VERSION "HNNBNNNYNNNNNNNNNNNNNNNNNNNNNNNNNNNNNNNNNN/4/%%%/4/'%**4NNN///"

NS_ :

BS_:

BU_: ICAS1_Gateway ICAS1_KommunikationsServer MFL_CAN

BO_ 3221225472 VECTOR__INDEPENDENT_SIG_MSG: 0 Vector__XXX
 SG_ MFL_Develop_Release : 0|3@1+ (1,0) [0|7] "" Vector__XXX
 SG_ MFL_Develop_Variant : 0|2@1+ (1,0) [0|3] "" Vector__XXX

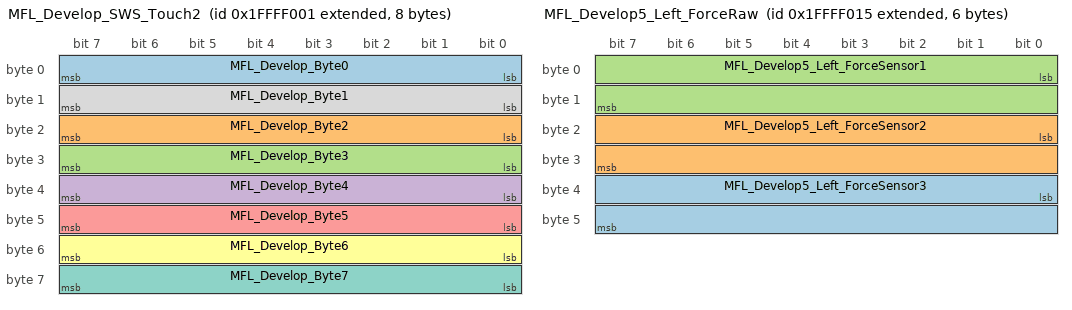
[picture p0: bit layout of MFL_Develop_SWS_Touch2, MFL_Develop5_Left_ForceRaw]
BO_ 2684350465 MFL_Develop_SWS_Touch2: 8 MFL_CAN
 SG_ MFL_Develop_Byte0 : 0|8@1+ (1,0) [0|255] ""  ICAS1_Gateway
 SG_ MFL_Develop_Byte2 : 16|8@1+ (1,0) [0|255] ""  ICAS1_Gateway
 SG_ MFL_Develop_Byte3 : 24|8@1+ (1,0) [0|255] ""  ICAS1_Gateway
 SG_ MFL_Develop_Byte4 : 32|8@1+ (1,0) [0|255] ""  ICAS1_Gateway
 SG_ MFL_Develop_Byte5 : 40|8@1+ (1,0) [0|255] ""  ICAS1_Gateway
 SG_ MFL_Develop_Byte6 : 48|8@1+ (1,0) [0|255] ""  ICAS1_Gateway
 SG_ MFL_Develop_Byte7 : 56|8@1+ (1,0) [0|255] ""  ICAS1_Gateway
 SG_ MFL_Develop_Byte1 : 8|8@1+ (1,0) [0|255] ""  ICAS1_Gateway

BO_ 2684350485 MFL_Develop5_Left_ForceRaw: 6 MFL_CAN
 SG_ MFL_Develop5_Left_ForceSensor3 : 32|16@1+ (1,0) [0|65535] "" Vector__XXX
 SG_ MFL_Develop5_Left_ForceSensor2 : 16|16@1+ (1,0) [0|65535] "" Vector__XXX
 SG_ MFL_Develop5_Left_ForceSensor1 : 0|16@1+ (1,0) [0|65535] "" Vector__XXX

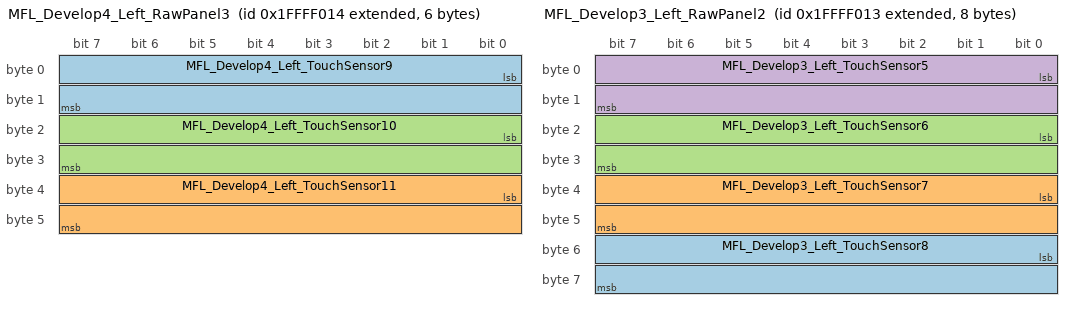
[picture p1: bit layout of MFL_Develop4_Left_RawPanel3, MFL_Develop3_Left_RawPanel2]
BO_ 2684350484 MFL_Develop4_Left_RawPanel3: 6 MFL_CAN
 SG_ MFL_Develop4_Left_TouchSensor9 : 0|16@1+ (1,0) [0|65535] "" Vector__XXX
 SG_ MFL_Develop4_Left_TouchSensor11 : 32|16@1+ (1,0) [0|65535] "" Vector__XXX
 SG_ MFL_Develop4_Left_TouchSensor10 : 16|16@1+ (1,0) [0|65535] "" Vector__XXX

BO_ 2684350483 MFL_Develop3_Left_RawPanel2: 8 MFL_CAN
 SG_ MFL_Develop3_Left_TouchSensor8 : 48|16@1+ (1,0) [0|65535] "" Vector__XXX
 SG_ MFL_Develop3_Left_TouchSensor7 : 32|16@1+ (1,0) [0|65535] "" Vector__XXX
 SG_ MFL_Develop3_Left_TouchSensor6 : 16|16@1+ (1,0) [0|65535] "" Vector__XXX
 SG_ MFL_Develop3_Left_TouchSensor5 : 0|16@1+ (1,0) [0|65535] "" Vector__XXX

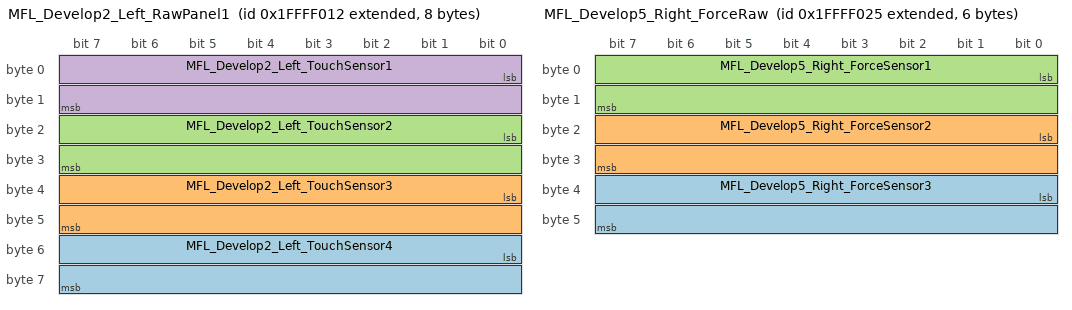
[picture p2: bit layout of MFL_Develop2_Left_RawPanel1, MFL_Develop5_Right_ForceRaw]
BO_ 2684350482 MFL_Develop2_Left_RawPanel1: 8 MFL_CAN
 SG_ MFL_Develop2_Left_TouchSensor4 : 48|16@1+ (1,0) [0|65535] "" Vector__XXX
 SG_ MFL_Develop2_Left_TouchSensor3 : 32|16@1+ (1,0) [0|65535] "" Vector__XXX
 SG_ MFL_Develop2_Left_TouchSensor2 : 16|16@1+ (1,0) [0|65535] "" Vector__XXX
 SG_ MFL_Develop2_Left_TouchSensor1 : 0|16@1+ (1,0) [0|65535] "" Vector__XXX

BO_ 2684350501 MFL_Develop5_Right_ForceRaw: 6 MFL_CAN
 SG_ MFL_Develop5_Right_ForceSensor3 : 32|16@1+ (1,0) [0|65535] "" Vector__XXX
 SG_ MFL_Develop5_Right_ForceSensor2 : 16|16@1+ (1,0) [0|65535] "" Vector__XXX
 SG_ MFL_Develop5_Right_ForceSensor1 : 0|16@1+ (1,0) [0|65535] "" Vector__XXX

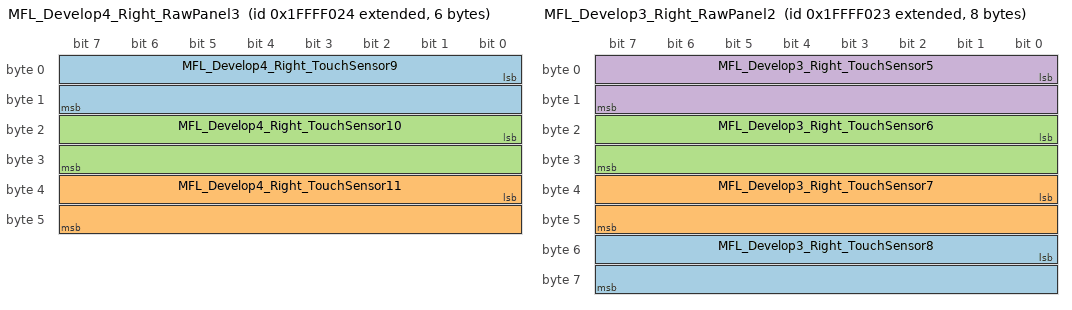
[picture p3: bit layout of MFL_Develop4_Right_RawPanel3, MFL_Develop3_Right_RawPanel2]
BO_ 2684350500 MFL_Develop4_Right_RawPanel3: 6 MFL_CAN
 SG_ MFL_Develop4_Right_TouchSensor9 : 0|16@1+ (1,0) [0|65535] "" Vector__XXX
 SG_ MFL_Develop4_Right_TouchSensor11 : 32|16@1+ (1,0) [0|65535] "" Vector__XXX
 SG_ MFL_Develop4_Right_TouchSensor10 : 16|16@1+ (1,0) [0|65535] "" Vector__XXX

BO_ 2684350499 MFL_Develop3_Right_RawPanel2: 8 MFL_CAN
 SG_ MFL_Develop3_Right_TouchSensor8 : 48|16@1+ (1,0) [0|65535] "" Vector__XXX
 SG_ MFL_Develop3_Right_TouchSensor7 : 32|16@1+ (1,0) [0|65535] "" Vector__XXX
 SG_ MFL_Develop3_Right_TouchSensor6 : 16|16@1+ (1,0) [0|65535] "" Vector__XXX
 SG_ MFL_Develop3_Right_TouchSensor5 : 0|16@1+ (1,0) [0|65535] "" Vector__XXX

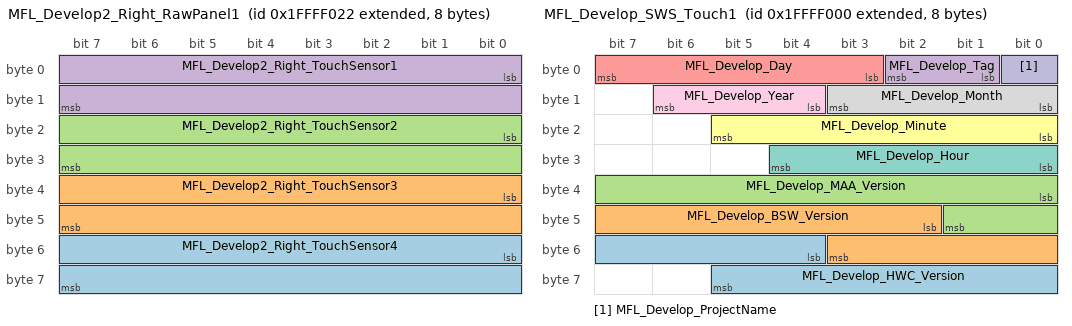
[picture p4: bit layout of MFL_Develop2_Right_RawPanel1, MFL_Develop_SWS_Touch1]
BO_ 2684350498 MFL_Develop2_Right_RawPanel1: 8 MFL_CAN
 SG_ MFL_Develop2_Right_TouchSensor4 : 48|16@1+ (1,0) [0|65535] "" Vector__XXX
 SG_ MFL_Develop2_Right_TouchSensor3 : 32|16@1+ (1,0) [0|65535] "" Vector__XXX
 SG_ MFL_Develop2_Right_TouchSensor2 : 16|16@1+ (1,0) [0|65535] "" Vector__XXX
 SG_ MFL_Develop2_Right_TouchSensor1 : 0|16@1+ (1,0) [0|65535] "" Vector__XXX

BO_ 2684350496 MFL_Develop1_SetPicState: 2 Vector__XXX
 SG_ MFL_Develop1_Left_PicState : 8|8@1+ (1,0) [0|4] ""  MFL_CAN
 SG_ MFL_Develop1_Right_PicState : 0|8@1+ (1,0) [0|4] ""  MFL_CAN

BO_ 2566664449 XCP_DTO_01: 8 MFL_CAN
 SG_ XCP_DTO_01_val : 0|64@1+ (1,0) [0|1.84467440737096E+019] "" Vector__XXX

BO_ 2566664448 XCP_CRO_01: 8 ICAS1_Gateway
 SG_ XCP_CRO_01_val : 0|64@1+ (1,0) [0|1.84467440737096E+019] ""  MFL_CAN

BO_ 2684350464 MFL_Develop_SWS_Touch1: 8 MFL_CAN
 SG_ MFL_Develop_HWC_Version : 52|10@1+ (1,0) [0|1023] "" Vector__XXX
 SG_ MFL_Develop_BSW_Version : 42|10@1+ (1,0) [0|1023] "" Vector__XXX
 SG_ MFL_Develop_MAA_Version : 32|10@1+ (1,0) [0|1023] "" Vector__XXX
 SG_ MFL_Develop_Tag : 1|2@1+ (1,0) [0|3] "" Vector__XXX
 SG_ MFL_Develop_Day : 3|5@1+ (1,0) [0|31] ""  ICAS1_Gateway
 SG_ MFL_Develop_Minute : 16|6@1+ (1,0) [0|61] ""  ICAS1_Gateway
 SG_ MFL_Develop_Hour : 24|5@1+ (1,0) [0|24] ""  ICAS1_Gateway
 SG_ MFL_Develop_Month : 8|4@1+ (1,0) [0|12] ""  ICAS1_Gateway
 SG_ MFL_Develop_Year : 12|3@1+ (1,0) [0|7] ""  ICAS1_Gateway
 SG_ MFL_Develop_ProjectName : 0|1@1+ (1,0) [0|1] ""  ICAS1_Gateway

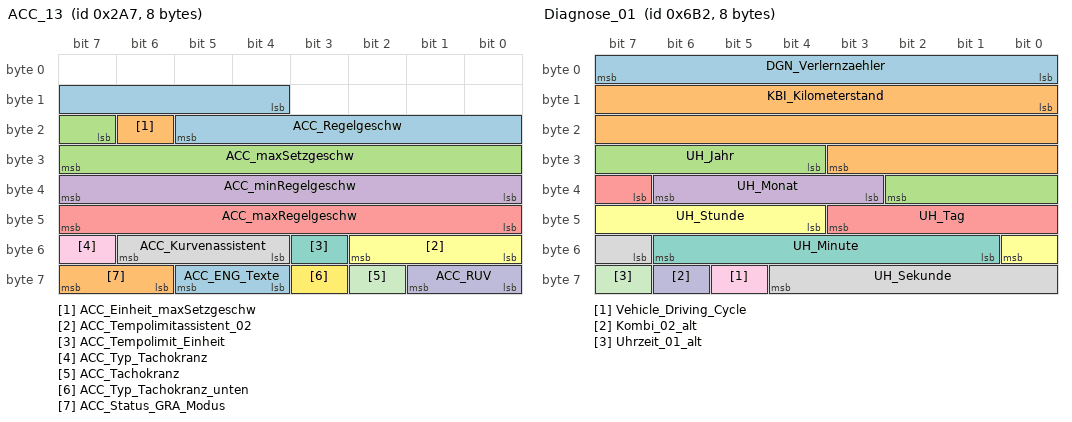
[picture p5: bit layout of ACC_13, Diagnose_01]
BO_ 679 ACC_13: 8 ICAS1_Gateway
 SG_ ACC_Regelgeschw : 12|10@1+ (0.32,0) [0|327.04] "Unit_KiloMeterPerHour" Vector__XXX
 SG_ ACC_Einheit_maxSetzgeschw : 22|1@1+ (1,0) [0|1] "" Vector__XXX
 SG_ ACC_maxSetzgeschw : 23|9@1+ (1,0) [0|510] "" Vector__XXX
 SG_ ACC_minRegelgeschw : 32|8@1+ (0.32,0) [0|81.28] "Unit_KiloMeterPerHour" Vector__XXX
 SG_ ACC_maxRegelgeschw : 40|8@1+ (0.32,0) [0|81.28] "Unit_KiloMeterPerHour" Vector__XXX
 SG_ ACC_Tempolimitassistent_02 : 48|3@1+ (1,0) [0|7] "" Vector__XXX
 SG_ ACC_Tempolimit_Einheit : 51|1@1+ (1,0) [0|1] "" Vector__XXX
 SG_ ACC_Kurvenassistent : 52|3@1+ (1,0) [0|7] "" Vector__XXX
 SG_ ACC_Typ_Tachokranz : 55|1@1+ (1,0) [0|1] "" Vector__XXX
 SG_ ACC_RUV : 56|2@1+ (1,0) [0|3] "" Vector__XXX
 SG_ ACC_Tachokranz : 58|1@1+ (1,0) [0|1] "" Vector__XXX
 SG_ ACC_Typ_Tachokranz_unten : 59|1@1+ (1,0) [0|1] "" Vector__XXX
 SG_ ACC_ENG_Texte : 60|2@1+ (1,0) [0|3] "" Vector__XXX
 SG_ ACC_Status_GRA_Modus : 62|2@1+ (1,0) [0|3] ""  MFL_CAN

BO_ 680 ACC_14: 8 ICAS1_Gateway
 SG_ ACA_Querfuehrung_Texte : 0|3@1+ (1,0) [0|7] "" Vector__XXX
 SG_ ACA_Hinweistexte : 3|3@1+ (1,0) [0|7] "" Vector__XXX
 SG_ ACC_FoD_Status : 6|2@1+ (1,0) [0|3] ""  MFL_CAN
 SG_ ACC_Texte_Abstandswarner : 8|2@1+ (1,0) [0|3] "" Vector__XXX
 SG_ ACC_Vorz_Abstandswarner : 10|2@1+ (1,0) [0|3] "" Vector__XXX
 SG_ ACC_Texte_Sekundaeranz : 12|4@1+ (1,0) [0|15] "" Vector__XXX
 SG_ ACC_Status_Anzeige : 16|3@1+ (1,0) [0|7] "" Vector__XXX
 SG_ ACC_Akustik_03 : 19|3@1+ (1,0) [0|7] "" Vector__XXX
 SG_ ACC_Geschw_Zielfahrzeug : 22|10@1+ (0.32,0) [0|326.72] "Unit_KiloMeterPerHour" Vector__XXX
 SG_ ACC_Texte_02 : 32|6@1+ (1,0) [0|63] "" Vector__XXX
 SG_ ACC_STA_Text : 38|1@1+ (1,0) [0|1] "" Vector__XXX
 SG_ ACC_Status_Stauende : 39|1@1+ (1,0) [0|1] "" Vector__XXX
 SG_ STA_Texte : 40|3@1+ (1,0) [0|7] "" Vector__XXX
 SG_ AbstWarn_LRR_FAS_Fkt_Status : 43|2@1+ (1,0) [0|3] "" Vector__XXX
 SG_ STA_Zusatzanz : 45|2@1+ (1,0) [0|3] "" Vector__XXX
 SG_ FAS_Licht_Anf : 47|1@1+ (1,0) [0|1] "" Vector__XXX
 SG_ ACC_Zeitluecke_Abstandswarner : 48|6@1+ (0.1,0) [0|6] "Unit_Secon" Vector__XXX
 SG_ ACC_Abstand_Abstandswarner : 54|9@1+ (1,0) [0|508] "" Vector__XXX
 SG_ ACC_Einheit_Abstandswarner : 63|1@1+ (1,0) [0|1] "" Vector__XXX

BO_ 2549880369 DIA_MFL_Req: 8 ICAS1_Gateway
 SG_ DIA_MFL_Req_Data : 0|64@1+ (1,0) [0|1.84467440737096E+019] ""  MFL_CAN

BO_ 2550011441 DIA_MFL_Resp: 8 MFL_CAN
 SG_ DIA_MFL_Resp_Data : 0|64@1+ (1,0) [0|1.84467440737096E+019] ""  ICAS1_Gateway

BO_ 2549876273 Diag_MFL_Req: 8 ICAS1_Gateway
 SG_ Diag_MFL_Req_Data : 0|64@1+ (1,0) [0|1.84467440737096E+019] ""  MFL_CAN

BO_ 2550007345 Diag_MFL_Resp: 8 MFL_CAN
 SG_ Diag_MFL_Resp_Data : 0|64@1+ (1,0) [0|1.84467440737096E+019] ""  ICAS1_Gateway

BO_ 1714 Diagnose_01: 8 ICAS1_Gateway
 SG_ DGN_Verlernzaehler : 0|8@1+ (1,0) [0|254] "" Vector__XXX
 SG_ KBI_Kilometerstand : 8|20@1+ (1,0) [0|1048573] "Unit_KiloMeter" Vector__XXX
 SG_ UH_Jahr : 28|7@1+ (1,2000) [2000|2127] "Unit_Year" Vector__XXX
 SG_ UH_Monat : 35|4@1+ (1,0) [1|12] "Unit_Month" Vector__XXX
 SG_ UH_Tag : 39|5@1+ (1,0) [1|31] "Unit_Day" Vector__XXX
 SG_ UH_Stunde : 44|5@1+ (1,0) [0|23] "Unit_Hours" Vector__XXX
 SG_ UH_Minute : 49|6@1+ (1,0) [0|59] "Unit_Minut" Vector__XXX
 SG_ UH_Sekunde : 55|6@1+ (1,0) [0|59] "Unit_Secon" Vector__XXX
 SG_ Vehicle_Driving_Cycle : 61|1@1+ (1,0) [0|1] "" Vector__XXX
 SG_ Kombi_02_alt : 62|1@1+ (1,0) [0|1] "" Vector__XXX
 SG_ Uhrzeit_01_alt : 63|1@1+ (1,0) [0|1] "" Vector__XXX

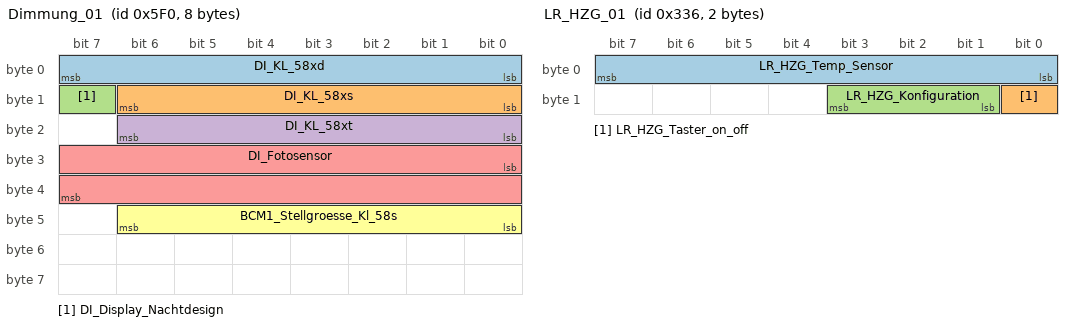
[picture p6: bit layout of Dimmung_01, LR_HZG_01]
BO_ 1520 Dimmung_01: 8 ICAS1_Gateway
 SG_ DI_KL_58xd : 0|8@1+ (1,0) [0|253] ""  MFL_CAN
 SG_ DI_KL_58xs : 8|7@1+ (1,0) [0|100] "Unit_PerCent" Vector__XXX
 SG_ DI_Display_Nachtdesign : 15|1@1+ (1,0) [0|1] "" Vector__XXX
 SG_ DI_KL_58xt : 16|7@1+ (1,0) [0|100] "Unit_PerCent"  MFL_CAN
 SG_ DI_Fotosensor : 24|16@1+ (1,0) [0|65535] "" Vector__XXX
 SG_ BCM1_Stellgroesse_Kl_58s : 40|7@1+ (1,0) [0|100] "" Vector__XXX

BO_ 988 Gateway_73: 8 ICAS1_Gateway
 SG_ Motor_12_alt : 0|1@1+ (1,0) [0|1] "" Vector__XXX
 SG_ ESP_07_alt : 1|1@1+ (1,0) [0|1] "" Vector__XXX
 SG_ Getriebe_11_alt : 2|1@1+ (1,0) [0|1] "" Vector__XXX
 SG_ Getriebe_13_alt : 3|1@1+ (1,0) [0|1] "" Vector__XXX
 SG_ Getriebe_17_alt : 4|1@1+ (1,0) [0|1] "" Vector__XXX
 SG_ TSK_06_alt : 5|1@1+ (1,0) [0|1] ""  MFL_CAN
 SG_ Getriebe_14_alt : 6|1@1+ (1,0) [0|1] "" Vector__XXX
 SG_ ESP_50_alt : 7|1@1+ (1,0) [0|1] "" Vector__XXX
 SG_ MO_QBit_Drehzahl_01 : 8|1@1+ (1,0) [0|1] "" Vector__XXX
 SG_ MKE_Texte : 9|2@1+ (1,0) [0|3] "" Vector__XXX
 SG_ MKE_Stufe : 11|3@1+ (1,0) [0|7] "" Vector__XXX
 SG_ TSK_Hauptschalter_GRA_ACC : 14|2@1+ (1,0) [0|3] ""  MFL_CAN
 SG_ MO_Drehzahl_01 : 16|16@1+ (0.25,0) [0|16383] "Unit_MinutInver" Vector__XXX
 SG_ GE_Fahrstufe : 40|4@1+ (1,0) [0|15] "" Vector__XXX
 SG_ GE_Ursache_Fahrstufe_N : 44|1@1+ (1,0) [0|1] "" Vector__XXX
 SG_ GE_Notlauf : 45|1@1+ (1,0) [0|1] "" Vector__XXX
 SG_ ESP_Rollenmodus_Deaktivieren : 46|1@1+ (1,0) [0|1] "" Vector__XXX
 SG_ GE_Freilauf_Status : 47|3@1+ (1,0) [0|7] "" Vector__XXX
 SG_ GE_Sperr_Info_WFS : 50|1@1+ (1,0) [0|1] "" Vector__XXX
 SG_ TSK_Limiter_ausgewaehlt : 51|1@1+ (1,0) [0|1] ""  MFL_CAN
 SG_ EPB_Status_02 : 53|3@1+ (1,0) [0|7] "" Vector__XXX
 SG_ ACC_Status_ACC : 56|3@1+ (1,0) [0|7] "" Vector__XXX
 SG_ ACC_18_alt : 59|1@1+ (1,0) [0|1] "" Vector__XXX
 SG_ ESP_Status_Bremsentemp_02 : 62|2@1+ (1,0) [0|3] "" Vector__XXX

BO_ 299 GRA_ACC_01: 8 MFL_CAN
 SG_ GRA_ACC_01_CRC : 0|8@1+ (1,0) [0|255] ""  ICAS1_Gateway
 SG_ GRA_ACC_01_BZ : 8|4@1+ (1,0) [0|15] ""  ICAS1_Gateway
 SG_ GRA_Hauptschalter : 12|1@1+ (1,0) [0|1] ""  ICAS1_Gateway
 SG_ GRA_Abbrechen : 13|1@1+ (1,0) [0|1] ""  ICAS1_Gateway
 SG_ GRA_Typ_Hauptschalter : 14|1@1+ (1,0) [0|1] ""  ICAS1_Gateway
 SG_ GRA_Limiter : 15|1@1+ (1,0) [0|1] ""  ICAS1_Gateway
 SG_ GRA_Tip_Setzen : 16|1@1+ (1,0) [0|1] ""  ICAS1_Gateway
 SG_ GRA_Tip_Hoch : 17|1@1+ (1,0) [0|1] ""  ICAS1_Gateway
 SG_ GRA_Tip_Runter : 18|1@1+ (1,0) [0|1] ""  ICAS1_Gateway
 SG_ GRA_Tip_Wiederaufnahme : 19|1@1+ (1,0) [0|1] ""  ICAS1_Gateway
 SG_ GRA_Verstellung_Zeitluecke : 20|2@1+ (1,0) [0|3] ""  ICAS1_Gateway
 SG_ GRA_Codierung : 22|2@1+ (1,0) [0|3] ""  ICAS1_Gateway
 SG_ GRA_Fehler : 24|1@1+ (1,0) [0|1] ""  ICAS1_Gateway
 SG_ GRA_LIM_Taste_verfuegbar : 25|1@1+ (1,0) [0|1] ""  ICAS1_Gateway,ICAS1_KommunikationsServer
 SG_ GRA_Tip_Stufe_2 : 26|1@1+ (1,0) [0|1] ""  ICAS1_Gateway
 SG_ GRA_Typ_Bedienteil : 27|3@1+ (1,0) [0|7] ""  ICAS1_Gateway
 SG_ GRA_TravelAssist : 30|1@1+ (1,0) [0|1] ""  ICAS1_Gateway
 SG_ GRA_reserveByte4 : 31|1@1+ (1,0) [0|1] ""  ICAS1_Gateway
 SG_ GRA_reserveByte5 : 32|8@1+ (1,0) [0|255] ""  ICAS1_Gateway
 SG_ GRA_reserveByte6 : 40|8@1+ (1,0) [0|255] ""  ICAS1_Gateway
 SG_ GRA_reserveByte7 : 48|8@1+ (1,0) [0|255] ""  ICAS1_Gateway
 SG_ GRA_reserveByte8 : 56|8@1+ (1,0) [0|255] ""  ICAS1_Gateway

BO_ 960 Klemmen_Status_01: 4 ICAS1_Gateway
 SG_ Klemmen_Status_01_CRC : 0|8@1+ (1,0) [0|255] "" Vector__XXX
 SG_ Klemmen_Status_01_BZ : 8|4@1+ (1,0) [0|15] "" Vector__XXX
 SG_ RSt_Fahrerhinweise : 12|4@1+ (1,0) [0|15] "" Vector__XXX
 SG_ ZAS_Kl_S : 16|1@1+ (1,0) [0|1] "" Vector__XXX
 SG_ ZAS_Kl_15 : 17|1@1+ (1,0) [0|1] ""  MFL_CAN
 SG_ ZAS_Kl_X : 18|1@1+ (1,0) [0|1] "" Vector__XXX
 SG_ ZAS_Kl_50_Startanforderung : 19|1@1+ (1,0) [0|1] "" Vector__XXX
 SG_ BCM_Remotestart_Betrieb : 20|1@1+ (1,0) [0|1] "" Vector__XXX
 SG_ ZAS_Kl_Infotainment : 21|1@1+ (1,0) [0|1] "" Vector__XXX
 SG_ BCM_Remotestart_KL15_Anf : 22|1@1+ (1,0) [0|1] "" Vector__XXX
 SG_ BCM_Remotestart_MO_Start : 23|1@1+ (1,0) [0|1] "" Vector__XXX
 SG_ KST_Warn_P1_ZST_def : 24|1@1+ (1,0) [0|1] "" Vector__XXX
 SG_ KST_Warn_P2_ZST_def : 25|1@1+ (1,0) [0|1] "" Vector__XXX
 SG_ KST_Fahrerhinweis_1 : 26|1@1+ (1,0) [0|1] "" Vector__XXX
 SG_ KST_Fahrerhinweis_2 : 27|1@1+ (1,0) [0|1] "" Vector__XXX
 SG_ BCM_Ausparken_Betrieb : 28|1@1+ (1,0) [0|1] "" Vector__XXX
 SG_ KST_Fahrerhinweis_4 : 29|1@1+ (1,0) [0|1] "" Vector__XXX
 SG_ KST_Fahrerhinweis_5 : 30|1@1+ (1,0) [0|1] "" Vector__XXX
 SG_ KST_Fahrerhinweis_6 : 31|1@1+ (1,0) [0|1] "" Vector__XXX

BO_ 822 LR_HZG_01: 2 MFL_CAN
 SG_ LR_HZG_Temp_Sensor : 0|8@1+ (1,-50) [-50|104] "Unit_DegreCelsi"  ICAS1_Gateway
 SG_ LR_HZG_Taster_on_off : 8|1@1+ (1,0) [0|1] ""  ICAS1_Gateway
 SG_ LR_HZG_Konfiguration : 9|3@1+ (1,0) [0|7] ""  ICAS1_Gateway

BO_ 817 MFL_01: 8 MFL_CAN
 SG_ MFL_Zaehler : 0|4@1+ (1,0) [0|15] ""  ICAS1_Gateway
 SG_ MFL_Toggle : 4|1@1+ (1,0) [0|1] ""  ICAS1_Gateway
 SG_ MFL_Lokalaktiv : 5|1@1+ (1,0) [0|1] ""  ICAS1_Gateway
 SG_ MFL_M_Taste : 6|1@1+ (1,0) [0|1] ""  ICAS1_Gateway
 SG_ MFL_Paddle_Verbau : 7|1@1+ (1,0) [0|1] ""  ICAS1_Gateway
 SG_ MFL_Tastencode_1 : 8|8@1+ (1,0) [0|255] ""  ICAS1_Gateway
 SG_ MFL_Tastencode_2 : 16|8@1+ (1,0) [0|255] ""  ICAS1_Gateway
 SG_ MFL_Eventcode_1 : 24|4@1+ (1,0) [0|15] ""  ICAS1_Gateway
 SG_ MFL_Eventcode_2 : 28|4@1+ (1,0) [0|15] ""  ICAS1_Gateway
 SG_ MFL_Marke : 32|4@1+ (1,0) [0|15] ""  ICAS1_Gateway
 SG_ MFL_Variante : 36|4@1+ (1,0) [0|15] ""  ICAS1_Gateway
 SG_ MFL_Dummy_0_Signal_1 : 40|8@1+ (1,0) [0|255] ""  ICAS1_Gateway
 SG_ MFL_Tip_Down : 48|1@1+ (1,0) [0|1] ""  ICAS1_Gateway
 SG_ MFL_Tip_Up : 49|1@1+ (1,0) [0|1] ""  ICAS1_Gateway
 SG_ MFL_SatModul_links_Err : 50|1@1+ (1,0) [0|1] ""  ICAS1_Gateway
 SG_ MFL_SatModul_rechts_Err : 51|1@1+ (1,0) [0|1] ""  ICAS1_Gateway
 SG_ MFL_Dummy_0_Signal_2 : 52|1@1+ (1,0) [0|1] ""  ICAS1_Gateway
 SG_ MFL_Dummy_0_Signal_3 : 53|1@1+ (1,0) [0|1] ""  ICAS1_Gateway
 SG_ MFL_LR_HZG_Status : 54|1@1+ (1,0) [0|1] ""  ICAS1_Gateway
 SG_ MFL_LR_HZG_Err : 55|1@1+ (1,0) [0|1] ""  ICAS1_Gateway
 SG_ MFL_Signalhorn : 56|1@1+ (1,0) [0|1] ""  ICAS1_Gateway
 SG_ MFL_Signalhorn_Err : 57|1@1+ (1,0) [0|1] ""  ICAS1_Gateway
 SG_ MFL_Tip_links_Err : 58|1@1+ (1,0) [0|1] ""  ICAS1_Gateway
 SG_ MFL_Tip_rechts_Err : 59|1@1+ (1,0) [0|1] ""  ICAS1_Gateway
 SG_ MFL_Taste_links_Err : 60|1@1+ (1,0) [0|1] ""  ICAS1_Gateway
 SG_ MFL_Taste_rechts_Err : 61|1@1+ (1,0) [0|1] ""  ICAS1_Gateway
 SG_ MFL_ECU_Err : 62|1@1+ (1,0) [0|1] ""  ICAS1_Gateway
 SG_ MFL_Response_Err : 63|1@1+ (1,0) [0|1] ""  ICAS1_Gateway

BO_ 560 MFL_02: 8 MFL_CAN
 SG_ MFL_Beruehrungserkennung : 12|2@1+ (1,0) [0|3] ""  ICAS1_Gateway

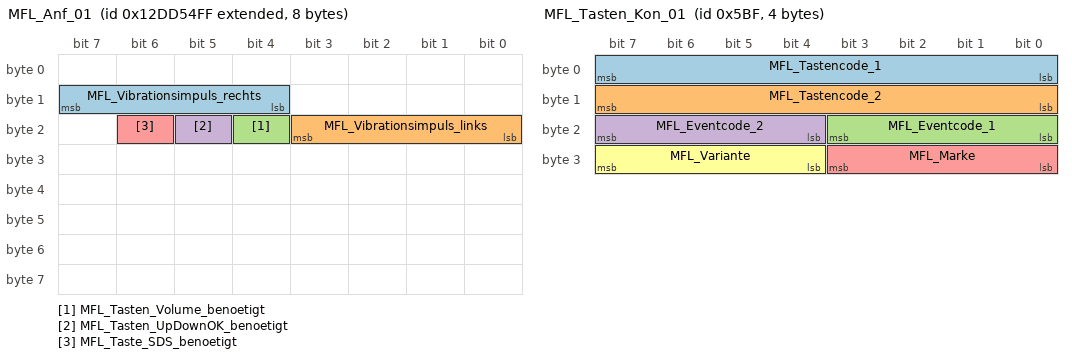
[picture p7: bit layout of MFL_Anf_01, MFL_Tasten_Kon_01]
BO_ 2463978751 MFL_Anf_01: 8 ICAS1_Gateway
 SG_ MFL_Vibrationsimpuls_rechts : 12|4@1+ (1,0) [0|15] ""  MFL_CAN
 SG_ MFL_Vibrationsimpuls_links : 16|4@1+ (1,0) [0|15] ""  MFL_CAN
 SG_ MFL_Tasten_Volume_benoetigt : 20|1@1+ (1,0) [0|1] ""  MFL_CAN
 SG_ MFL_Tasten_UpDownOK_benoetigt : 21|1@1+ (1,0) [0|1] ""  MFL_CAN
 SG_ MFL_Taste_SDS_benoetigt : 22|1@1+ (1,0) [0|1] ""  MFL_CAN

BO_ 1471 MFL_Tasten_Kon_01: 4 MFL_CAN
 SG_ MFL_Tastencode_1 : 0|8@1+ (1,0) [0|255] ""  ICAS1_Gateway
 SG_ MFL_Tastencode_2 : 8|8@1+ (1,0) [0|255] ""  ICAS1_Gateway
 SG_ MFL_Eventcode_1 : 16|4@1+ (1,0) [0|15] ""  ICAS1_Gateway
 SG_ MFL_Eventcode_2 : 20|4@1+ (1,0) [0|15] ""  ICAS1_Gateway
 SG_ MFL_Marke : 24|4@1+ (1,0) [0|15] ""  ICAS1_Gateway
 SG_ MFL_Variante : 28|4@1+ (1,0) [0|15] ""  ICAS1_Gateway

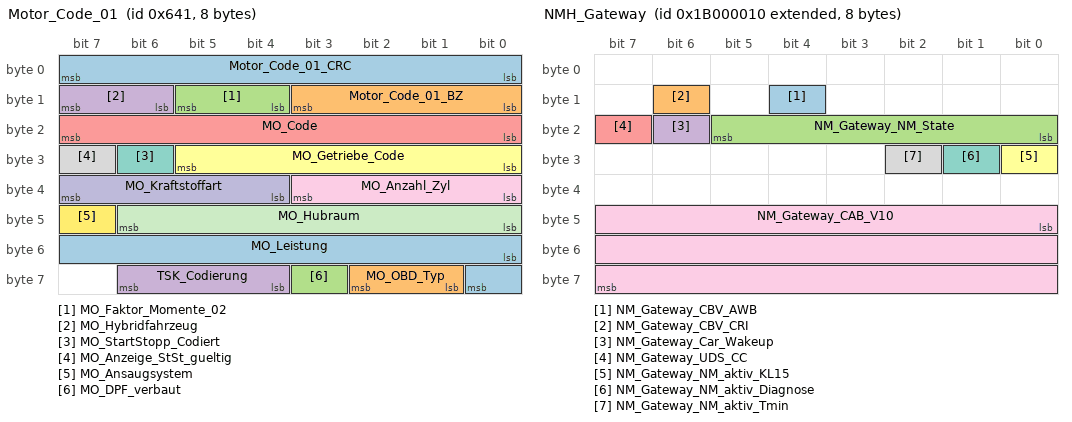
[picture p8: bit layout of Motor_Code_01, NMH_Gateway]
BO_ 1601 Motor_Code_01: 8 ICAS1_Gateway
 SG_ Motor_Code_01_CRC : 0|8@1+ (1,0) [0|255] "" Vector__XXX
 SG_ Motor_Code_01_BZ : 8|4@1+ (1,0) [0|15] "" Vector__XXX
 SG_ MO_Faktor_Momente_02 : 12|2@1+ (1,0) [1|3] "Unit_NewtoMeter" Vector__XXX
 SG_ MO_Hybridfahrzeug : 14|2@1+ (1,0) [0|3] "" Vector__XXX
 SG_ MO_Code : 16|8@1+ (1,0) [0|255] "" Vector__XXX
 SG_ MO_Getriebe_Code : 24|6@1+ (1,0) [0|63] "" Vector__XXX
 SG_ MO_StartStopp_Codiert : 30|1@1+ (1,0) [0|1] "" Vector__XXX
 SG_ MO_Anzeige_StSt_gueltig : 31|1@1+ (1,0) [0|1] "" Vector__XXX
 SG_ MO_Anzahl_Zyl : 32|4@1+ (1,0) [0|15] "" Vector__XXX
 SG_ MO_Kraftstoffart : 36|4@1+ (1,0) [0|15] "" Vector__XXX
 SG_ MO_Hubraum : 40|7@1+ (0.1,0) [0|12.7] "Unit_Liter" Vector__XXX
 SG_ MO_Ansaugsystem : 47|1@1+ (1,0) [0|1] "" Vector__XXX
 SG_ MO_Leistung : 48|9@1+ (1,0) [0|511] "Unit_KiloWatt" Vector__XXX
 SG_ MO_OBD_Typ : 57|2@1+ (1,0) [0|3] "" Vector__XXX
 SG_ MO_DPF_verbaut : 59|1@1+ (1,0) [0|1] "" Vector__XXX
 SG_ TSK_Codierung : 60|3@1+ (1,0) [0|7] ""  MFL_CAN

BO_ 2600468496 NMH_Gateway: 8 ICAS1_Gateway
 SG_ NM_Gateway_CBV_AWB : 12|1@1+ (1,0) [0|1] "" Vector__XXX
 SG_ NM_Gateway_CBV_CRI : 14|1@1+ (1,0) [0|1] "" Vector__XXX
 SG_ NM_Gateway_NM_State : 16|6@1+ (1,0) [0|63] ""  MFL_CAN
 SG_ NM_Gateway_Car_Wakeup : 22|1@1+ (1,0) [0|1] "" Vector__XXX
 SG_ NM_Gateway_UDS_CC : 23|1@1+ (1,0) [0|1] "" Vector__XXX
 SG_ NM_Gateway_NM_aktiv_KL15 : 24|1@1+ (1,0) [0|1] "" Vector__XXX
 SG_ NM_Gateway_NM_aktiv_Diagnose : 25|1@1+ (1,0) [0|1] "" Vector__XXX
 SG_ NM_Gateway_NM_aktiv_Tmin : 26|1@1+ (1,0) [0|1] "" Vector__XXX
 SG_ NM_Gateway_CAB_V10 : 40|24@1+ (1,0) [0|16777215] "" Vector__XXX

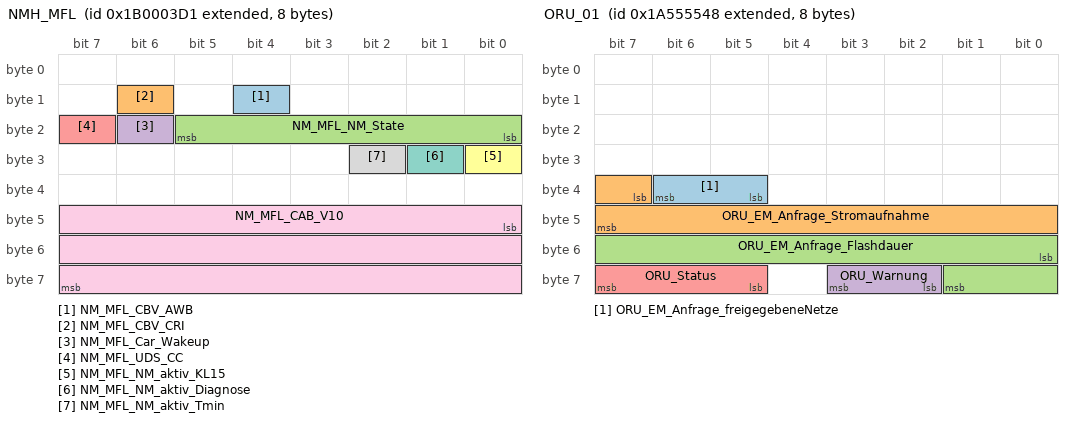
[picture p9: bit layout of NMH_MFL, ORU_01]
BO_ 2600469457 NMH_MFL: 8 MFL_CAN
 SG_ NM_MFL_CBV_AWB : 12|1@1+ (1,0) [0|1] ""  ICAS1_Gateway
 SG_ NM_MFL_CBV_CRI : 14|1@1+ (1,0) [0|1] ""  ICAS1_Gateway
 SG_ NM_MFL_NM_State : 16|6@1+ (1,0) [0|63] ""  MFL_CAN
 SG_ NM_MFL_Car_Wakeup : 22|1@1+ (1,0) [0|1] ""  ICAS1_Gateway
 SG_ NM_MFL_UDS_CC : 23|1@1+ (1,0) [0|1] "" Vector__XXX
 SG_ NM_MFL_NM_aktiv_KL15 : 24|1@1+ (1,0) [0|1] "" Vector__XXX
 SG_ NM_MFL_NM_aktiv_Diagnose : 25|1@1+ (1,0) [0|1] "" Vector__XXX
 SG_ NM_MFL_NM_aktiv_Tmin : 26|1@1+ (1,0) [0|1] "" Vector__XXX
 SG_ NM_MFL_CAB_V10 : 40|24@1+ (1,0) [0|16777215] ""  ICAS1_Gateway

BO_ 2549903409 OBDC_SSN_MFL_Req: 8 ICAS1_Gateway
 SG_ OBDC_SSN_MFL_Req_Data : 0|64@1+ (1,0) [0|1.84467440737096E+019] ""  MFL_CAN

BO_ 2550034481 OBDC_SSN_MFL_Resp: 8 MFL_CAN
 SG_ OBDC_SSN_MFL_Resp_Data : 0|64@1+ (1,0) [0|1.84467440737096E+019] ""  ICAS1_Gateway

BO_ 2564502513 OBDx_allOBD_Req: 8 ICAS1_Gateway
 SG_ OBDx_allOBD_Req_Data : 0|64@1+ (1,0) [0|1.84467440737096E+019] "" Vector__XXX

BO_ 2589283656 ORU_01: 8 ICAS1_KommunikationsServer
 SG_ ORU_EM_Anfrage_freigegebeneNetze : 37|2@1+ (1,0) [0|3] "" Vector__XXX
 SG_ ORU_EM_Anfrage_Stromaufnahme : 39|9@1+ (0.1,0) [0|51.1] "Unit_Amper" Vector__XXX
 SG_ ORU_EM_Anfrage_Flashdauer : 48|10@1+ (10,0) [0|10230] "Unit_Secon" Vector__XXX
 SG_ ORU_Warnung : 58|2@1+ (1,0) [0|3] "" Vector__XXX
 SG_ ORU_Status : 61|3@1+ (1,0) [0|7] ""  MFL_CAN

BO_ 1413 Systeminfo_01: 8 ICAS1_Gateway
 SG_ SI_Sammel_SG_Fehler : 0|6@1+ (1,0) [0|60] "" Vector__XXX
 SG_ SI_P_Mode_gueltig : 6|1@1+ (1,0) [0|1] "" Vector__XXX
 SG_ SI_Diagnose_Aktiv : 7|1@1+ (1,0) [0|1] "" Vector__XXX
 SG_ SI_QRS_Mode : 8|1@1+ (1,0) [0|1] "" Vector__XXX
 SG_ SI_T_Mode : 9|1@1+ (1,0) [0|1] "" Vector__XXX
 SG_ SI_NWDF : 10|1@1+ (1,0) [0|1] "" Vector__XXX
 SG_ SI_NWDF_gueltig : 11|1@1+ (1,0) [0|1] "" Vector__XXX
 SG_ SI_Sammelfehler : 12|1@1+ (1,0) [0|1] "" Vector__XXX
 SG_ GW_KD_Fehler : 13|1@1+ (1,0) [0|1] "" Vector__XXX
 SG_ SI_T_Schutz : 14|1@1+ (1,0) [0|1] "" Vector__XXX
 SG_ SI_P_Mode : 15|1@1+ (1,0) [0|1] "" Vector__XXX
 SG_ SI_BUS_01 : 16|1@1+ (1,0) [0|1] "" Vector__XXX
 SG_ SI_BUS_02 : 17|1@1+ (1,0) [0|1] "" Vector__XXX
 SG_ SI_BUS_03 : 18|1@1+ (1,0) [0|1] "" Vector__XXX
 SG_ SI_BUS_04 : 19|1@1+ (1,0) [0|1] "" Vector__XXX
 SG_ SI_BUS_05 : 20|1@1+ (1,0) [0|1] "" Vector__XXX
 SG_ SI_BUS_06 : 21|1@1+ (1,0) [0|1] "" Vector__XXX
 SG_ SI_BUS_07 : 22|1@1+ (1,0) [0|1] "" Vector__XXX
 SG_ SI_BUS_08 : 23|1@1+ (1,0) [0|1] "" Vector__XXX
 SG_ SI_BUS_09 : 24|1@1+ (1,0) [0|1] "" Vector__XXX
 SG_ SI_BUS_10 : 25|1@1+ (1,0) [0|1] "" Vector__XXX
 SG_ SI_BUS_11 : 26|1@1+ (1,0) [0|1] "" Vector__XXX
 SG_ SI_BUS_12 : 27|1@1+ (1,0) [0|1] "" Vector__XXX
 SG_ SI_BUS_13 : 28|1@1+ (1,0) [0|1] "" Vector__XXX
 SG_ SI_BUS_14 : 29|1@1+ (1,0) [0|1] "" Vector__XXX
 SG_ SI_BUS_15 : 30|1@1+ (1,0) [0|1] "" Vector__XXX
 SG_ SI_Bus_Identifikation : 32|8@1+ (1,0) [0|255] "" Vector__XXX
 SG_ SI_CAB_V10 : 40|24@1+ (1,0) [0|16777215] "" Vector__XXX

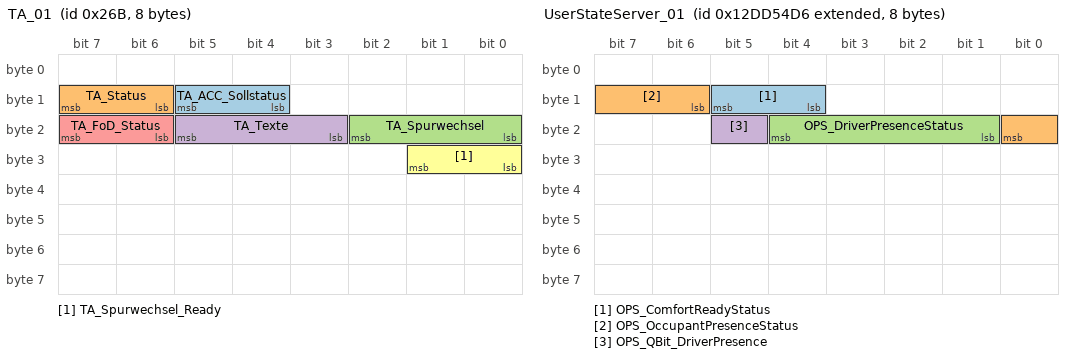
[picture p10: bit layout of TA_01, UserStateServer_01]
BO_ 619 TA_01: 8 ICAS1_Gateway
 SG_ TA_ACC_Sollstatus : 12|2@1+ (1,0) [0|3] "" Vector__XXX
 SG_ TA_Status : 14|2@1+ (1,0) [0|3] "" Vector__XXX
 SG_ TA_Spurwechsel : 16|3@1+ (1,0) [0|7] "" Vector__XXX
 SG_ TA_Texte : 19|3@1+ (1,0) [0|7] "" Vector__XXX
 SG_ TA_FoD_Status : 22|2@1+ (1,0) [0|3] ""  MFL_CAN
 SG_ TA_Spurwechsel_Ready : 24|2@1+ (1,0) [0|3] "" Vector__XXX

BO_ 2463978710 UserStateServer_01: 8 ICAS1_Gateway
 SG_ OPS_ComfortReadyStatus : 12|2@1+ (1,0) [0|3] ""  MFL_CAN
 SG_ OPS_OccupantPresenceStatus : 14|3@1+ (1,0) [0|7] "" Vector__XXX
 SG_ OPS_DriverPresenceStatus : 17|4@1+ (1,0) [0|15] "" Vector__XXX
 SG_ OPS_QBit_DriverPresence : 21|1@1+ (1,0) [0|1] "" Vector__XXX

CM_ "MEB_MFLCAN_V10.05F Generated by BusNet_NG_Produktiv 9.10.2";
CM_ BU_ ICAS1_Gateway "ICAS1 MEB
DFL-Kürzel: Gateway";
CM_ BU_ MFL_CAN "Steuergerät für Multifunktionslenkrad (CAN)";
CM_ BO_ 3221225472 "This is a message for not used signals, created by Vector CANdb++ DBC OLE DB Provider.";
CM_ BO_ 2684350485 "Developer message of MFL_CAN with SW version info.";
CM_ BO_ 2684350484 "Developer message of MFL_CAN with SW version info.";
CM_ BO_ 2684350483 "Developer message of MFL_CAN with SW version info.";
CM_ BO_ 2684350482 "Developer message of MFL_CAN with SW version info.";
CM_ BO_ 2684350501 "Developer message of MFL_CAN with SW version info.";
CM_ BO_ 2684350500 "Developer message of MFL_CAN with SW version info.";
CM_ BO_ 2684350499 "Developer message of MFL_CAN with SW version info.";
CM_ BO_ 2684350498 "Developer message of MFL_CAN with SW version info.";
CM_ BO_ 2684350496 "Developer message of MFL_CAN with SW version info.";
CM_ BO_ 2684350464 "Developer message of MFL_CAN with SW version info.";
CM_ SG_ 2684350464 MFL_Develop_Day "day";
CM_ SG_ 2684350464 MFL_Develop_Minute "minute";
CM_ SG_ 2684350464 MFL_Develop_Hour "hour";
CM_ SG_ 2684350464 MFL_Develop_Year "Year of created SW version";
CM_ SG_ 679 ACC_Regelgeschw "Zur Anzeige der Regelgeschwindigkeit (z.B. Kurven- / Tempolimitassistent) im Kombiinstrument";
CM_ SG_ 679 ACC_Einheit_maxSetzgeschw "Einheit zu Signal ACC_maxSetzgeschw";
CM_ SG_ 679 ACC_maxSetzgeschw "maximale ACC-Setzgeschwindigkeit zur Ansteuerung des ACC-Setzbereichs im Kombi
Hinweis: Signal ist mit Signal ACC_Einheit_maxSetzgeschw zu interpretieren";
CM_ SG_ 679 ACC_minRegelgeschw "Signal dient zur Anzeige von Regelabweichungen.
Subtrahiert von der Regelgeschwindigkeit ergibt sich eine Toleranzgeschwindigkeit.";
CM_ SG_ 679 ACC_maxRegelgeschw "Signal dient zur Anzeige von Regelabweichungen.
Addiert zu der Regelgeschwindigkeit ergibt sich eine Toleranzgeschwindigkeit.";
CM_ SG_ 679 ACC_Tempolimitassistent_02 "Ansteuerng einer Anzeige zur Funktion Tempolimitassistent";
CM_ SG_ 679 ACC_Tempolimit_Einheit "Einheit des Verkehrszeichen in ACC_Tempolimit";
CM_ SG_ 679 ACC_Kurvenassistent "Ansteuerung einer Anzeige zur Funktion Kurvenassistent";
CM_ SG_ 679 ACC_Typ_Tachokranz "Abhängig von der ACC-Codierung 'Land' ist der Bereich der einstellbaren Wunschgeschwindigkeit und damit die Länge des schwach beleuchteten Tachokranzes begrenzt. Das Bit steuert im Kombi die Ausleuchtung des Tachokranzes an.
Der auszuleuchtende Bereich i";
CM_ SG_ 679 ACC_RUV "Anzeige für Rechtsunterholverhinderung in Abhängigkeit Rechts- / Linksverkehr";
CM_ SG_ 679 ACC_Tachokranz "Für zusätzliche Status- und Einstellbereichsanzeige im Tacho. (z.B. Tachokranz)
";
CM_ SG_ 679 ACC_Typ_Tachokranz_unten "Mit diesem Bit wird die LED unterhalb der minimalen Setzgeschwindigkeit an/ausgeschaltet.
";
CM_ SG_ 679 ACC_ENG_Texte "Signal zur Ansteuerung von Fahrerhinweisen der Energo-Funktioin im Mitteldisplay ";
CM_ SG_ 679 ACC_Status_GRA_Modus "Statusinformation zur GRA in Verbindung mit ACC";
CM_ SG_ 680 ACA_Querfuehrung_Texte "Signal zur Ansteuerung von Fahrerhinweisen der Querführung in ACA im Mitteldisplay";
CM_ SG_ 680 ACA_Hinweistexte "Anzeigesignal für Hinweise zur Fahrerbedienenhandlung";
CM_ SG_ 680 ACC_FoD_Status "Informiert den TSK und Kombi, ob die ACC-Funktion freigeschaltet ist oder nicht.";
CM_ SG_ 680 ACC_Texte_Abstandswarner "Signal zur Ansteuerung von Fahrer- und Warnhinweisen des Abstandswarners im Mitteldisplay";
CM_ SG_ 680 ACC_Vorz_Abstandswarner "Vorzeichen der Abstandsanzeige und -warnung";
CM_ SG_ 680 ACC_Texte_Sekundaeranz "Textdefinitionen für Anzeige ACC, Tempolimitassistent und Kurvenassistent";
CM_ SG_ 680 ACC_Status_Anzeige "Status nur zur Defintion von Anzeige im Kombi. Hinweis: Wird für die spez. VW-Anzeige (überlappende Anzeigebereiche) verwendet. Vom AUDI-ACC im Rahmen der Modulstrategie zu bedienen.";
CM_ SG_ 680 ACC_Akustik_03 "Ansteuerung der zugehörigen Akustik im Kombiinstrument, solange die entsprechende Bitkombination gesetzt ist.";
CM_ SG_ 680 ACC_Geschw_Zielfahrzeug "Nur Porsche E2 und Bentley BY636: Zur grafischen Darstellung der Geschwindigkeit eines im ACC Regelbetrieb erkannten Zielobjektes bzw, vorausfahrenden Objektes. ACC ermittelt nach der Vorschrift: Vom Kombi eingelesene 'angezeigte Geschwindigkeit' plus TO_";
CM_ SG_ 680 ACC_Texte_02 "Zusätzliches Signal zu 'ACC_Texte_Primaeranz', welches Warnungen und Fahrerhinweise bzgl. ACC im Mitteldisplay des Kombis anzeigt.";
CM_ SG_ 680 ACC_STA_Text "ACC_STA_Text wird gesendet wenn aktiv regelt.";
CM_ SG_ 680 ACC_Status_Stauende "Information, ob ACC auf ein Stauende auf Basis von Car2X reagiert.";
CM_ SG_ 680 STA_Texte "Signal, welches Warnungen und Fahrerhinweise bzgl. der Funktion STA im Kombi anzeigt";
CM_ SG_ 680 AbstWarn_LRR_FAS_Fkt_Status "Rückmeldung des Funktionsstatus an FAS ProfileMaster";
CM_ SG_ 680 STA_Zusatzanz "Für Anzeigen der STA-Funktion im Mitteldisplay";
CM_ SG_ 680 FAS_Licht_Anf "Anforderung zum Einschalten des Assistenzfahrlicht";
CM_ SG_ 680 ACC_Zeitluecke_Abstandswarner "Anzeige der aktuellen Zeitluecke zum vorausfahrenden Fahrzeug";
CM_ SG_ 680 ACC_Abstand_Abstandswarner "Signal dient zur Anzeige des Abstands im Kombi
Hinweis: das Signal ist mit dem Signal ACC_Einheit_Abstandswarner zu interpretieren";
CM_ SG_ 680 ACC_Einheit_Abstandswarner "Einheit zu Signal ACC_Abstand_Abstandswarner";
CM_ SG_ 2549880369 DIA_MFL_Req_Data "DK2F Flash Diagnosezugriff";
CM_ SG_ 2550011441 DIA_MFL_Resp_Data "DK2F Diagnose Flashen";
CM_ SG_ 2549876273 Diag_MFL_Req_Data "UDS-Diagnose
ISO-TP Datenkanal - FID2NA
Request Funktion 0x06 Diagnosezugriff vom DK4-Master auf DK1/2-Knoten 0x631";
CM_ SG_ 2550007345 Diag_MFL_Resp_Data "UDS-Diganose
ISO-TP Datenkanal - FID2NA
Response DK1/2-Knoten 0x631 an Funktion 0x06 Diagnosezugriff vom DK4-Master";
CM_ SG_ 1714 DGN_Verlernzaehler "wrap around 254 --> 0";
CM_ SG_ 1714 KBI_Kilometerstand "Fehler wird ausgegeben, falls Kilometerstand nicht restaurierbar
";
CM_ SG_ 1714 UH_Monat "0x0D, 0xF =  Werte ungültig
0x0E = Relatives Datum (nur VW)";
CM_ SG_ 1714 UH_Tag "0x0: reserviert bei VW";
CM_ SG_ 1714 UH_Stunde "0x18 - 0x1F = Werte ungültig";
CM_ SG_ 1714 UH_Minute "0x3C- 0x3f = Werte ungültig";
CM_ SG_ 1714 UH_Sekunde "0x3C- 0x3f = Werte ungültig";
CM_ SG_ 1714 Vehicle_Driving_Cycle "Optimierung der Inbetriebnahme von Steuergeräten in einem Teilverbau in der Produktion.
Siehe VW80114. Signal bildet (durch eine Gateway-Funktion) den Inhalt des Signals OBD_Driving_Cycle ab.";
CM_ SG_ 1714 Uhrzeit_01_alt "
";
CM_ BO_ 1520 "ab MQB nach abgestimmten FLH Dimmung";
CM_ SG_ 1520 DI_KL_58xd "Klemme 58xd Display- und Funktionsbeleuchtung
Mit der Klemme 58xd wird die Helligkeit der Display- und der Funktionsbeleuchtungen der Schalter gesteuert.
Im Detail beschrieben im 'Funktionslastenheft Dimmung MQB'.";
CM_ SG_ 1520 DI_KL_58xs "Suchbeleuchtung Schalter
EIN-AUS-Schaltalgorithmus der allgemeinen Schaltersuchbeleuchtung. 
Im Detail beschrieben im 'Funktionslastenheft Dimmung MQB'.
";
CM_ SG_ 1520 DI_Display_Nachtdesign "Für Displays sind oft  automatische Umschaltungen von Tag-/Nachtdesign vorgesehen.
Es gibt jedoch Zustände, an denen auch tagsüber das Abblendlicht eingeschaltet ist.
z.B. Dauerfahrlicht, Geschwindigkeitsabhängiges 'Licht-An-Bei-Autobahn', 'Regenlicht',";
CM_ SG_ 1520 DI_KL_58xt "Timergesteuerte Suchbeleuchtung
Der EIN-AUS-Schaltalgorithmus für die vor- und nachlaufende Schaltersuchbeleuchtungen beim Ein- & Aussteigen; z.B.: Start/Stop-Taster.
Im Detail beschrieben im 'Funktionslastenheft Dimmung MQB'.";
CM_ SG_ 1520 DI_Fotosensor "Helligkeitswert Fotosensor
Für die Dimmung relevanter Wert zur Sensierung der Umgebungshelligkeit
Im Detail beschrieben im 'Funktionslastenheft Dimmung MQB'.";
CM_ SG_ 1520 BCM1_Stellgroesse_Kl_58s "Rohwert Dimmpoti";
CM_ BO_ 988 "Antrieb, Fahrwerk -> Extended, Infotainment, Komfort";
CM_ SG_ 988 TSK_06_alt "Veraltet-Bit für die BotschaftTSK_06_alt";
CM_ SG_ 988 MO_QBit_Drehzahl_01 "AUDI D4: Zykluszeit: 10ms (siehe Zykluszeit schnell/Cycletime Fast)

Achtung:
Reduktion der Zykluszeit Motor_03 auf 10ms geplant.
Projektabhängig soll künftig mit 10ms gesendet werden.
Empfänger die in weiteren Konzern-Projekten eingesetzt werden müs";
CM_ SG_ 988 MKE_Texte "Systemhinweis und Sicherheitshinweis für Anzeige im Kombi";
CM_ SG_ 988 MKE_Stufe "Das Signal bildet die Müdigkeitsstufe im Kombi ab:
0 - deaktiviert
1 - nicht_verfügbar
2 - Stufe_1
3 - Stufe_2
4 - Stufe_3
5 - Stufe_4
6 - reserviert
7 - reserviert";
CM_ SG_ 988 TSK_Hauptschalter_GRA_ACC "Stellung des GRA/ACC Hauptschalters. Das Signal wird auch bei Fehlerabschaltungen von GRA/ACC weiterhin bedient und ermöglicht für ACC die Steuerung der ACC-Anzeige auch in Fehlerfällen.";
CM_ SG_ 988 MO_Drehzahl_01 "Im Fehlerfall wird die Motordrehzahl über die Nockenwellendrehzahl als Ersatzgrösse ausgegeben

Bei Parallelhybrid: Getriebeeingangsdrehzahl (=E-Maschinen Drehzahl)

Hinweis: 
Ehemaliger Fehlerwert 0xFFFF wird senderseitig nicht unterstützt. 
Diesen";
CM_ SG_ 988 GE_Fahrstufe "Fahrprogramm des Getriebes

Hinweis: Zwischenstellung '0x0' darf nur für Zustandswechsel P/R, R/N, N/D ausgegeben werden, nicht für D/S oder D/Tippgasse wegen Abschaltkriterium GRA/ACC";
CM_ SG_ 988 GE_Ursache_Fahrstufe_N "Zeigt an, warum Fahrstufe N angenommen wurde. So kann z.B. die Rollsicherung im Verlassenskonzept aktiv bleiben, wenn das Schalten nach N ohne Fahrerwunsch erfolgte (z.B. Fehlerreaktion).

ACHTUNG: Das Signal darf nur ausgewertet werden, wenn GE_Fahrstu";
CM_ SG_ 988 GE_Notlauf "AL/DL: Signalisiert wenn sich das Getriebe (bei DL ein Teilgetriebe) im Notlauf befindet.
VL: Wird gesetzt wenn kein Kraftschluss möglich ist.";
CM_ SG_ 988 ESP_Rollenmodus_Deaktivieren "Zwang zum Abbruch des Rollenmodus mit anschließender ESP-Vollfunktion.
MQB: Zwang zum Abbruch des Rollenmodus in allen Funktionsteilnehmern (Empfänger) mit anschließender ESP-Vollfunktion (Sender).
Signal wird vom ESP dauerhaft mit gültigen Werten bedat";
CM_ SG_ 988 GE_Freilauf_Status "Freilauf-Status-Signal vom Frailauf-Master an aktive Freilauf-Teilnehmer. In diesem Signal zeigt der Freilauf-Master an, welchen aktuellen Status die Freilauf-Betriebsstrategie hat.";
CM_ SG_ 988 GE_Sperr_Info_WFS "WFS-Sperrinformation";
CM_ SG_ 988 TSK_Limiter_ausgewaehlt "ACC/GRA-Betrieb nur bei nicht ausgewähltem Limiter möglich";
CM_ SG_ 988 EPB_Status_02 "Erweiterung der Zustände um ein genaueres Bild des aktuellen Zustandes zu erhalten für weitergehende Funktionen ( Stillstandsmanager)
";
CM_ SG_ 988 ACC_Status_ACC "'ACC OFF' bedeutet ACC-Hauptschalter ist 'Gerastet Aus

'ACC Reversibler Fehler' bedeutet, daß das ACC aktuell einen 
reversiblen Fehler im ACC-SG selbst oder in einem zum 
ACC-System gehörenden SG erkennt.

'ACC irreversibler Fehler' bedeutet, daß ";
CM_ SG_ 988 ESP_Status_Bremsentemp_02 "Bremsscheibentemperaturmodell. Rückmeldung für Sender einer Verzögerungsanforderung";
CM_ SG_ 299 GRA_ACC_01_CRC "Für MLB:
'Berechnung siehe Lastenheft 'Kommunikationsabsicherung für FlexRay und CAN''

Ab MQB und MLBevo:
'Berechnung siehe Lastenheft 'End-to-End Kommunikationsabsicherung''

Endwerte siehe Begleitdokument 'S-PDU Kennungsfolgen'";
CM_ SG_ 299 GRA_ACC_01_BZ "4bit Botschaftszaehler, wird mit jeder Sendebotschaft inkrementiert";
CM_ SG_ 299 GRA_Hauptschalter "Stellung des GRA/ACC-Hauptschalters: 
Bei gerastetem Hauptschalter:
0: Hauptschalter aus
1: Hauptschalter ein
Bei getastetem Hauptschalter:
0: Taster nicht betätigt
1: Taster betätigt";
CM_ SG_ 299 GRA_Abbrechen "GRA : aus mit speichern
ACC : Soft aus";
CM_ SG_ 299 GRA_Typ_Hauptschalter "Variante des GRA/ACC-Hauptschalters:
0: gerasteter Hauptschalter (bzw. Taster mit Speicherung des Status im SMLS (PAG))
1: getasteter Hauptschalter, keine Speicherung des Status im SMLS";
CM_ SG_ 299 GRA_Limiter "Stellung des Limiter-Tasters";
CM_ SG_ 299 GRA_Tip_Setzen "Tippschalter Set";
CM_ SG_ 299 GRA_Tip_Hoch "Tippschalter Tip Up / Geschwindigkeit erhöhen";
CM_ SG_ 299 GRA_Tip_Runter "Tippschalter Tip Down / Geschwindigkeit reduzieren";
CM_ SG_ 299 GRA_Tip_Wiederaufnahme "Tippschalter Wiederaufnahme";
CM_ SG_ 299 GRA_Verstellung_Zeitluecke "Verstellung der Zeitlücke für ACC

DIST -1 = Zeitluecke um 1 Stufe kleiner
DIST +1 = Zeitluecke um 1 Stufe groeßer
DIST Toggle = Zeitlücke um 1 Stufe kleiner, von kleinster Stufe auf größte Stufe";
CM_ SG_ 299 GRA_Codierung "Das Signal zeigt an, ob das Sende-SG (SMLS/MFL) auf GRA- oder ACC-Bedienteil codiert ist:
0: kein GRA- oder ACC Bedienteil
1: GRA-Bedienteil
2: ACC-Bedienteil
3: Limiter_Only-Bedienteil";
CM_ SG_ 299 GRA_Fehler "Das Signal zeigt an, dass das Sende-SG (SMLS/MFG) einen Defekt des GRA-Bedienteils erkannt hat und hierzu ein FSPE abgelegt wurde.";
CM_ SG_ 299 GRA_LIM_Taste_verfuegbar "Das Signal zeigt an, ob eine Limiter-Umschalttaste am jeweiligen GRA/ACC-Bedienelement vorhanden ist.";
CM_ SG_ 299 GRA_Tip_Stufe_2 "Signal zeigt an, dass der zweistufige GRA/ACC-Hebel (8_Positions_Bedienteil) in der 2. Tip-Stufe betätigt wird. Das Signal wird nur gleichzeitig mit dem Signal GRA_Tip_Hoch oder GRA_Tip_Runter gesetzt, wobei die Bits GRA_Tip_Hoch bzw. GRA_Tip_Runter die R";
CM_ SG_ 299 GRA_Typ_Bedienteil "Das Signal kennzeichnet die Variante des GRA/ACC-Bedienteils:
0: Init
1: 4-Positionen-Bedienteil (z.B. GRA im Blinkerhebel)
2: 6-Positionen-Bedienteil (GRA/ACC-Bedienteil mit separaten Stellungen für Set/Resume/TipUp/TipDown) 
3: 8-Positionen-Bediente";
CM_ SG_ 299 GRA_TravelAssist "Taste für TravelAssist";
CM_ SG_ 299 GRA_reserveByte4 "Zweck: Befüllen der reservierten Bitpositionen mit 0 (wg. LIN-Teilnehmer MFL)";
CM_ SG_ 299 GRA_reserveByte5 "Zweck: Befüllen der reservierten Bitpositionen mit 0 (wg. LIN-Teilnehmer MFL)";
CM_ SG_ 299 GRA_reserveByte6 "Zweck: Befüllen der reservierten Bitpositionen mit 0 (wg. LIN-Teilnehmer MFL)";
CM_ SG_ 299 GRA_reserveByte7 "Zweck: Befüllen der reservierten Bitpositionen mit 0 (wg. LIN-Teilnehmer MFL)";
CM_ SG_ 299 GRA_reserveByte8 "Zweck: Befüllen der reservierten Bitpositionen mit 0 (wg. LIN-Teilnehmer MFL)";
CM_ BO_ 960 "MQB";
CM_ SG_ 960 Klemmen_Status_01_CRC "Für MLB:
'Berechnung siehe Lastenheft 'Kommunikationsabsicherung für FlexRay und CAN''

Ab MQB und MLBevo:
'Berechnung siehe Lastenheft 'End-to-End Kommunikationsabsicherung''

Endwerte siehe Begleitdokument 'S-PDU Kennungsfolgen'";
CM_ SG_ 960 Klemmen_Status_01_BZ "4bit Botschaftszaehler; wird in jeder Sendebotschaft inkrementiert";
CM_ SG_ 960 RSt_Fahrerhinweise "Über das Signal fordert das BCM Fahrerhinweise im Kombi für die Funktion RemoteStart an.";
CM_ SG_ 960 ZAS_Kl_S "Klemme S: S-Kontakt (Schluessel steckt)
";
CM_ SG_ 960 ZAS_Kl_15 "Klemme 15: Zuendung (SW-Kl.15)
";
CM_ SG_ 960 ZAS_Kl_X "Klemme 75
";
CM_ SG_ 960 ZAS_Kl_50_Startanforderung "Klemme 50: Startwunsch Fahrer
";
CM_ SG_ 960 BCM_Remotestart_Betrieb "Zeigt den Status des RemoteStarts an, d.h. KL15_RSt ist aktiviert und der Motorlauf ist im RSt-Betrieb aktiv.";
CM_ SG_ 960 ZAS_Kl_Infotainment "Separate Klemmeninformation für das Infotainment. Signal entspricht im wesentlichen einer Klemme S Information, kann aber über einen Vor - bzw. Nachlauf zu Klemme S verfügen. 
Ein konkreter Anwendungsfall für einen Nachlauf ist die Abschaltung der Klemme";
CM_ SG_ 960 BCM_Remotestart_KL15_Anf "Zeigt den Status der Aktivierung der KL15_RST durch das BCM an.";
CM_ SG_ 960 BCM_Remotestart_MO_Start "Nachdem das BCM die Remotestart MSG Freigabe sicher erkannt hat, fordert das BCM wiederum über dieses Signal vom MSG einen Motorstart durchzuführen.";
CM_ SG_ 960 KST_Warn_P1_ZST_def "Kombi Prio Warnung Klemmensteuerung 
Zündschloß defekt, Service aufsuchen!";
CM_ SG_ 960 KST_Warn_P2_ZST_def "Kombi Prio Warnung Klemmensteuerung
Zündschloß defekt!
";
CM_ SG_ 960 KST_Fahrerhinweis_1 "Signalisierung Fahrerhinweis 1 der Klemmensteuerung an das Kombi";
CM_ SG_ 960 KST_Fahrerhinweis_2 "Signalisierung Fahrerhinweis 2 der Klemmensteuerung an das Kombi";
CM_ SG_ 960 BCM_Ausparken_Betrieb "Anforderung zur erneuten Lampenaufprüfung und Anzeige von Warnhinweisen nach einem pilotierten Ausparkvorgang (Trigger: fallende Flanke)";
CM_ SG_ 960 KST_Fahrerhinweis_4 "Signalisierung Fahrerhinweis 4 der Klemmensteuerung an das Kombi";
CM_ SG_ 960 KST_Fahrerhinweis_5 "Anzeigesignal für RemoteStart";
CM_ SG_ 960 KST_Fahrerhinweis_6 "Signal aktiviert die Kombi-Anzeigeinstrumente (Drehzahl, Tankinhalt, Kühlmitteltemperatur) während aktiviertem RemoteStart-Betrieb";
CM_ SG_ 822 LR_HZG_Temp_Sensor "Temperaturwert Lenkradheizung";
CM_ SG_ 822 LR_HZG_Taster_on_off "Anforderung des Schalters am MFL: Lenkradheizung aus/ein
(Regelung der LR_HZG ist im SMLS)";
CM_ SG_ 822 LR_HZG_Konfiguration "Konfiguration der Heizmatte der Lenkradheizung";
CM_ SG_ 817 MFL_Toggle "Watchdog Toggle-Bit";
CM_ SG_ 817 MFL_Lokalaktiv "Zeigt an ob das SG nach Klemme15 AUS und nach entsprechender MAX Aktivzeit noch aktiv war";
CM_ SG_ 817 MFL_M_Taste "Taster für Umschaltung Automatik/manuelles Schalten (Tiptronic)";
CM_ SG_ 817 MFL_Paddle_Verbau "Signalisiert den Zustand des Tipp-Paddle-Verbaus";
CM_ SG_ 817 MFL_Tastencode_1 "Beschreibt die Funktion einer fest zugeordneten Taste/Walze auf dem MFL. Bei Betätigung ändert sich der Wert von 0x0 auf den jeweiligen Tastencode.";
CM_ SG_ 817 MFL_Tastencode_2 "Beschreibt die Funktion einer fest zugeordneten Taste/Walze auf dem MFL. Ist MFL_Tastencode_1 wegen Betätigung einer Taste/Walze bereits mit einem Wert ungleich 0x0 belegt, so ändert sich bei Betätigung einer weiteren Taste/Walze der Wert dieses Signals v";
CM_ SG_ 817 MFL_Eventcode_1 "Siehe Q-LAH MFL-Protokoll";
CM_ SG_ 817 MFL_Eventcode_2 "Siehe Q-LAH MFL-Protokoll";
CM_ SG_ 817 MFL_Variante "Markenspezifische Variantennummer des MFL";
CM_ SG_ 817 MFL_Tip_Down "MFL-Tiptronic Tasten vom MFL für Getriebe
    0x0 = kein Tip_Down
    0x1 = Tip_Down";
CM_ SG_ 817 MFL_Tip_Up "MFL-Tiptronic Tasten vom MFL für Getriebe
    0x0 = kein Tip_Up
    0x1 = Tip_Up";
CM_ SG_ 817 MFL_SatModul_links_Err "Schalter Tastermodul links Fehler";
CM_ SG_ 817 MFL_SatModul_rechts_Err "Schalter Tastermodul rechts Fehler";
CM_ SG_ 817 MFL_LR_HZG_Status "Status Lenkradheizung";
CM_ SG_ 817 MFL_LR_HZG_Err "Lenkradheizung Fehler";
CM_ SG_ 817 MFL_Signalhorn "Signalhorn nicht betaetigt/betaetigt";
CM_ SG_ 817 MFL_Signalhorn_Err "Signalhorn Fehler";
CM_ SG_ 817 MFL_Tip_links_Err "Tiptronic links Fehler";
CM_ SG_ 817 MFL_Tip_rechts_Err "Tiptronic rechts Fehler";
CM_ SG_ 817 MFL_Taste_links_Err "MFL_Tastenblock links Fehler";
CM_ SG_ 817 MFL_Taste_rechts_Err "MFL_Tastenblock rechts Fehler";
CM_ SG_ 817 MFL_ECU_Err "MFL-µC Fehler";
CM_ SG_ 817 MFL_Response_Err "siehe LIN2.0-Specification
(Darf nicht über ein Fehlergueltigkeitsbit abgesichtert werden!)";
CM_ SG_ 560 MFL_Beruehrungserkennung "Das Signal beschreibt die Berührung der Bedieninseln des Touch-MFL (nicht berührt = Init, links, rechts oder beidseitig).";
CM_ SG_ 2463978751 MFL_Vibrationsimpuls_rechts "Als haptisches Feedback zur Bedienung der MFL-Tasteninsel.
Wird zyklisch abgespielt, solange Signal anliegt. Die Zeit bis zu den nächsten vollen 100ms ist im MFL mit Pause gespeichert. Ist die Impulsanforderung kürzer als die Länge des Impulses, wird der";
CM_ SG_ 2463978751 MFL_Vibrationsimpuls_links "Für haptisches Feedback zur Bedienung der MFL-Tasteninsel.
Wird zyklisch abgespielt, solange Signal anliegt. Die Zeit bis zu den nächsten vollen 100ms ist im MFL mit Pause gespeichert. Ist die Impulsanforderung kürzer als die Länge des Impulses, wird der";
CM_ SG_ 2463978751 MFL_Tasten_Volume_benoetigt "Taste beleuchtet, Tastencodes werden gesendet";
CM_ SG_ 2463978751 MFL_Tasten_UpDownOK_benoetigt "Taste beleuchtet, Tastencodes werden gesendet";
CM_ SG_ 2463978751 MFL_Taste_SDS_benoetigt "Taste beleuchtet, Tastencode wird gesendet";
CM_ SG_ 1471 MFL_Tastencode_1 "Beschreibt die Funktion einer fest zugeordneten Taste/Walze auf dem MFL. Bei Betätigung ändert sich der Wert von 0x0 auf den jeweiligen Tastencode.";
CM_ SG_ 1471 MFL_Tastencode_2 "Beschreibt die Funktion einer fest zugeordneten Taste/Walze auf dem MFL. Ist MFL_Tastencode_1 wegen Betätigung einer Taste/Walze bereits mit einem Wert ungleich 0x0 belegt, so ändert sich bei Betätigung einer weiteren Taste/Walze der Wert dieses Signals v";
CM_ SG_ 1471 MFL_Eventcode_1 "Siehe Q-LAH MFL-Protokoll";
CM_ SG_ 1471 MFL_Eventcode_2 "Siehe Q-LAH MFL-Protokoll";
CM_ SG_ 1471 MFL_Variante "Markenspezifische Variantennummer des MFL";
CM_ BO_ 1601 "ab MQB mit CRC-8";
CM_ SG_ 1601 Motor_Code_01_CRC "Für MLB:
'Berechnung siehe Lastenheft 'Kommunikationsabsicherung für FlexRay und CAN''

Ab MQB und MLBevo:
'Berechnung siehe Lastenheft 'End-to-End Kommunikationsabsicherung''

Endwerte siehe Begleitdokument 'S-PDU Kennungsfolgen'";
CM_ SG_ 1601 MO_Faktor_Momente_02 "Dieses Signal schaltet den Wertebereich aller Momente vom Motor, Getriebe, TSK, Bremse ... um! Die Momente besitzen somit einen variablen Wertebereich, weil sich durch den Faktor die Momente sowohl in Auflösung als auch Maximalwerten ändert.

0x0 nicht ";
CM_ SG_ 1601 MO_Hybridfahrzeug "Anhand dieses Signals plausibilisiert die Lenkhilfe das Bit Fahrbereitschaft.

Im Projekt Cayenne PHEV (und ggf. auch VW526 PHEV) ist aus Gründen der Abwärtskompatibilität der Wert '2' zu senden.";
CM_ SG_ 1601 MO_Code "Motorcodierinformation Version 13 (Details siehe Anhang)";
CM_ SG_ 1601 MO_Getriebe_Code "Getriebecodierung des Motors";
CM_ SG_ 1601 MO_StartStopp_Codiert "Funktion StartStopp im aktuellen Klemmenzyklus verbaut";
CM_ SG_ 1601 MO_Anzeige_StSt_gueltig "Zeigt die Gültigkeit der neuen StSt-Anzeigesignale an, MO_Anzeige_StSt_Text und  MO_Anzeige_Symbol. Mo_Text_Motorstart 1..5 sind zu ignorieren.";
CM_ SG_ 1601 MO_Anzahl_Zyl "Zylinderzahl des Verbrennungsmotors";
CM_ SG_ 1601 MO_Kraftstoffart "Primärkraftstoff zum Antrieb des Fahrzeugs";
CM_ SG_ 1601 MO_Hubraum "Hubraum des Verbrennungsmotors";
CM_ SG_ 1601 MO_Ansaugsystem "Art des Ansaugsystems des Verbrennungsmotors";
CM_ SG_ 1601 MO_Leistung "Nennleistung des Verbrennungsmotors";
CM_ SG_ 1601 MO_OBD_Typ "Abgastyp OBD";
CM_ SG_ 1601 MO_DPF_verbaut "Verbauinformation Diesel-Partikel-Filter
";
CM_ SG_ 1601 TSK_Codierung "Information über den plausibilisierten Codierungszustand des Triebstrangskoordinators auf ACC oder GRA.";
CM_ SG_ 2600468496 NM_Gateway_CBV_AWB "Das Signal ist zu setzen, wenn das SG aktiv den Bus geweckt hat";
CM_ SG_ 2600468496 NM_Gateway_CBV_CRI "Das Signal ist dauerhaft gesetzt, wenn das NM-Layout dem neuen NM-Layout für Teilnetzbetrieb entspricht";
CM_ SG_ 2600468496 NM_Gateway_NM_State "1 = Zustand Repeat Message (<-- Bus-Sleep Mode)
2 = Zustand Repeat Message (<-- Prepare Bus-Sleep Mode)
4 = Zustand Normal Operation (<-- Repeat Message)
8 = Zustand Normal Operation (<-- Ready Sleep)
16 = Zustand Repeat Message (<-- Ready Sleep)
32 ";
CM_ SG_ 2600468496 NM_Gateway_Car_Wakeup "Car Wakeup (Subbusmaster wertet aus)

MQB: 
-Diagnose- oder Komponentenschutzmaster-Funktion weckt den schlafenden Subbus (z.B. MOST)

MEB:
- Diagnose aktiv -aktive Diagnosekommunikation am OBD-Stecker";
CM_ SG_ 2600468496 NM_Gateway_UDS_CC "Funktionseinschränkung aufgrund aktivem UDS-Communication Control; siehe VW80124";
CM_ SG_ 2600468496 NM_Gateway_NM_aktiv_KL15 "Steuergerät hat KL15-EIN erkannt";
CM_ SG_ 2600468496 NM_Gateway_NM_aktiv_Diagnose "Diagnose befindet sich nach VW80124 in einer NonDefaultDiagnostic-Session, z.B. ExtendedDiagnostic-Session";
CM_ SG_ 2600468496 NM_Gateway_NM_aktiv_Tmin "Mindestaktivzeit ist noch nicht abgelaufen (bei jedem Weckereignis wird die Mindestaktivzeit neu gestartet)";
CM_ SG_ 2600468496 NM_Gateway_CAB_V10 "CAB = Clusteraktivbits (V10)";
CM_ SG_ 2600469457 NM_MFL_CBV_AWB "Das Signal ist zu setzen, wenn das SG aktiv den Bus geweckt hat";
CM_ SG_ 2600469457 NM_MFL_CBV_CRI "Das Signal ist dauerhaft gesetzt, wenn das NM-Layout dem neuen NM-Layout für Teilnetzbetrieb entspricht";
CM_ SG_ 2600469457 NM_MFL_NM_State "1 = Zustand Repeat Message (<-- Bus-Sleep Mode)
2 = Zustand Repeat Message (<-- Prepare Bus-Sleep Mode)
4 = Zustand Normal Operation (<-- Repeat Message)
8 = Zustand Normal Operation (<-- Ready Sleep)
16 = Zustand Repeat Message (<-- Normal Operation)";
CM_ SG_ 2600469457 NM_MFL_Car_Wakeup "Car Wakeup (Busmaster wertet aus)";
CM_ SG_ 2600469457 NM_MFL_UDS_CC "Funktionseinschränkung aufgrund aktivem UDS-Communication Control; siehe VW80124";
CM_ SG_ 2600469457 NM_MFL_NM_aktiv_KL15 "Steuergerät hat KL15-EIN erkannt";
CM_ SG_ 2600469457 NM_MFL_NM_aktiv_Diagnose "Diagnose befindet sich nach VW80124 in einer NonDefaultDiagnostic-Session, z.B. ExtendedDiagnostic-Session";
CM_ SG_ 2600469457 NM_MFL_NM_aktiv_Tmin "Mindestaktivzeit ist noch nicht abgelaufen (bei jedem Weckereignis wird die Mindestaktivzeit neu gestartet)";
CM_ SG_ 2600469457 NM_MFL_CAB_V10 "CAB = Clusteraktivbits (V10)";
CM_ SG_ 2549903409 OBDC_SSN_MFL_Req_Data "Request FID- zu NA- Kommunikation zw. OnboardDiagnoseClient und DK2F Sub-System-Knoten CMC_01 ... 16";
CM_ SG_ 2550034481 OBDC_SSN_MFL_Resp_Data "Response FID- zu NA- Kommunikation zw. OnboardDiagnoseClient und DK2F Sub-System-Knoten CMC_01 ... 16";
CM_ SG_ 2564502513 OBDx_allOBD_Req_Data "29bit OBD";
CM_ SG_ 2589283656 ORU_EM_Anfrage_freigegebeneNetze "Meldung der während eines konkreten Online Remote Updates freigegebenen Netze (12V, 48V, HV)";
CM_ SG_ 2589283656 ORU_EM_Anfrage_Stromaufnahme "Meldung der voraussichtlichen durchschnittlichen Stromaufnahme eines konkreten Online Remote Updates an das NVEM";
CM_ SG_ 2589283656 ORU_EM_Anfrage_Flashdauer "Anfrage an das Energiemanagement, ob ein konkretes Online Remote Update durchgeführt werden kann - Flashdauer in 10s.";
CM_ SG_ 2589283656 ORU_Warnung "Wenn durch Störungen der Funktion Online Remote Update nicht sichergestellt ist, dass vor Kunde keine Funktionseinschränkungen auftreten, muss der Benutzer des Fahrzeugs entsprechend gewarnt werden.";
CM_ SG_ 2589283656 ORU_Status "Broadcast des Status der Konzernfunktion Online Remote Update";
CM_ BO_ 1413 "MQB, MLBevo";
CM_ SG_ 1413 SI_Sammel_SG_Fehler "Anzahl der gesetzten KD-Fehler direkt angeschlossener Steuergeräte der DK3 und DK4 gemäß 80127.
Hinweis: Ein Subbusmaster stellt nur die gesammelte Information der an ihn angeschlossenen Steuergeräte der DK3 und DK4 zur Verfügung.

Für ServiceKey Auswe";
CM_ SG_ 1413 SI_P_Mode_gueltig "zeigt an, ob es sich um ein Fahrzeug mit zentraler oder dezentraler Steu-erung des Produktionsmodes handelt
Siehe Q-LAH Produktionsmode (LAH.DUM.907.AS)";
CM_ SG_ 1413 SI_Diagnose_Aktiv "Gibt an ob Diagnose-Botschaften empfangen werden und somit eine Diagnose aktiv ist.
MQB: Gibt an ob Diagnose-Bus Botschaften empfangen werden und somit eine Diagnose aktiv ist.";
CM_ SG_ 1413 SI_T_Mode "0x0: Transportmodus nicht aktiv
0x1: Transportmodus aktiv";
CM_ SG_ 1413 SI_NWDF "Netzwerk-Diagnose Freigebe zur zentralen Aktivierung der Netzwerkdiagnose";
CM_ SG_ 1413 SI_NWDF_gueltig "Gültigkeitsbit zu SI_NWDF gemäß Lastenheft: Zentrale Aktivierung Netzwerkdiagnose";
CM_ SG_ 1413 SI_Sammelfehler "Sammelfehlermeldung zur Anzeige im Kombi - siehe Spez. Sammelfehlermeldung
Hinweis: Einzelne Steuergeräte können zur Anpassung an den Produktionsprozess im Gateway auskodiert werden!";
CM_ SG_ 1413 GW_KD_Fehler "Kundendienstfehlerbit Gateway zur Anzeige eines im Gateway abgelegten Fehlerspeichereintrages.";
CM_ SG_ 1413 SI_T_Schutz "Transportschutz-Signal, das bei Transportmodus und Motorlauf aktiv bleibt
0x0: Transportschutz nicht aktiv
0x1: Transportschutz aktiv";
CM_ SG_ 1413 SI_P_Mode "Zentrale Steuerung des Produktionsmodes gemäß Q-LAH-Produktionsmode (LAH.DUM.907.AS)";
CM_ SG_ 1413 SI_BUS_01 "MQB/MQB_A0/PQ26: ACAN
MQB2020: ACAN(FD)
MLBevo: HCAN
MEB: ACAN(FD)";
CM_ SG_ 1413 SI_BUS_02 "MQB/MQB A0 Standard+, High: FCAN
MQB2020: FCAN(FD)
MLBevo: Frei
MEB: FCAN(FD)";
CM_ SG_ 1413 SI_BUS_03 "MQB/MQB A0/PQ26: KCAN
MQB2020: KCAN
MLBevo: KCAN
MEB: KCAN";
CM_ SG_ 1413 SI_BUS_04 "MQB/MQB A0 Standard+, High: ICAN
MQB2020: ICAN
MLBevo: ICAN
MEB: ABCAN(FD)";
CM_ SG_ 1413 SI_BUS_05 "MQB/MQB A0/PQ26: DiagCAN
MQB2020: DiagCAN(FD)
MLBevo: DiagCAN
MEB: DiagCAN(FD)";
CM_ SG_ 1413 SI_BUS_06 "MQB/MQB A0/PQ26: ECAN
MQB2020: FASCAN(FD)
MLBevo: ECAN
MEB: FASCAN(FD)";
CM_ SG_ 1413 SI_BUS_07 "MQB: LIN1 (Energie)
MQB2020: LIN1 (Energie)
MLBevo: LIN1 (Energie)";
CM_ SG_ 1413 SI_BUS_08 "MQB: LIN2 (MFL)
MQB2020: LIN2 (MFL)
MLBevo: LIN2 (MFL)";
CM_ SG_ 1413 SI_BUS_09 "MQB: LIN3 (unbelegt)
MQB2020: LIN3 (Uhr/FES)
MLBevo: LIN3 (Energie2)";
CM_ SG_ 1413 SI_BUS_10 "MLBevo: Flexray

MQB2020: MCAN";
CM_ SG_ 1413 SI_BUS_11 "MLBevo: Ethernet";
CM_ SG_ 1413 SI_BUS_12 "MQB: unbelegt
MLBevo: K2CAN";
CM_ SG_ 1413 SI_BUS_13 "MQB: unbelegt
MLBevo: DCAN
MEB: CCAN";
CM_ SG_ 1413 SI_BUS_14 "MQB/MQB A0: unbelegt
MQB2020: HCAN
MLBevo: CCAN
MEB: EVCAN(FD)";
CM_ SG_ 1413 SI_BUS_15 "MQB: frei
MQB2020: frei
MLBevo: frei
MEB: AFSCAN";
CM_ SG_ 1413 SI_Bus_Identifikation "Das Signal identifiziert den Bus eindeutig. Das Signal ist konstant auf jedem Bus.
Der Signalwert entspricht dem Wert 'Busnummer' aus der VW80127 Gateway_component_list_databus_identification (0x2A2D) 'Bus-Identifier'.";
CM_ SG_ 1413 SI_CAB_V10 "CAB = Clusteraktivbits (V10)";
CM_ SG_ 619 TA_ACC_Sollstatus "Status-Anforderung ACC vom TravelAssist";
CM_ SG_ 619 TA_Status "Anzeige TravelAssist-Statusleuchte im Kombi";
CM_ SG_ 619 TA_Spurwechsel "Anzeige für die Durchführung eines Spurwechsels im Kombi";
CM_ SG_ 619 TA_Texte "Anzeige TravelAssist-Texte im Kombi";
CM_ SG_ 619 TA_FoD_Status "TAwird durch FoD geschützt sein und so reicht die PR/Zieldatencontainer basierte Codierung nicht mehr aus.

Aus diesem Grund brauch wir ein separates Signal, dass uns den Freischaltezustand mitteilt.";
CM_ SG_ 619 TA_Spurwechsel_Ready "Angabe der assistierten Spurwechselmöglichkeiten durch die Funktion 'Travel Assist'";
CM_ SG_ 2463978710 OPS_ComfortReadyStatus "Das Signal wird durch den Basisdienst User State Server (Technikvariante: OccupantPresenceService) erzeugt und bildet einen neuen Zustand, bestehend aus einer Verknüpfung der Fahreranwesenheit (Fahrer abwesend / Fahrer anwesend) und der Klemmensteuerung (";
CM_ SG_ 2463978710 OPS_OccupantPresenceStatus "Das Signal wird durch den Basisdienst User State Server (Service: OccupantPresenceService) erzeugt und bildet die Anwesenheit und Abwesenheit aller Insassen im Fahrzeug ab.";
CM_ SG_ 2463978710 OPS_DriverPresenceStatus "Das Signal wird durch den Basisdienst User State Server (Service: OccupantPresenceService) erzeugt und bildet die Fahrerzustände im Fahrzeug ab.";
CM_ SG_ 2463978710 OPS_QBit_DriverPresence "Das Signal wird durch den Basisdienst User State Server (Service: OccupantPresenceService) erzeugt und signalisiert die Qualität der Fahrerzustände.";
BA_DEF_  "DBName" STRING ;
BA_DEF_  "GenNWMApBusSleep" STRING ;
BA_DEF_  "GenNWMApCanNormal" STRING ;
BA_DEF_  "GenNWMApCanOff" STRING ;
BA_DEF_  "GenNWMApCanOn" STRING ;
BA_DEF_  "GenNWMApCanSleep" STRING ;
BA_DEF_  "GenNWMApCanWakeUp" STRING ;
BA_DEF_  "GenNWMGotoMode_Awake" STRING ;
BA_DEF_  "GenNWMGotoMode_BusSleep" STRING ;
BA_DEF_  "GenNWMSleepTime" INT 0 1000000;
BA_DEF_  "GenNWMTalkNM" STRING ;
BA_DEF_  "Manufacturer" STRING ;
BA_DEF_  "NmhBaseAddress" HEX 0 536870911;
BA_DEF_  "NmhMessageCount" INT 0 1024;
BA_DEF_  "NmType" STRING ;
BA_DEF_  "VAGTP20_SetupMessageCount" INT 0 255;
BA_DEF_  "VAGTP20_SetupStartAddress" HEX 0 2047;
BA_DEF_  "VersionDay" INT 1 31;
BA_DEF_  "VersionMonth" INT 1 12;
BA_DEF_  "VersionWeek" INT 1 52;
BA_DEF_  "VersionYear" INT 0 99;
BA_DEF_  "VersionNumber" INT 0 65535;
BA_DEF_  "BusType" STRING ;
BA_DEF_  "Baudrate" INT 1 1000000;
BA_DEF_  "SamplePointMin" INT 1 100;
BA_DEF_  "SamplePointMax" INT 1 100;
BA_DEF_  "SyncJumpWidthMin" INT 1 4;
BA_DEF_  "SyncJumpWidthMax" INT 1 4;
BA_DEF_  "NBTMin" INT 1 30;
BA_DEF_  "NBTMax" INT 1 30;
BA_DEF_  "NmhTimeoutTimer" INT 0 65535;
BA_DEF_  "NmhWaitBusSleepTimer" INT 0 65535;
BA_DEF_  "NmhPrepareBusSleepTimer" INT 0 65535;
BA_DEF_  "NmhLongTimer" INT 0 65535;
BA_DEF_  "NmhNStart" INT 0 255;
BA_DEF_ BU_  "GenNodAutoGenDsp" ENUM  "No","Yes";
BA_DEF_ BU_  "GenNodAutoGenSnd" ENUM  "No","Yes";
BA_DEF_ BU_  "GenNodSleepTime" INT 0 1000000;
BA_DEF_ BU_  "ILUsed" ENUM  "No","Yes";
BA_DEF_ BU_  "ECUVariantDefault" ENUM  "No","Yes";
BA_DEF_ BU_  "ECUVariantGroup" STRING ;
BA_DEF_ BU_  "NodeLayerModules" STRING ;
BA_DEF_ BU_  "NmhNode" ENUM  "No","Yes";
BA_DEF_ BU_  "NmNode" ENUM  "No","Yes";
BA_DEF_ BO_  "DiagRequest" ENUM  "No","Yes";
BA_DEF_ BO_  "DiagResponse" ENUM  "No","Yes";
BA_DEF_ BO_  "DiagState" ENUM  "No","Yes";
BA_DEF_ BO_  "GenMsgChkConstant" HEX 0 4095;
BA_DEF_ BO_  "GenMsgCycleTime" INT 0 65535;
BA_DEF_ BO_  "GenMsgCycleTimeFast" INT 0 65535;
BA_DEF_ BO_  "GenMsgDelayTime" INT 0 100000;
BA_DEF_ BO_  "GenMsgILSupport" ENUM  "No","Yes";
BA_DEF_ BO_  "GenMsgNrOfRepetition" INT 0 100;
BA_DEF_ BO_  "GenMsgPDUConstants" STRING ;
BA_DEF_ BO_  "GenMsgSendType" ENUM  "Cyclic","not_used","not_used","not_used","not_used","not_used","not_used","IfActive","NoMsgSendType";
BA_DEF_ BO_  "GenMsgStartDelayTime" INT 0 100000;
BA_DEF_ BO_  "NmMessage" ENUM  "No","Yes";
BA_DEF_ BO_  "NmhMessage" ENUM  "No","Yes";
BA_DEF_ BO_  "MsgType" ENUM  "Application","NM ","NMH","TP2.0","ISO-TP ","BAP","EID","KS";
BA_DEF_ BO_  "VAGTP20_API" HEX 0 255;
BA_DEF_ BO_  "VAGTP20_DynConnection" ENUM  "No","Yes";
BA_DEF_ BO_  "VAGTP20_DynSetup" ENUM  "No","Yes";
BA_DEF_ BO_  "VAGTP20_StatConnection" ENUM  "No","Yes";
BA_DEF_ SG_  "GenSigActiveRepetitions" INT -2147483648 2147483647;
BA_DEF_ SG_  "GenSigInactiveValue" INT -2147483648 2147483647;
BA_DEF_ SG_  "GenSigSendType" ENUM  "Cyclic","OnWrite","OnWriteWithRepetition","OnChange","OnChangeWithRepetition","IfActive","IfActiveWithRepetition","NoSigSendType","OnChangeAndIfActive","OnChangeAndIfActiveWithRepetition";
BA_DEF_ SG_  "GenSigStartValue" INT -2147483648 2147483647;
BA_DEF_ SG_  "NWM-WakeupAllowed" ENUM  "No","Yes";
BA_DEF_ SG_  "GenSigFuncType" ENUM  "NoFunction","MsgCounter","CRC-8","XOR","XOR-2","DatedBit","SW-Kl15","CHK","Constant","Protocol","CRC-8-SAE_J1850","CRC-32","DataLength","DataID","MsgCounter16","SOK-Signatur";
BA_DEF_ SG_  "GenSigSwitchedByIgnition" ENUM  "No","Yes";
BA_DEF_ SG_  "Fehlerwert" HEX 0 2147483647;
BA_DEF_ SG_  "GenSigMissingSourceValue" HEX 0 2147483647;
BA_DEF_REL_ BU_SG_REL_  "GenSigTimeoutTime" INT 0 65535;
BA_DEF_DEF_  "DBName" "";
BA_DEF_DEF_  "GenNWMApBusSleep" "";
BA_DEF_DEF_  "GenNWMApCanNormal" "";
BA_DEF_DEF_  "GenNWMApCanOff" "";
BA_DEF_DEF_  "GenNWMApCanOn" "";
BA_DEF_DEF_  "GenNWMApCanSleep" "";
BA_DEF_DEF_  "GenNWMApCanWakeUp" "";
BA_DEF_DEF_  "GenNWMGotoMode_Awake" "";
BA_DEF_DEF_  "GenNWMGotoMode_BusSleep" "";
BA_DEF_DEF_  "GenNWMSleepTime" 0;
BA_DEF_DEF_  "GenNWMTalkNM" "";
BA_DEF_DEF_  "Manufacturer" "";
BA_DEF_DEF_  "NmhBaseAddress" 0;
BA_DEF_DEF_  "NmhMessageCount" 1;
BA_DEF_DEF_  "NmType" "None";
BA_DEF_DEF_  "VAGTP20_SetupMessageCount" 0;
BA_DEF_DEF_  "VAGTP20_SetupStartAddress" 0;
BA_DEF_DEF_  "VersionDay" 27;
BA_DEF_DEF_  "VersionMonth" 4;
BA_DEF_DEF_  "VersionWeek" 17;
BA_DEF_DEF_  "VersionYear" 18;
BA_DEF_DEF_  "VersionNumber" 0;
BA_DEF_DEF_  "BusType" "";
BA_DEF_DEF_  "Baudrate" 1;
BA_DEF_DEF_  "SamplePointMin" 1;
BA_DEF_DEF_  "SamplePointMax" 1;
BA_DEF_DEF_  "SyncJumpWidthMin" 1;
BA_DEF_DEF_  "SyncJumpWidthMax" 1;
BA_DEF_DEF_  "NBTMin" 10;
BA_DEF_DEF_  "NBTMax" 20;
BA_DEF_DEF_  "NmhTimeoutTimer" 0;
BA_DEF_DEF_  "NmhWaitBusSleepTimer" 0;
BA_DEF_DEF_  "NmhPrepareBusSleepTimer" 0;
BA_DEF_DEF_  "NmhLongTimer" 0;
BA_DEF_DEF_  "NmhNStart" 0;
BA_DEF_DEF_  "GenNodAutoGenDsp" "Yes";
BA_DEF_DEF_  "GenNodAutoGenSnd" "Yes";
BA_DEF_DEF_  "GenNodSleepTime" 0;
BA_DEF_DEF_  "ILUsed" "Yes";
BA_DEF_DEF_  "ECUVariantDefault" "Yes";
BA_DEF_DEF_  "ECUVariantGroup" "";
BA_DEF_DEF_  "NodeLayerModules" "";
BA_DEF_DEF_  "NmhNode" "Yes";
BA_DEF_DEF_  "NmNode" "No";
BA_DEF_DEF_  "DiagRequest" "No";
BA_DEF_DEF_  "DiagResponse" "No";
BA_DEF_DEF_  "DiagState" "No";
BA_DEF_DEF_  "GenMsgChkConstant" 0;
BA_DEF_DEF_  "GenMsgCycleTime" 0;
BA_DEF_DEF_  "GenMsgCycleTimeFast" 0;
BA_DEF_DEF_  "GenMsgDelayTime" 0;
BA_DEF_DEF_  "GenMsgILSupport" "No";
BA_DEF_DEF_  "GenMsgNrOfRepetition" 0;
BA_DEF_DEF_  "GenMsgPDUConstants" "";
BA_DEF_DEF_  "GenMsgSendType" "NoMsgSendType";
BA_DEF_DEF_  "GenMsgStartDelayTime" 0;
BA_DEF_DEF_  "NmMessage" "No";
BA_DEF_DEF_  "NmhMessage" "No";
BA_DEF_DEF_  "MsgType" "Application";
BA_DEF_DEF_  "VAGTP20_API" 0;
BA_DEF_DEF_  "VAGTP20_DynConnection" "No";
BA_DEF_DEF_  "VAGTP20_DynSetup" "No";
BA_DEF_DEF_  "VAGTP20_StatConnection" "No";
BA_DEF_DEF_  "GenSigActiveRepetitions" 0;
BA_DEF_DEF_  "GenSigInactiveValue" 0;
BA_DEF_DEF_  "GenSigSendType" "NoSigSendType";
BA_DEF_DEF_  "GenSigStartValue" 0;
BA_DEF_DEF_  "NWM-WakeupAllowed" "No";
BA_DEF_DEF_  "GenSigFuncType" "NoFunction";
BA_DEF_DEF_  "GenSigSwitchedByIgnition" "Yes";
BA_DEF_DEF_  "Fehlerwert" 0;
BA_DEF_DEF_  "GenSigMissingSourceValue" 0;
BA_DEF_DEF_REL_ "GenSigTimeoutTime" 0;
BA_ "NmhNStart" 20;
BA_ "NmhLongTimer" 200;
BA_ "NmhPrepareBusSleepTimer" 500;
BA_ "NmhWaitBusSleepTimer" 750;
BA_ "NmhTimeoutTimer" 1000;
BA_ "SyncJumpWidthMax" 4;
BA_ "SyncJumpWidthMin" 2;
BA_ "SamplePointMax" 84;
BA_ "SamplePointMin" 80;
BA_ "Baudrate" 500000;
BA_ "BusType" "CAN";
BA_ "VersionNumber" 5;
BA_ "VAGTP20_SetupStartAddress" 512;
BA_ "VAGTP20_SetupMessageCount" 128;
BA_ "NmType" "NM-High";
BA_ "NmhMessageCount" 1024;
BA_ "NmhBaseAddress" 452984832;
BA_ "Manufacturer" "VAG";
BA_ "GenNWMTalkNM" "Nmh_ReqNetOn()";
BA_ "GenNWMSleepTime" 4000;
BA_ "GenNWMGotoMode_BusSleep" "Nmh_ReqNetOff()";
BA_ "GenNWMGotoMode_Awake" "Nmh_ReqNetOn()";
BA_ "GenNWMApCanWakeUp" "apCanWakeUp()";
BA_ "GenNWMApCanSleep" "apCanSleep()";
BA_ "GenNWMApCanOn" "NMIndnetOn()";
BA_ "GenNWMApCanOff" "NMIndnetOff()";
BA_ "GenNWMApCanNormal" "apCanNormal()";
BA_ "GenNWMApBusSleep" "NMIndNetSDN()";
BA_ "DBName" "MEB_MFLCAN";
BA_ "NodeLayerModules" BU_ ICAS1_Gateway "NMHigh.DLL";
BA_ "ECUVariantGroup" BU_ ICAS1_Gateway "Gateway";
BA_ "GenNodSleepTime" BU_ ICAS1_Gateway 4000;
BA_ "NmhNode" BU_ ICAS1_KommunikationsServer 0;
BA_ "GenNodSleepTime" BU_ ICAS1_KommunikationsServer 4000;
BA_ "NodeLayerModules" BU_ MFL_CAN "NMHigh.DLL";
BA_ "ECUVariantGroup" BU_ MFL_CAN "MFL";
BA_ "GenNodSleepTime" BU_ MFL_CAN 4000;
BA_ "GenMsgILSupport" BO_ 2684350465 1;
BA_ "GenMsgSendType" BO_ 2684350465 0;
BA_ "GenMsgCycleTime" BO_ 2684350465 1000;
BA_ "GenMsgCycleTime" BO_ 2684350485 10;
BA_ "GenMsgILSupport" BO_ 2684350485 1;
BA_ "GenMsgSendType" BO_ 2684350485 0;
BA_ "GenMsgCycleTime" BO_ 2684350484 10;
BA_ "GenMsgILSupport" BO_ 2684350484 1;
BA_ "GenMsgSendType" BO_ 2684350484 0;
BA_ "GenMsgCycleTime" BO_ 2684350483 10;
BA_ "GenMsgILSupport" BO_ 2684350483 1;
BA_ "GenMsgSendType" BO_ 2684350483 0;
BA_ "GenMsgCycleTime" BO_ 2684350482 10;
BA_ "GenMsgILSupport" BO_ 2684350482 1;
BA_ "GenMsgSendType" BO_ 2684350482 0;
BA_ "GenMsgSendType" BO_ 2684350501 0;
BA_ "GenMsgILSupport" BO_ 2684350501 1;
BA_ "GenMsgCycleTime" BO_ 2684350501 10;
BA_ "GenMsgSendType" BO_ 2684350500 0;
BA_ "GenMsgILSupport" BO_ 2684350500 1;
BA_ "GenMsgCycleTime" BO_ 2684350500 10;
BA_ "GenMsgSendType" BO_ 2684350499 0;
BA_ "GenMsgILSupport" BO_ 2684350499 1;
BA_ "GenMsgCycleTime" BO_ 2684350499 10;
BA_ "GenMsgSendType" BO_ 2684350498 0;
BA_ "GenMsgILSupport" BO_ 2684350498 1;
BA_ "GenMsgCycleTime" BO_ 2684350498 10;
BA_ "GenMsgILSupport" BO_ 2684350496 1;
BA_ "GenMsgCycleTime" BO_ 2684350496 1000;
BA_ "MsgType" BO_ 2566664449 6;
BA_ "MsgType" BO_ 2566664448 6;
BA_ "GenMsgILSupport" BO_ 2684350464 1;
BA_ "GenMsgSendType" BO_ 2684350464 0;
BA_ "GenMsgCycleTime" BO_ 2684350464 1000;
BA_ "GenMsgSendType" BO_ 679 0;
BA_ "GenMsgILSupport" BO_ 679 1;
BA_ "GenMsgCycleTime" BO_ 679 60;
BA_ "GenMsgSendType" BO_ 680 0;
BA_ "GenMsgILSupport" BO_ 680 1;
BA_ "GenMsgCycleTime" BO_ 680 60;
BA_ "MsgType" BO_ 2549880369 4;
BA_ "DiagRequest" BO_ 2549880369 1;
BA_ "MsgType" BO_ 2550011441 4;
BA_ "DiagResponse" BO_ 2550011441 1;
BA_ "MsgType" BO_ 2549876273 4;
BA_ "DiagRequest" BO_ 2549876273 1;
BA_ "MsgType" BO_ 2550007345 4;
BA_ "DiagResponse" BO_ 2550007345 1;
BA_ "GenMsgSendType" BO_ 1714 0;
BA_ "GenMsgILSupport" BO_ 1714 1;
BA_ "GenMsgCycleTime" BO_ 1714 1000;
BA_ "GenMsgSendType" BO_ 1520 0;
BA_ "GenMsgILSupport" BO_ 1520 1;
BA_ "GenMsgDelayTime" BO_ 1520 50;
BA_ "GenMsgCycleTime" BO_ 1520 200;
BA_ "GenMsgSendType" BO_ 988 0;
BA_ "GenMsgILSupport" BO_ 988 1;
BA_ "GenMsgDelayTime" BO_ 988 10;
BA_ "GenMsgCycleTime" BO_ 988 50;
BA_ "GenMsgSendType" BO_ 299 0;
BA_ "GenMsgPDUConstants" BO_ 299 "0x6a,0x38,0xb4,0x27,0x22,0xef,0xe1,0xbb,0xf8,0x80,0x84,0x49,0xc7,0x9e,0x1e,0x2b";
BA_ "GenMsgILSupport" BO_ 299 1;
BA_ "GenMsgCycleTime" BO_ 299 30;
BA_ "GenMsgSendType" BO_ 960 0;
BA_ "GenMsgPDUConstants" BO_ 960 "0xc3,0xc3,0xc3,0xc3,0xc3,0xc3,0xc3,0xc3,0xc3,0xc3,0xc3,0xc3,0xc3,0xc3,0xc3,0xc3";
BA_ "GenMsgILSupport" BO_ 960 1;
BA_ "GenMsgDelayTime" BO_ 960 10;
BA_ "GenMsgCycleTime" BO_ 960 100;
BA_ "GenMsgChkConstant" BO_ 960 195;
BA_ "GenMsgSendType" BO_ 822 0;
BA_ "GenMsgILSupport" BO_ 822 1;
BA_ "GenMsgCycleTime" BO_ 822 120;
BA_ "GenMsgSendType" BO_ 817 0;
BA_ "GenMsgILSupport" BO_ 817 1;
BA_ "GenMsgCycleTimeFast" BO_ 817 30;
BA_ "GenMsgCycleTime" BO_ 817 500;
BA_ "GenMsgSendType" BO_ 560 0;
BA_ "GenMsgILSupport" BO_ 560 1;
BA_ "GenMsgCycleTimeFast" BO_ 560 10;
BA_ "GenMsgCycleTime" BO_ 560 100;
BA_ "GenMsgSendType" BO_ 2463978751 0;
BA_ "GenMsgNrOfRepetition" BO_ 2463978751 5;
BA_ "GenMsgILSupport" BO_ 2463978751 1;
BA_ "GenMsgDelayTime" BO_ 2463978751 50;
BA_ "GenMsgCycleTimeFast" BO_ 2463978751 100;
BA_ "GenMsgCycleTime" BO_ 2463978751 1000;
BA_ "GenMsgILSupport" BO_ 1471 1;
BA_ "GenMsgDelayTime" BO_ 1471 10;
BA_ "GenMsgSendType" BO_ 1601 0;
BA_ "GenMsgPDUConstants" BO_ 1601 "0x47,0x47,0x47,0x47,0x47,0x47,0x47,0x47,0x47,0x47,0x47,0x47,0x47,0x47,0x47,0x47";
BA_ "GenMsgILSupport" BO_ 1601 1;
BA_ "GenMsgCycleTime" BO_ 1601 1000;
BA_ "GenMsgChkConstant" BO_ 1601 71;
BA_ "MsgType" BO_ 2600468496 2;
BA_ "NmhMessage" BO_ 2600468496 1;
BA_ "GenMsgCycleTimeFast" BO_ 2600468496 10;
BA_ "GenMsgCycleTime" BO_ 2600468496 200;
BA_ "MsgType" BO_ 2600469457 2;
BA_ "NmhMessage" BO_ 2600469457 1;
BA_ "GenMsgCycleTimeFast" BO_ 2600469457 10;
BA_ "GenMsgCycleTime" BO_ 2600469457 200;
BA_ "MsgType" BO_ 2549903409 4;
BA_ "DiagRequest" BO_ 2549903409 1;
BA_ "MsgType" BO_ 2550034481 4;
BA_ "DiagResponse" BO_ 2550034481 1;
BA_ "MsgType" BO_ 2564502513 4;
BA_ "DiagState" BO_ 2564502513 1;
BA_ "GenMsgSendType" BO_ 2589283656 0;
BA_ "GenMsgILSupport" BO_ 2589283656 1;
BA_ "GenMsgDelayTime" BO_ 2589283656 100;
BA_ "GenMsgCycleTime" BO_ 2589283656 500;
BA_ "GenMsgSendType" BO_ 1413 0;
BA_ "GenMsgILSupport" BO_ 1413 1;
BA_ "GenMsgDelayTime" BO_ 1413 10;
BA_ "GenMsgCycleTime" BO_ 1413 1000;
BA_ "GenMsgSendType" BO_ 619 0;
BA_ "GenMsgILSupport" BO_ 619 1;
BA_ "GenMsgDelayTime" BO_ 619 20;
BA_ "GenMsgCycleTime" BO_ 619 100;
BA_ "GenMsgSendType" BO_ 2463978710 0;
BA_ "GenMsgNrOfRepetition" BO_ 2463978710 5;
BA_ "GenMsgILSupport" BO_ 2463978710 1;
BA_ "GenMsgDelayTime" BO_ 2463978710 10;
BA_ "GenMsgCycleTimeFast" BO_ 2463978710 10;
BA_ "GenMsgCycleTime" BO_ 2463978710 100;
BA_ "GenSigSendType" SG_ 3221225472 MFL_Develop_Variant 0;
BA_ "GenSigSendType" SG_ 2684350465 MFL_Develop_Byte0 0;
BA_ "GenSigSendType" SG_ 2684350465 MFL_Develop_Byte2 0;
BA_ "GenSigSendType" SG_ 2684350465 MFL_Develop_Byte3 0;
BA_ "GenSigSendType" SG_ 2684350465 MFL_Develop_Byte4 0;
BA_ "GenSigSendType" SG_ 2684350465 MFL_Develop_Byte5 0;
BA_ "GenSigSendType" SG_ 2684350465 MFL_Develop_Byte6 0;
BA_ "GenSigSendType" SG_ 2684350465 MFL_Develop_Byte7 0;
BA_ "GenSigSendType" SG_ 2684350465 MFL_Develop_Byte1 0;
BA_ "GenSigSendType" SG_ 2684350496 MFL_Develop1_Left_PicState 1;
BA_ "GenSigSendType" SG_ 2684350496 MFL_Develop1_Right_PicState 1;
BA_ "GenSigStartValue" SG_ 2684350464 MFL_Develop_HWC_Version 24;
BA_ "GenSigSendType" SG_ 2684350464 MFL_Develop_HWC_Version 0;
BA_ "GenSigStartValue" SG_ 2684350464 MFL_Develop_BSW_Version 24;
BA_ "GenSigSendType" SG_ 2684350464 MFL_Develop_BSW_Version 0;
BA_ "GenSigStartValue" SG_ 2684350464 MFL_Develop_MAA_Version 24;
BA_ "GenSigSendType" SG_ 2684350464 MFL_Develop_MAA_Version 0;
BA_ "GenSigSendType" SG_ 2684350464 MFL_Develop_Day 0;
BA_ "GenSigSendType" SG_ 2684350464 MFL_Develop_Minute 0;
BA_ "GenSigStartValue" SG_ 2684350464 MFL_Develop_Minute 61;
BA_ "GenSigSendType" SG_ 2684350464 MFL_Develop_Hour 0;
BA_ "GenSigStartValue" SG_ 2684350464 MFL_Develop_Hour 24;
BA_ "GenSigSendType" SG_ 2684350464 MFL_Develop_Month 0;
BA_ "GenSigSendType" SG_ 2684350464 MFL_Develop_Year 0;
BA_ "GenSigSendType" SG_ 2684350464 MFL_Develop_ProjectName 0;
BA_ "GenSigStartValue" SG_ 679 ACC_Regelgeschw 1023;
BA_ "GenSigSendType" SG_ 679 ACC_Regelgeschw 0;
BA_ "GenSigSendType" SG_ 679 ACC_Einheit_maxSetzgeschw 0;
BA_ "GenSigStartValue" SG_ 679 ACC_maxSetzgeschw 511;
BA_ "GenSigSendType" SG_ 679 ACC_maxSetzgeschw 0;
BA_ "GenSigStartValue" SG_ 679 ACC_minRegelgeschw 255;
BA_ "GenSigSendType" SG_ 679 ACC_minRegelgeschw 0;
BA_ "GenSigStartValue" SG_ 679 ACC_maxRegelgeschw 255;
BA_ "GenSigSendType" SG_ 679 ACC_maxRegelgeschw 0;
BA_ "GenSigSendType" SG_ 679 ACC_Tempolimitassistent_02 0;
BA_ "GenSigSendType" SG_ 679 ACC_Tempolimit_Einheit 0;
BA_ "GenSigSendType" SG_ 679 ACC_Kurvenassistent 0;
BA_ "GenSigSendType" SG_ 679 ACC_Typ_Tachokranz 0;
BA_ "GenSigSendType" SG_ 679 ACC_RUV 0;
BA_ "GenSigSendType" SG_ 679 ACC_Tachokranz 0;
BA_ "GenSigSendType" SG_ 679 ACC_Typ_Tachokranz_unten 0;
BA_ "GenSigSendType" SG_ 679 ACC_ENG_Texte 0;
BA_ "GenSigSendType" SG_ 679 ACC_Status_GRA_Modus 0;
BA_ "GenSigSendType" SG_ 680 ACA_Querfuehrung_Texte 0;
BA_ "GenSigSendType" SG_ 680 ACA_Hinweistexte 0;
BA_ "GenSigSendType" SG_ 680 ACC_FoD_Status 0;
BA_ "GenSigSendType" SG_ 680 ACC_Texte_Abstandswarner 0;
BA_ "GenSigSendType" SG_ 680 ACC_Vorz_Abstandswarner 0;
BA_ "GenSigSendType" SG_ 680 ACC_Texte_Sekundaeranz 0;
BA_ "GenSigSendType" SG_ 680 ACC_Status_Anzeige 0;
BA_ "GenSigSendType" SG_ 680 ACC_Akustik_03 0;
BA_ "NWM-WakeupAllowed" SG_ 680 ACC_Geschw_Zielfahrzeug 1;
BA_ "GenSigSendType" SG_ 680 ACC_Geschw_Zielfahrzeug 0;
BA_ "GenSigSendType" SG_ 680 ACC_Texte_02 0;
BA_ "GenSigSendType" SG_ 680 ACC_STA_Text 0;
BA_ "GenSigSwitchedByIgnition" SG_ 680 ACC_Status_Stauende 0;
BA_ "GenSigSendType" SG_ 680 ACC_Status_Stauende 0;
BA_ "GenSigSendType" SG_ 680 STA_Texte 0;
BA_ "Fehlerwert" SG_ 680 AbstWarn_LRR_FAS_Fkt_Status 3;
BA_ "GenSigSendType" SG_ 680 AbstWarn_LRR_FAS_Fkt_Status 0;
BA_ "GenSigSendType" SG_ 680 STA_Zusatzanz 0;
BA_ "GenSigSendType" SG_ 680 FAS_Licht_Anf 0;
BA_ "GenSigStartValue" SG_ 680 ACC_Zeitluecke_Abstandswarner 63;
BA_ "GenSigSendType" SG_ 680 ACC_Zeitluecke_Abstandswarner 0;
BA_ "GenSigStartValue" SG_ 680 ACC_Abstand_Abstandswarner 511;
BA_ "GenSigSendType" SG_ 680 ACC_Abstand_Abstandswarner 0;
BA_ "GenSigSendType" SG_ 680 ACC_Einheit_Abstandswarner 0;
BA_ "GenSigSwitchedByIgnition" SG_ 2549880369 DIA_MFL_Req_Data 0;
BA_ "GenSigFuncType" SG_ 2549880369 DIA_MFL_Req_Data 9;
BA_ "GenSigSendType" SG_ 2549880369 DIA_MFL_Req_Data 3;
BA_ "GenSigSwitchedByIgnition" SG_ 2550011441 DIA_MFL_Resp_Data 0;
BA_ "GenSigFuncType" SG_ 2550011441 DIA_MFL_Resp_Data 9;
BA_ "GenSigSendType" SG_ 2550011441 DIA_MFL_Resp_Data 3;
BA_ "GenSigSwitchedByIgnition" SG_ 2549876273 Diag_MFL_Req_Data 0;
BA_ "GenSigSendType" SG_ 2549876273 Diag_MFL_Req_Data 3;
BA_ "GenSigSwitchedByIgnition" SG_ 2550007345 Diag_MFL_Resp_Data 0;
BA_ "GenSigSendType" SG_ 2550007345 Diag_MFL_Resp_Data 3;
BA_ "GenSigSwitchedByIgnition" SG_ 1714 DGN_Verlernzaehler 0;
BA_ "GenSigSendType" SG_ 1714 DGN_Verlernzaehler 0;
BA_ "Fehlerwert" SG_ 1714 KBI_Kilometerstand 1048575;
BA_ "GenSigSwitchedByIgnition" SG_ 1714 KBI_Kilometerstand 0;
BA_ "GenSigStartValue" SG_ 1714 KBI_Kilometerstand 1048574;
BA_ "GenSigSendType" SG_ 1714 KBI_Kilometerstand 0;
BA_ "GenSigSwitchedByIgnition" SG_ 1714 UH_Jahr 0;
BA_ "GenSigSendType" SG_ 1714 UH_Jahr 0;
BA_ "Fehlerwert" SG_ 1714 UH_Monat 15;
BA_ "GenSigSwitchedByIgnition" SG_ 1714 UH_Monat 0;
BA_ "GenSigSendType" SG_ 1714 UH_Monat 0;
BA_ "GenSigSwitchedByIgnition" SG_ 1714 UH_Tag 0;
BA_ "GenSigSendType" SG_ 1714 UH_Tag 0;
BA_ "GenSigSwitchedByIgnition" SG_ 1714 UH_Stunde 0;
BA_ "GenSigSendType" SG_ 1714 UH_Stunde 0;
BA_ "GenSigSwitchedByIgnition" SG_ 1714 UH_Minute 0;
BA_ "GenSigSendType" SG_ 1714 UH_Minute 0;
BA_ "GenSigSwitchedByIgnition" SG_ 1714 UH_Sekunde 0;
BA_ "GenSigSendType" SG_ 1714 UH_Sekunde 0;
BA_ "GenSigSwitchedByIgnition" SG_ 1714 Vehicle_Driving_Cycle 0;
BA_ "GenSigSendType" SG_ 1714 Vehicle_Driving_Cycle 0;
BA_ "GenSigSwitchedByIgnition" SG_ 1714 Kombi_02_alt 0;
BA_ "GenSigFuncType" SG_ 1714 Kombi_02_alt 5;
BA_ "GenSigStartValue" SG_ 1714 Kombi_02_alt 1;
BA_ "GenSigSendType" SG_ 1714 Kombi_02_alt 0;
BA_ "GenSigSwitchedByIgnition" SG_ 1714 Uhrzeit_01_alt 0;
BA_ "GenSigFuncType" SG_ 1714 Uhrzeit_01_alt 5;
BA_ "GenSigStartValue" SG_ 1714 Uhrzeit_01_alt 1;
BA_ "GenSigSendType" SG_ 1714 Uhrzeit_01_alt 0;
BA_ "Fehlerwert" SG_ 1520 DI_KL_58xd 255;
BA_ "GenSigSwitchedByIgnition" SG_ 1520 DI_KL_58xd 0;
BA_ "GenSigStartValue" SG_ 1520 DI_KL_58xd 254;
BA_ "GenSigSendType" SG_ 1520 DI_KL_58xd 3;
BA_ "Fehlerwert" SG_ 1520 DI_KL_58xs 127;
BA_ "GenSigSwitchedByIgnition" SG_ 1520 DI_KL_58xs 0;
BA_ "GenSigStartValue" SG_ 1520 DI_KL_58xs 126;
BA_ "GenSigSendType" SG_ 1520 DI_KL_58xs 3;
BA_ "GenSigSwitchedByIgnition" SG_ 1520 DI_Display_Nachtdesign 0;
BA_ "GenSigSendType" SG_ 1520 DI_Display_Nachtdesign 3;
BA_ "Fehlerwert" SG_ 1520 DI_KL_58xt 127;
BA_ "GenSigSwitchedByIgnition" SG_ 1520 DI_KL_58xt 0;
BA_ "GenSigStartValue" SG_ 1520 DI_KL_58xt 126;
BA_ "GenSigSendType" SG_ 1520 DI_KL_58xt 3;
BA_ "GenSigSwitchedByIgnition" SG_ 1520 DI_Fotosensor 0;
BA_ "GenSigSendType" SG_ 1520 DI_Fotosensor 3;
BA_ "Fehlerwert" SG_ 1520 BCM1_Stellgroesse_Kl_58s 127;
BA_ "GenSigSwitchedByIgnition" SG_ 1520 BCM1_Stellgroesse_Kl_58s 0;
BA_ "GenSigStartValue" SG_ 1520 BCM1_Stellgroesse_Kl_58s 126;
BA_ "GenSigSendType" SG_ 1520 BCM1_Stellgroesse_Kl_58s 3;
BA_ "GenSigSwitchedByIgnition" SG_ 988 Motor_12_alt 0;
BA_ "GenSigFuncType" SG_ 988 Motor_12_alt 5;
BA_ "GenSigStartValue" SG_ 988 Motor_12_alt 1;
BA_ "GenSigSendType" SG_ 988 Motor_12_alt 0;
BA_ "GenSigSwitchedByIgnition" SG_ 988 ESP_07_alt 0;
BA_ "GenSigFuncType" SG_ 988 ESP_07_alt 5;
BA_ "GenSigStartValue" SG_ 988 ESP_07_alt 1;
BA_ "GenSigSendType" SG_ 988 ESP_07_alt 0;
BA_ "GenSigSwitchedByIgnition" SG_ 988 Getriebe_11_alt 0;
BA_ "GenSigFuncType" SG_ 988 Getriebe_11_alt 5;
BA_ "GenSigStartValue" SG_ 988 Getriebe_11_alt 1;
BA_ "GenSigSendType" SG_ 988 Getriebe_11_alt 0;
BA_ "GenSigFuncType" SG_ 988 Getriebe_13_alt 5;
BA_ "GenSigStartValue" SG_ 988 Getriebe_13_alt 1;
BA_ "GenSigSendType" SG_ 988 Getriebe_13_alt 0;
BA_ "GenSigFuncType" SG_ 988 Getriebe_17_alt 5;
BA_ "GenSigStartValue" SG_ 988 Getriebe_17_alt 1;
BA_ "GenSigSendType" SG_ 988 Getriebe_17_alt 0;
BA_ "GenSigSwitchedByIgnition" SG_ 988 TSK_06_alt 0;
BA_ "GenSigStartValue" SG_ 988 TSK_06_alt 1;
BA_ "GenSigSendType" SG_ 988 TSK_06_alt 0;
BA_ "GenSigFuncType" SG_ 988 Getriebe_14_alt 5;
BA_ "GenSigStartValue" SG_ 988 Getriebe_14_alt 1;
BA_ "GenSigSendType" SG_ 988 Getriebe_14_alt 0;
BA_ "GenSigSwitchedByIgnition" SG_ 988 ESP_50_alt 0;
BA_ "GenSigFuncType" SG_ 988 ESP_50_alt 5;
BA_ "GenSigStartValue" SG_ 988 ESP_50_alt 1;
BA_ "GenSigSendType" SG_ 988 ESP_50_alt 0;
BA_ "GenSigSwitchedByIgnition" SG_ 988 MO_QBit_Drehzahl_01 0;
BA_ "GenSigStartValue" SG_ 988 MO_QBit_Drehzahl_01 1;
BA_ "GenSigSendType" SG_ 988 MO_QBit_Drehzahl_01 0;
BA_ "GenSigSendType" SG_ 988 MKE_Texte 0;
BA_ "GenSigSendType" SG_ 988 MKE_Stufe 0;
BA_ "Fehlerwert" SG_ 988 TSK_Hauptschalter_GRA_ACC 3;
BA_ "GenSigSwitchedByIgnition" SG_ 988 TSK_Hauptschalter_GRA_ACC 0;
BA_ "GenSigSendType" SG_ 988 TSK_Hauptschalter_GRA_ACC 0;
BA_ "GenSigSwitchedByIgnition" SG_ 988 MO_Drehzahl_01 0;
BA_ "GenSigSendType" SG_ 988 MO_Drehzahl_01 0;
BA_ "Fehlerwert" SG_ 988 GE_Fahrstufe 15;
BA_ "GenSigSwitchedByIgnition" SG_ 988 GE_Fahrstufe 0;
BA_ "GenSigStartValue" SG_ 988 GE_Fahrstufe 1;
BA_ "GenSigSendType" SG_ 988 GE_Fahrstufe 3;
BA_ "GenSigSendType" SG_ 988 GE_Ursache_Fahrstufe_N 0;
BA_ "GenSigSendType" SG_ 988 GE_Notlauf 3;
BA_ "GenSigSwitchedByIgnition" SG_ 988 ESP_Rollenmodus_Deaktivieren 0;
BA_ "GenSigSendType" SG_ 988 ESP_Rollenmodus_Deaktivieren 0;
BA_ "Fehlerwert" SG_ 988 GE_Freilauf_Status 7;
BA_ "GenSigSendType" SG_ 988 GE_Freilauf_Status 0;
BA_ "GenSigSendType" SG_ 988 GE_Sperr_Info_WFS 3;
BA_ "GenSigSwitchedByIgnition" SG_ 988 TSK_Limiter_ausgewaehlt 0;
BA_ "GenSigSendType" SG_ 988 TSK_Limiter_ausgewaehlt 0;
BA_ "GenSigSwitchedByIgnition" SG_ 988 EPB_Status_02 0;
BA_ "GenSigStartValue" SG_ 988 EPB_Status_02 6;
BA_ "GenSigSendType" SG_ 988 EPB_Status_02 0;
BA_ "GenSigSendType" SG_ 988 ACC_Status_ACC 0;
BA_ "GenSigSwitchedByIgnition" SG_ 988 ACC_18_alt 0;
BA_ "GenSigFuncType" SG_ 988 ACC_18_alt 5;
BA_ "GenSigStartValue" SG_ 988 ACC_18_alt 1;
BA_ "GenSigSendType" SG_ 988 ACC_18_alt 0;
BA_ "GenSigSwitchedByIgnition" SG_ 988 ESP_Status_Bremsentemp_02 0;
BA_ "GenSigSendType" SG_ 988 ESP_Status_Bremsentemp_02 0;
BA_ "GenSigFuncType" SG_ 299 GRA_ACC_01_CRC 2;
BA_ "GenSigSendType" SG_ 299 GRA_ACC_01_CRC 0;
BA_ "GenSigFuncType" SG_ 299 GRA_ACC_01_BZ 1;
BA_ "GenSigSendType" SG_ 299 GRA_ACC_01_BZ 0;
BA_ "GenSigSendType" SG_ 299 GRA_Hauptschalter 0;
BA_ "GenSigSendType" SG_ 299 GRA_Abbrechen 0;
BA_ "GenSigSendType" SG_ 299 GRA_Typ_Hauptschalter 0;
BA_ "GenSigSendType" SG_ 299 GRA_Limiter 0;
BA_ "GenSigSendType" SG_ 299 GRA_Tip_Setzen 0;
BA_ "GenSigSendType" SG_ 299 GRA_Tip_Hoch 0;
BA_ "GenSigSendType" SG_ 299 GRA_Tip_Runter 0;
BA_ "GenSigSendType" SG_ 299 GRA_Tip_Wiederaufnahme 0;
BA_ "GenSigSendType" SG_ 299 GRA_Verstellung_Zeitluecke 0;
BA_ "GenSigSendType" SG_ 299 GRA_Codierung 0;
BA_ "Fehlerwert" SG_ 299 GRA_Fehler 1;
BA_ "GenSigSendType" SG_ 299 GRA_Fehler 0;
BA_ "GenSigFuncType" SG_ 299 GRA_LIM_Taste_verfuegbar 8;
BA_ "GenSigSendType" SG_ 299 GRA_LIM_Taste_verfuegbar 0;
BA_ "GenSigSendType" SG_ 299 GRA_Tip_Stufe_2 0;
BA_ "GenSigSendType" SG_ 299 GRA_Typ_Bedienteil 0;
BA_ "GenSigSwitchedByIgnition" SG_ 299 GRA_TravelAssist 0;
BA_ "GenSigSendType" SG_ 299 GRA_TravelAssist 0;
BA_ "GenSigSendType" SG_ 299 GRA_reserveByte4 0;
BA_ "GenSigSendType" SG_ 299 GRA_reserveByte5 0;
BA_ "GenSigSendType" SG_ 299 GRA_reserveByte6 0;
BA_ "GenSigSendType" SG_ 299 GRA_reserveByte7 0;
BA_ "GenSigSendType" SG_ 299 GRA_reserveByte8 0;
BA_ "GenSigSwitchedByIgnition" SG_ 960 Klemmen_Status_01_CRC 0;
BA_ "GenSigFuncType" SG_ 960 Klemmen_Status_01_CRC 2;
BA_ "GenSigSendType" SG_ 960 Klemmen_Status_01_CRC 0;
BA_ "GenSigSwitchedByIgnition" SG_ 960 Klemmen_Status_01_BZ 0;
BA_ "GenSigFuncType" SG_ 960 Klemmen_Status_01_BZ 1;
BA_ "GenSigSendType" SG_ 960 Klemmen_Status_01_BZ 0;
BA_ "GenSigSwitchedByIgnition" SG_ 960 RSt_Fahrerhinweise 0;
BA_ "GenSigSendType" SG_ 960 RSt_Fahrerhinweise 3;
BA_ "GenSigSwitchedByIgnition" SG_ 960 ZAS_Kl_S 0;
BA_ "GenSigSendType" SG_ 960 ZAS_Kl_S 3;
BA_ "GenSigSwitchedByIgnition" SG_ 960 ZAS_Kl_15 0;
BA_ "GenSigFuncType" SG_ 960 ZAS_Kl_15 6;
BA_ "NWM-WakeupAllowed" SG_ 960 ZAS_Kl_15 1;
BA_ "GenSigSendType" SG_ 960 ZAS_Kl_15 3;
BA_ "GenSigSwitchedByIgnition" SG_ 960 ZAS_Kl_X 0;
BA_ "GenSigSendType" SG_ 960 ZAS_Kl_X 3;
BA_ "GenSigSwitchedByIgnition" SG_ 960 ZAS_Kl_50_Startanforderung 0;
BA_ "GenSigSendType" SG_ 960 ZAS_Kl_50_Startanforderung 3;
BA_ "GenSigSwitchedByIgnition" SG_ 960 BCM_Remotestart_Betrieb 0;
BA_ "GenSigSendType" SG_ 960 BCM_Remotestart_Betrieb 3;
BA_ "GenSigSwitchedByIgnition" SG_ 960 ZAS_Kl_Infotainment 0;
BA_ "GenSigSendType" SG_ 960 ZAS_Kl_Infotainment 3;
BA_ "GenSigSwitchedByIgnition" SG_ 960 BCM_Remotestart_KL15_Anf 0;
BA_ "GenSigSendType" SG_ 960 BCM_Remotestart_KL15_Anf 3;
BA_ "GenSigSwitchedByIgnition" SG_ 960 BCM_Remotestart_MO_Start 0;
BA_ "GenSigSendType" SG_ 960 BCM_Remotestart_MO_Start 3;
BA_ "GenSigSwitchedByIgnition" SG_ 960 KST_Warn_P1_ZST_def 0;
BA_ "GenSigSendType" SG_ 960 KST_Warn_P1_ZST_def 3;
BA_ "GenSigSwitchedByIgnition" SG_ 960 KST_Warn_P2_ZST_def 0;
BA_ "GenSigSendType" SG_ 960 KST_Warn_P2_ZST_def 3;
BA_ "GenSigSwitchedByIgnition" SG_ 960 KST_Fahrerhinweis_1 0;
BA_ "GenSigSendType" SG_ 960 KST_Fahrerhinweis_1 3;
BA_ "GenSigSwitchedByIgnition" SG_ 960 KST_Fahrerhinweis_2 0;
BA_ "GenSigSendType" SG_ 960 KST_Fahrerhinweis_2 3;
BA_ "GenSigSwitchedByIgnition" SG_ 960 BCM_Ausparken_Betrieb 0;
BA_ "GenSigSendType" SG_ 960 BCM_Ausparken_Betrieb 3;
BA_ "GenSigSwitchedByIgnition" SG_ 960 KST_Fahrerhinweis_4 0;
BA_ "GenSigSendType" SG_ 960 KST_Fahrerhinweis_4 3;
BA_ "GenSigSwitchedByIgnition" SG_ 960 KST_Fahrerhinweis_5 0;
BA_ "GenSigSendType" SG_ 960 KST_Fahrerhinweis_5 3;
BA_ "GenSigSwitchedByIgnition" SG_ 960 KST_Fahrerhinweis_6 0;
BA_ "GenSigSendType" SG_ 960 KST_Fahrerhinweis_6 3;
BA_ "GenSigSwitchedByIgnition" SG_ 822 LR_HZG_Temp_Sensor 0;
BA_ "GenSigStartValue" SG_ 822 LR_HZG_Temp_Sensor 254;
BA_ "GenSigSendType" SG_ 822 LR_HZG_Temp_Sensor 0;
BA_ "GenSigSwitchedByIgnition" SG_ 822 LR_HZG_Taster_on_off 0;
BA_ "GenSigSendType" SG_ 822 LR_HZG_Taster_on_off 0;
BA_ "GenSigSwitchedByIgnition" SG_ 822 LR_HZG_Konfiguration 0;
BA_ "GenSigSendType" SG_ 822 LR_HZG_Konfiguration 0;
BA_ "GenSigSwitchedByIgnition" SG_ 817 MFL_Zaehler 0;
BA_ "GenSigSendType" SG_ 817 MFL_Zaehler 0;
BA_ "GenSigSwitchedByIgnition" SG_ 817 MFL_Toggle 0;
BA_ "GenSigSendType" SG_ 817 MFL_Toggle 0;
BA_ "GenSigSwitchedByIgnition" SG_ 817 MFL_Lokalaktiv 0;
BA_ "GenSigSendType" SG_ 817 MFL_Lokalaktiv 0;
BA_ "GenSigSendType" SG_ 817 MFL_M_Taste 0;
BA_ "GenSigSwitchedByIgnition" SG_ 817 MFL_Paddle_Verbau 0;
BA_ "GenSigSendType" SG_ 817 MFL_Paddle_Verbau 0;
BA_ "GenSigSwitchedByIgnition" SG_ 817 MFL_Tastencode_1 0;
BA_ "GenSigSendType" SG_ 817 MFL_Tastencode_1 0;
BA_ "GenSigSwitchedByIgnition" SG_ 817 MFL_Tastencode_2 0;
BA_ "GenSigSendType" SG_ 817 MFL_Tastencode_2 0;
BA_ "GenSigSwitchedByIgnition" SG_ 817 MFL_Eventcode_1 0;
BA_ "GenSigSendType" SG_ 817 MFL_Eventcode_1 0;
BA_ "GenSigSwitchedByIgnition" SG_ 817 MFL_Eventcode_2 0;
BA_ "GenSigSendType" SG_ 817 MFL_Eventcode_2 0;
BA_ "GenSigSwitchedByIgnition" SG_ 817 MFL_Marke 0;
BA_ "GenSigFuncType" SG_ 817 MFL_Marke 8;
BA_ "GenSigSendType" SG_ 817 MFL_Marke 0;
BA_ "GenSigSwitchedByIgnition" SG_ 817 MFL_Variante 0;
BA_ "GenSigFuncType" SG_ 817 MFL_Variante 8;
BA_ "GenSigSendType" SG_ 817 MFL_Variante 0;
BA_ "GenSigSwitchedByIgnition" SG_ 817 MFL_Dummy_0_Signal_1 0;
BA_ "GenSigSendType" SG_ 817 MFL_Dummy_0_Signal_1 0;
BA_ "GenSigSendType" SG_ 817 MFL_Tip_Down 5;
BA_ "GenSigSendType" SG_ 817 MFL_Tip_Up 5;
BA_ "Fehlerwert" SG_ 817 MFL_SatModul_links_Err 1;
BA_ "GenSigSwitchedByIgnition" SG_ 817 MFL_SatModul_links_Err 0;
BA_ "GenSigFuncType" SG_ 817 MFL_SatModul_links_Err 5;
BA_ "GenSigSendType" SG_ 817 MFL_SatModul_links_Err 0;
BA_ "Fehlerwert" SG_ 817 MFL_SatModul_rechts_Err 1;
BA_ "GenSigSwitchedByIgnition" SG_ 817 MFL_SatModul_rechts_Err 0;
BA_ "GenSigFuncType" SG_ 817 MFL_SatModul_rechts_Err 5;
BA_ "GenSigSendType" SG_ 817 MFL_SatModul_rechts_Err 0;
BA_ "GenSigSwitchedByIgnition" SG_ 817 MFL_Dummy_0_Signal_2 0;
BA_ "GenSigSendType" SG_ 817 MFL_Dummy_0_Signal_2 0;
BA_ "GenSigSwitchedByIgnition" SG_ 817 MFL_Dummy_0_Signal_3 0;
BA_ "GenSigSendType" SG_ 817 MFL_Dummy_0_Signal_3 0;
BA_ "GenSigSwitchedByIgnition" SG_ 817 MFL_LR_HZG_Status 0;
BA_ "GenSigSendType" SG_ 817 MFL_LR_HZG_Status 0;
BA_ "Fehlerwert" SG_ 817 MFL_LR_HZG_Err 1;
BA_ "GenSigSwitchedByIgnition" SG_ 817 MFL_LR_HZG_Err 0;
BA_ "GenSigSendType" SG_ 817 MFL_LR_HZG_Err 0;
BA_ "GenSigSwitchedByIgnition" SG_ 817 MFL_Signalhorn 0;
BA_ "GenSigSendType" SG_ 817 MFL_Signalhorn 5;
BA_ "Fehlerwert" SG_ 817 MFL_Signalhorn_Err 1;
BA_ "GenSigSwitchedByIgnition" SG_ 817 MFL_Signalhorn_Err 0;
BA_ "GenSigSendType" SG_ 817 MFL_Signalhorn_Err 0;
BA_ "Fehlerwert" SG_ 817 MFL_Tip_links_Err 1;
BA_ "GenSigSwitchedByIgnition" SG_ 817 MFL_Tip_links_Err 0;
BA_ "GenSigSendType" SG_ 817 MFL_Tip_links_Err 0;
BA_ "Fehlerwert" SG_ 817 MFL_Tip_rechts_Err 1;
BA_ "GenSigSwitchedByIgnition" SG_ 817 MFL_Tip_rechts_Err 0;
BA_ "GenSigSendType" SG_ 817 MFL_Tip_rechts_Err 0;
BA_ "Fehlerwert" SG_ 817 MFL_Taste_links_Err 1;
BA_ "GenSigSwitchedByIgnition" SG_ 817 MFL_Taste_links_Err 0;
BA_ "GenSigSendType" SG_ 817 MFL_Taste_links_Err 0;
BA_ "Fehlerwert" SG_ 817 MFL_Taste_rechts_Err 1;
BA_ "GenSigSwitchedByIgnition" SG_ 817 MFL_Taste_rechts_Err 0;
BA_ "GenSigSendType" SG_ 817 MFL_Taste_rechts_Err 0;
BA_ "Fehlerwert" SG_ 817 MFL_ECU_Err 1;
BA_ "GenSigSwitchedByIgnition" SG_ 817 MFL_ECU_Err 0;
BA_ "GenSigSendType" SG_ 817 MFL_ECU_Err 0;
BA_ "Fehlerwert" SG_ 817 MFL_Response_Err 1;
BA_ "GenSigSwitchedByIgnition" SG_ 817 MFL_Response_Err 0;
BA_ "GenSigSendType" SG_ 817 MFL_Response_Err 0;
BA_ "GenSigSwitchedByIgnition" SG_ 560 MFL_Beruehrungserkennung 0;
BA_ "GenSigSendType" SG_ 560 MFL_Beruehrungserkennung 3;
BA_ "GenSigSwitchedByIgnition" SG_ 2463978751 MFL_Vibrationsimpuls_rechts 0;
BA_ "GenSigSendType" SG_ 2463978751 MFL_Vibrationsimpuls_rechts 4;
BA_ "GenSigSwitchedByIgnition" SG_ 2463978751 MFL_Vibrationsimpuls_links 0;
BA_ "GenSigSendType" SG_ 2463978751 MFL_Vibrationsimpuls_links 4;
BA_ "GenSigSwitchedByIgnition" SG_ 2463978751 MFL_Tasten_Volume_benoetigt 0;
BA_ "GenSigSendType" SG_ 2463978751 MFL_Tasten_Volume_benoetigt 0;
BA_ "GenSigSwitchedByIgnition" SG_ 2463978751 MFL_Tasten_UpDownOK_benoetigt 0;
BA_ "GenSigSendType" SG_ 2463978751 MFL_Tasten_UpDownOK_benoetigt 0;
BA_ "GenSigSwitchedByIgnition" SG_ 2463978751 MFL_Taste_SDS_benoetigt 0;
BA_ "GenSigSendType" SG_ 2463978751 MFL_Taste_SDS_benoetigt 0;
BA_ "GenSigSwitchedByIgnition" SG_ 1471 MFL_Tastencode_1 0;
BA_ "GenSigSendType" SG_ 1471 MFL_Tastencode_1 1;
BA_ "GenSigSwitchedByIgnition" SG_ 1471 MFL_Tastencode_2 0;
BA_ "GenSigSendType" SG_ 1471 MFL_Tastencode_2 1;
BA_ "GenSigSwitchedByIgnition" SG_ 1471 MFL_Eventcode_1 0;
BA_ "GenSigSendType" SG_ 1471 MFL_Eventcode_1 1;
BA_ "GenSigSwitchedByIgnition" SG_ 1471 MFL_Eventcode_2 0;
BA_ "GenSigSendType" SG_ 1471 MFL_Eventcode_2 1;
BA_ "GenSigSwitchedByIgnition" SG_ 1471 MFL_Marke 0;
BA_ "GenSigFuncType" SG_ 1471 MFL_Marke 8;
BA_ "GenSigSendType" SG_ 1471 MFL_Marke 1;
BA_ "GenSigSwitchedByIgnition" SG_ 1471 MFL_Variante 0;
BA_ "GenSigFuncType" SG_ 1471 MFL_Variante 8;
BA_ "GenSigSendType" SG_ 1471 MFL_Variante 1;
BA_ "GenSigSwitchedByIgnition" SG_ 1601 Motor_Code_01_CRC 0;
BA_ "GenSigFuncType" SG_ 1601 Motor_Code_01_CRC 2;
BA_ "GenSigSendType" SG_ 1601 Motor_Code_01_CRC 0;
BA_ "GenSigSwitchedByIgnition" SG_ 1601 Motor_Code_01_BZ 0;
BA_ "GenSigFuncType" SG_ 1601 Motor_Code_01_BZ 1;
BA_ "GenSigSendType" SG_ 1601 Motor_Code_01_BZ 0;
BA_ "GenSigSwitchedByIgnition" SG_ 1601 MO_Faktor_Momente_02 0;
BA_ "GenSigFuncType" SG_ 1601 MO_Faktor_Momente_02 8;
BA_ "GenSigSendType" SG_ 1601 MO_Faktor_Momente_02 0;
BA_ "GenSigSwitchedByIgnition" SG_ 1601 MO_Hybridfahrzeug 0;
BA_ "GenSigFuncType" SG_ 1601 MO_Hybridfahrzeug 8;
BA_ "GenSigSendType" SG_ 1601 MO_Hybridfahrzeug 0;
BA_ "GenSigSwitchedByIgnition" SG_ 1601 MO_Code 0;
BA_ "GenSigSendType" SG_ 1601 MO_Code 0;
BA_ "GenSigSwitchedByIgnition" SG_ 1601 MO_Getriebe_Code 0;
BA_ "GenSigSendType" SG_ 1601 MO_Getriebe_Code 0;
BA_ "GenSigSwitchedByIgnition" SG_ 1601 MO_StartStopp_Codiert 0;
BA_ "GenSigFuncType" SG_ 1601 MO_StartStopp_Codiert 8;
BA_ "GenSigSendType" SG_ 1601 MO_StartStopp_Codiert 0;
BA_ "GenSigSwitchedByIgnition" SG_ 1601 MO_Anzeige_StSt_gueltig 0;
BA_ "GenSigSendType" SG_ 1601 MO_Anzeige_StSt_gueltig 0;
BA_ "GenSigSwitchedByIgnition" SG_ 1601 MO_Anzahl_Zyl 0;
BA_ "GenSigFuncType" SG_ 1601 MO_Anzahl_Zyl 8;
BA_ "GenSigSendType" SG_ 1601 MO_Anzahl_Zyl 0;
BA_ "GenSigSwitchedByIgnition" SG_ 1601 MO_Kraftstoffart 0;
BA_ "GenSigFuncType" SG_ 1601 MO_Kraftstoffart 8;
BA_ "GenSigSendType" SG_ 1601 MO_Kraftstoffart 0;
BA_ "GenSigSwitchedByIgnition" SG_ 1601 MO_Hubraum 0;
BA_ "GenSigFuncType" SG_ 1601 MO_Hubraum 8;
BA_ "GenSigSendType" SG_ 1601 MO_Hubraum 0;
BA_ "GenSigSwitchedByIgnition" SG_ 1601 MO_Ansaugsystem 0;
BA_ "GenSigFuncType" SG_ 1601 MO_Ansaugsystem 8;
BA_ "GenSigSendType" SG_ 1601 MO_Ansaugsystem 0;
BA_ "GenSigSwitchedByIgnition" SG_ 1601 MO_Leistung 0;
BA_ "GenSigFuncType" SG_ 1601 MO_Leistung 8;
BA_ "GenSigSendType" SG_ 1601 MO_Leistung 0;
BA_ "GenSigSwitchedByIgnition" SG_ 1601 MO_OBD_Typ 0;
BA_ "GenSigFuncType" SG_ 1601 MO_OBD_Typ 8;
BA_ "GenSigSendType" SG_ 1601 MO_OBD_Typ 0;
BA_ "GenSigSwitchedByIgnition" SG_ 1601 MO_DPF_verbaut 0;
BA_ "GenSigFuncType" SG_ 1601 MO_DPF_verbaut 8;
BA_ "GenSigSendType" SG_ 1601 MO_DPF_verbaut 0;
BA_ "GenSigSwitchedByIgnition" SG_ 1601 TSK_Codierung 0;
BA_ "GenSigStartValue" SG_ 1601 TSK_Codierung 7;
BA_ "GenSigSendType" SG_ 1601 TSK_Codierung 0;
BA_ "GenSigSwitchedByIgnition" SG_ 2600468496 NM_Gateway_CBV_AWB 0;
BA_ "GenSigSwitchedByIgnition" SG_ 2600468496 NM_Gateway_CBV_CRI 0;
BA_ "GenSigFuncType" SG_ 2600468496 NM_Gateway_CBV_CRI 8;
BA_ "GenSigSwitchedByIgnition" SG_ 2600468496 NM_Gateway_NM_State 0;
BA_ "GenSigSwitchedByIgnition" SG_ 2600468496 NM_Gateway_Car_Wakeup 0;
BA_ "GenSigSwitchedByIgnition" SG_ 2600468496 NM_Gateway_UDS_CC 0;
BA_ "GenSigSwitchedByIgnition" SG_ 2600468496 NM_Gateway_NM_aktiv_KL15 0;
BA_ "GenSigSwitchedByIgnition" SG_ 2600468496 NM_Gateway_NM_aktiv_Diagnose 0;
BA_ "GenSigSwitchedByIgnition" SG_ 2600468496 NM_Gateway_NM_aktiv_Tmin 0;
BA_ "GenSigSwitchedByIgnition" SG_ 2600468496 NM_Gateway_CAB_V10 0;
BA_ "GenSigSwitchedByIgnition" SG_ 2600469457 NM_MFL_CBV_AWB 0;
BA_ "GenSigSwitchedByIgnition" SG_ 2600469457 NM_MFL_CBV_CRI 0;
BA_ "GenSigSwitchedByIgnition" SG_ 2600469457 NM_MFL_NM_State 0;
BA_ "GenSigSwitchedByIgnition" SG_ 2600469457 NM_MFL_Car_Wakeup 0;
BA_ "GenSigSwitchedByIgnition" SG_ 2600469457 NM_MFL_UDS_CC 0;
BA_ "GenSigSwitchedByIgnition" SG_ 2600469457 NM_MFL_NM_aktiv_KL15 0;
BA_ "GenSigSwitchedByIgnition" SG_ 2600469457 NM_MFL_NM_aktiv_Diagnose 0;
BA_ "GenSigSwitchedByIgnition" SG_ 2600469457 NM_MFL_NM_aktiv_Tmin 0;
BA_ "GenSigSwitchedByIgnition" SG_ 2600469457 NM_MFL_CAB_V10 0;
BA_ "GenSigSwitchedByIgnition" SG_ 2549903409 OBDC_SSN_MFL_Req_Data 0;
BA_ "GenSigSendType" SG_ 2549903409 OBDC_SSN_MFL_Req_Data 3;
BA_ "GenSigSwitchedByIgnition" SG_ 2550034481 OBDC_SSN_MFL_Resp_Data 0;
BA_ "GenSigSendType" SG_ 2550034481 OBDC_SSN_MFL_Resp_Data 3;
BA_ "GenSigSwitchedByIgnition" SG_ 2564502513 OBDx_allOBD_Req_Data 0;
BA_ "GenSigFuncType" SG_ 2564502513 OBDx_allOBD_Req_Data 9;
BA_ "GenSigSendType" SG_ 2564502513 OBDx_allOBD_Req_Data 3;
BA_ "GenSigSwitchedByIgnition" SG_ 2589283656 ORU_EM_Anfrage_freigegebeneNetze 0;
BA_ "GenSigSendType" SG_ 2589283656 ORU_EM_Anfrage_freigegebeneNetze 3;
BA_ "GenSigSwitchedByIgnition" SG_ 2589283656 ORU_EM_Anfrage_Stromaufnahme 0;
BA_ "GenSigSendType" SG_ 2589283656 ORU_EM_Anfrage_Stromaufnahme 3;
BA_ "GenSigSwitchedByIgnition" SG_ 2589283656 ORU_EM_Anfrage_Flashdauer 0;
BA_ "GenSigSendType" SG_ 2589283656 ORU_EM_Anfrage_Flashdauer 3;
BA_ "GenSigSwitchedByIgnition" SG_ 2589283656 ORU_Warnung 0;
BA_ "GenSigSendType" SG_ 2589283656 ORU_Warnung 3;
BA_ "GenSigSwitchedByIgnition" SG_ 2589283656 ORU_Status 0;
BA_ "GenSigSendType" SG_ 2589283656 ORU_Status 3;
BA_ "GenSigSwitchedByIgnition" SG_ 1413 SI_Sammel_SG_Fehler 0;
BA_ "GenSigStartValue" SG_ 1413 SI_Sammel_SG_Fehler 63;
BA_ "GenSigSendType" SG_ 1413 SI_Sammel_SG_Fehler 0;
BA_ "GenSigSwitchedByIgnition" SG_ 1413 SI_P_Mode_gueltig 0;
BA_ "GenSigSendType" SG_ 1413 SI_P_Mode_gueltig 3;
BA_ "GenSigSwitchedByIgnition" SG_ 1413 SI_Diagnose_Aktiv 0;
BA_ "GenSigSendType" SG_ 1413 SI_Diagnose_Aktiv 3;
BA_ "GenSigSwitchedByIgnition" SG_ 1413 SI_QRS_Mode 0;
BA_ "GenSigSendType" SG_ 1413 SI_QRS_Mode 3;
BA_ "GenSigSwitchedByIgnition" SG_ 1413 SI_T_Mode 0;
BA_ "GenSigSendType" SG_ 1413 SI_T_Mode 3;
BA_ "GenSigSwitchedByIgnition" SG_ 1413 SI_NWDF 0;
BA_ "GenSigSendType" SG_ 1413 SI_NWDF 3;
BA_ "GenSigSwitchedByIgnition" SG_ 1413 SI_NWDF_gueltig 0;
BA_ "GenSigFuncType" SG_ 1413 SI_NWDF_gueltig 8;
BA_ "GenSigSendType" SG_ 1413 SI_NWDF_gueltig 3;
BA_ "GenSigSwitchedByIgnition" SG_ 1413 SI_Sammelfehler 0;
BA_ "GenSigSendType" SG_ 1413 SI_Sammelfehler 3;
BA_ "GenSigSendType" SG_ 1413 GW_KD_Fehler 3;
BA_ "GenSigSwitchedByIgnition" SG_ 1413 SI_T_Schutz 0;
BA_ "GenSigSendType" SG_ 1413 SI_T_Schutz 3;
BA_ "GenSigSwitchedByIgnition" SG_ 1413 SI_P_Mode 0;
BA_ "GenSigSendType" SG_ 1413 SI_P_Mode 3;
BA_ "GenSigSwitchedByIgnition" SG_ 1413 SI_BUS_01 0;
BA_ "GenSigStartValue" SG_ 1413 SI_BUS_01 1;
BA_ "GenSigSendType" SG_ 1413 SI_BUS_01 3;
BA_ "GenSigSwitchedByIgnition" SG_ 1413 SI_BUS_02 0;
BA_ "GenSigStartValue" SG_ 1413 SI_BUS_02 1;
BA_ "GenSigSendType" SG_ 1413 SI_BUS_02 3;
BA_ "GenSigSwitchedByIgnition" SG_ 1413 SI_BUS_03 0;
BA_ "GenSigStartValue" SG_ 1413 SI_BUS_03 1;
BA_ "GenSigSendType" SG_ 1413 SI_BUS_03 3;
BA_ "GenSigSwitchedByIgnition" SG_ 1413 SI_BUS_04 0;
BA_ "GenSigStartValue" SG_ 1413 SI_BUS_04 1;
BA_ "GenSigSendType" SG_ 1413 SI_BUS_04 3;
BA_ "GenSigSwitchedByIgnition" SG_ 1413 SI_BUS_05 0;
BA_ "GenSigStartValue" SG_ 1413 SI_BUS_05 1;
BA_ "GenSigSendType" SG_ 1413 SI_BUS_05 3;
BA_ "GenSigSwitchedByIgnition" SG_ 1413 SI_BUS_06 0;
BA_ "GenSigStartValue" SG_ 1413 SI_BUS_06 1;
BA_ "GenSigSendType" SG_ 1413 SI_BUS_06 3;
BA_ "GenSigSwitchedByIgnition" SG_ 1413 SI_BUS_07 0;
BA_ "GenSigStartValue" SG_ 1413 SI_BUS_07 1;
BA_ "GenSigSendType" SG_ 1413 SI_BUS_07 3;
BA_ "GenSigSwitchedByIgnition" SG_ 1413 SI_BUS_08 0;
BA_ "GenSigStartValue" SG_ 1413 SI_BUS_08 1;
BA_ "GenSigSendType" SG_ 1413 SI_BUS_08 3;
BA_ "GenSigSwitchedByIgnition" SG_ 1413 SI_BUS_09 0;
BA_ "GenSigStartValue" SG_ 1413 SI_BUS_09 1;
BA_ "GenSigSendType" SG_ 1413 SI_BUS_09 3;
BA_ "GenSigSwitchedByIgnition" SG_ 1413 SI_BUS_10 0;
BA_ "GenSigStartValue" SG_ 1413 SI_BUS_10 1;
BA_ "GenSigSendType" SG_ 1413 SI_BUS_10 3;
BA_ "GenSigSwitchedByIgnition" SG_ 1413 SI_BUS_11 0;
BA_ "GenSigStartValue" SG_ 1413 SI_BUS_11 1;
BA_ "GenSigSendType" SG_ 1413 SI_BUS_11 3;
BA_ "GenSigSwitchedByIgnition" SG_ 1413 SI_BUS_12 0;
BA_ "GenSigStartValue" SG_ 1413 SI_BUS_12 1;
BA_ "GenSigSendType" SG_ 1413 SI_BUS_12 3;
BA_ "GenSigSwitchedByIgnition" SG_ 1413 SI_BUS_13 0;
BA_ "GenSigStartValue" SG_ 1413 SI_BUS_13 1;
BA_ "GenSigSendType" SG_ 1413 SI_BUS_13 3;
BA_ "GenSigSwitchedByIgnition" SG_ 1413 SI_BUS_14 0;
BA_ "GenSigStartValue" SG_ 1413 SI_BUS_14 1;
BA_ "GenSigSendType" SG_ 1413 SI_BUS_14 3;
BA_ "GenSigSwitchedByIgnition" SG_ 1413 SI_BUS_15 0;
BA_ "GenSigStartValue" SG_ 1413 SI_BUS_15 1;
BA_ "GenSigSendType" SG_ 1413 SI_BUS_15 3;
BA_ "GenSigSwitchedByIgnition" SG_ 1413 SI_Bus_Identifikation 0;
BA_ "GenSigSendType" SG_ 1413 SI_Bus_Identifikation 0;
BA_ "GenSigSwitchedByIgnition" SG_ 1413 SI_CAB_V10 0;
BA_ "GenSigSendType" SG_ 1413 SI_CAB_V10 3;
BA_ "GenSigSendType" SG_ 619 TA_ACC_Sollstatus 3;
BA_ "GenSigSendType" SG_ 619 TA_Status 0;
BA_ "GenSigSwitchedByIgnition" SG_ 619 TA_Spurwechsel 0;
BA_ "GenSigSendType" SG_ 619 TA_Spurwechsel 0;
BA_ "GenSigSendType" SG_ 619 TA_Texte 0;
BA_ "GenSigSwitchedByIgnition" SG_ 619 TA_FoD_Status 0;
BA_ "GenSigSendType" SG_ 619 TA_FoD_Status 3;
BA_ "GenSigSwitchedByIgnition" SG_ 619 TA_Spurwechsel_Ready 0;
BA_ "GenSigSendType" SG_ 619 TA_Spurwechsel_Ready 3;
BA_ "Fehlerwert" SG_ 2463978710 OPS_ComfortReadyStatus 3;
BA_ "GenSigSwitchedByIgnition" SG_ 2463978710 OPS_ComfortReadyStatus 0;
BA_ "GenSigSendType" SG_ 2463978710 OPS_ComfortReadyStatus 4;
BA_ "Fehlerwert" SG_ 2463978710 OPS_OccupantPresenceStatus 7;
BA_ "GenSigSwitchedByIgnition" SG_ 2463978710 OPS_OccupantPresenceStatus 0;
BA_ "GenSigSendType" SG_ 2463978710 OPS_OccupantPresenceStatus 4;
BA_ "Fehlerwert" SG_ 2463978710 OPS_DriverPresenceStatus 15;
BA_ "GenSigSwitchedByIgnition" SG_ 2463978710 OPS_DriverPresenceStatus 0;
BA_ "GenSigSendType" SG_ 2463978710 OPS_DriverPresenceStatus 4;
BA_ "GenSigSwitchedByIgnition" SG_ 2463978710 OPS_QBit_DriverPresence 0;
BA_ "GenSigStartValue" SG_ 2463978710 OPS_QBit_DriverPresence 1;
BA_ "GenSigSendType" SG_ 2463978710 OPS_QBit_DriverPresence 4;
BA_REL_ "GenSigTimeoutTime" BU_SG_REL_ MFL_CAN SG_ 679 ACC_Status_GRA_Modus 600;
BA_REL_ "GenSigTimeoutTime" BU_SG_REL_ MFL_CAN SG_ 680 ACC_FoD_Status 600;
BA_REL_ "GenSigTimeoutTime" BU_SG_REL_ MFL_CAN SG_ 1520 DI_KL_58xd 2000;
BA_REL_ "GenSigTimeoutTime" BU_SG_REL_ MFL_CAN SG_ 1520 DI_KL_58xt 2000;
BA_REL_ "GenSigTimeoutTime" BU_SG_REL_ MFL_CAN SG_ 988 TSK_06_alt 500;
BA_REL_ "GenSigTimeoutTime" BU_SG_REL_ MFL_CAN SG_ 988 TSK_Hauptschalter_GRA_ACC 500;
BA_REL_ "GenSigTimeoutTime" BU_SG_REL_ MFL_CAN SG_ 988 TSK_Limiter_ausgewaehlt 500;
BA_REL_ "GenSigTimeoutTime" BU_SG_REL_ ICAS1_Gateway SG_ 299 GRA_Abbrechen 500;
BA_REL_ "GenSigTimeoutTime" BU_SG_REL_ ICAS1_Gateway SG_ 299 GRA_Limiter 500;
BA_REL_ "GenSigTimeoutTime" BU_SG_REL_ ICAS1_Gateway SG_ 299 GRA_Tip_Setzen 500;
BA_REL_ "GenSigTimeoutTime" BU_SG_REL_ ICAS1_Gateway SG_ 299 GRA_Tip_Hoch 500;
BA_REL_ "GenSigTimeoutTime" BU_SG_REL_ ICAS1_Gateway SG_ 299 GRA_Tip_Runter 500;
BA_REL_ "GenSigTimeoutTime" BU_SG_REL_ ICAS1_Gateway SG_ 299 GRA_Tip_Wiederaufnahme 500;
BA_REL_ "GenSigTimeoutTime" BU_SG_REL_ ICAS1_Gateway SG_ 299 GRA_Verstellung_Zeitluecke 500;
BA_REL_ "GenSigTimeoutTime" BU_SG_REL_ ICAS1_KommunikationsServer SG_ 299 GRA_LIM_Taste_verfuegbar 500;
BA_REL_ "GenSigTimeoutTime" BU_SG_REL_ ICAS1_Gateway SG_ 299 GRA_Tip_Stufe_2 500;
BA_REL_ "GenSigTimeoutTime" BU_SG_REL_ MFL_CAN SG_ 960 ZAS_Kl_15 1000;
BA_REL_ "GenSigTimeoutTime" BU_SG_REL_ ICAS1_Gateway SG_ 817 MFL_Tip_Down 5000;
BA_REL_ "GenSigTimeoutTime" BU_SG_REL_ ICAS1_Gateway SG_ 817 MFL_Tip_Up 5000;
BA_REL_ "GenSigTimeoutTime" BU_SG_REL_ ICAS1_Gateway SG_ 560 MFL_Beruehrungserkennung 1000;
BA_REL_ "GenSigTimeoutTime" BU_SG_REL_ MFL_CAN SG_ 2463978751 MFL_Vibrationsimpuls_rechts 5000;
BA_REL_ "GenSigTimeoutTime" BU_SG_REL_ MFL_CAN SG_ 2463978751 MFL_Vibrationsimpuls_links 5000;
BA_REL_ "GenSigTimeoutTime" BU_SG_REL_ MFL_CAN SG_ 2463978751 MFL_Tasten_Volume_benoetigt 5000;
BA_REL_ "GenSigTimeoutTime" BU_SG_REL_ MFL_CAN SG_ 2463978751 MFL_Tasten_UpDownOK_benoetigt 5000;
BA_REL_ "GenSigTimeoutTime" BU_SG_REL_ MFL_CAN SG_ 2463978751 MFL_Taste_SDS_benoetigt 5000;
BA_REL_ "GenSigTimeoutTime" BU_SG_REL_ MFL_CAN SG_ 1601 TSK_Codierung 5000;
BA_REL_ "GenSigTimeoutTime" BU_SG_REL_ MFL_CAN SG_ 2600468496 NM_Gateway_NM_State 2000;
BA_REL_ "GenSigTimeoutTime" BU_SG_REL_ ICAS1_Gateway SG_ 2600469457 NM_MFL_CBV_AWB 2000;
BA_REL_ "GenSigTimeoutTime" BU_SG_REL_ ICAS1_Gateway SG_ 2600469457 NM_MFL_CBV_CRI 2000;
BA_REL_ "GenSigTimeoutTime" BU_SG_REL_ MFL_CAN SG_ 2600469457 NM_MFL_NM_State 2000;
BA_REL_ "GenSigTimeoutTime" BU_SG_REL_ ICAS1_Gateway SG_ 2600469457 NM_MFL_Car_Wakeup 2000;
BA_REL_ "GenSigTimeoutTime" BU_SG_REL_ ICAS1_Gateway SG_ 2600469457 NM_MFL_CAB_V10 2000;
BA_REL_ "GenSigTimeoutTime" BU_SG_REL_ MFL_CAN SG_ 2589283656 ORU_Status 5000;
BA_REL_ "GenSigTimeoutTime" BU_SG_REL_ MFL_CAN SG_ 619 TA_FoD_Status 1000;
BA_REL_ "GenSigTimeoutTime" BU_SG_REL_ MFL_CAN SG_ 2463978710 OPS_ComfortReadyStatus 1000;
VAL_ 3221225472 MFL_Develop_Release 6 "Not yet released" 5 "X05a_(C1_sample)" 4 "X04a_(B3_sample)" 3 "X03a_(B2_sample)" 2 "X02a_(B1_sample)" 1 "X01a_(A1_sample)" 0 "Init" ;
VAL_ 3221225472 MFL_Develop_Variant 2 "MQB" 1 "MEB" 0 "Init" ;
VAL_ 2684350496 MFL_Develop1_Left_PicState 4 "S_ERROR" 3 "I_ERROR" 2 "SPEC_DIAG" 1 "RUN" 0 "INIT" ;
VAL_ 2684350496 MFL_Develop1_Right_PicState 4 "S_ERROR" 3 "I_ERROR" 2 "SPEC_DIAG" 1 "RUN" 0 "INIT" ;
VAL_ 2684350464 MFL_Develop_Tag 3 "Release_Build" 2 "Test_Build" 1 "Develop_Build" 0 "Init" ;
VAL_ 2684350464 MFL_Develop_Day 0 "Init" ;
VAL_ 2684350464 MFL_Develop_Minute 61 "Init" ;
VAL_ 2684350464 MFL_Develop_Hour 24 "Init" ;
VAL_ 2684350464 MFL_Develop_Month 12 "December" 11 "November" 10 "October" 9 "September" 8 "August" 7 "July" 6 "June" 5 "May" 4 "April" 3 "March" 2 "February" 1 "January" 0 "Init" ;
VAL_ 2684350464 MFL_Develop_Year 7 "2024" 6 "2023" 5 "2022" 4 "2021" 3 "2020" 2 "2019" 1 "2018" 0 "Init" ;
VAL_ 2684350464 MFL_Develop_ProjectName 1 "SWS-Touch" 0 "Init" ;
VAL_ 679 ACC_Regelgeschw 1023 "keine_Anzeige" ;
VAL_ 679 ACC_Einheit_maxSetzgeschw 0 "kmh" 1 "mph" ;
VAL_ 679 ACC_maxSetzgeschw 511 "Init_Neutralwert" ;
VAL_ 679 ACC_minRegelgeschw 255 "keine_Anzeige" ;
VAL_ 679 ACC_maxRegelgeschw 255 "keine_Anzeige" ;
VAL_ 679 ACC_Tempolimitassistent_02 0 "keine_Anzeige" 1 "Tempolimit" 2 "Gefaelle" 3 "Steigung" 4 "Kuppe" 5 "Ortsanfang" 6 "Ampel" 7 "Bahnuebergang" ;
VAL_ 679 ACC_Tempolimit_Einheit 0 "kmh_init" 1 "mph" ;
VAL_ 679 ACC_Kurvenassistent 0 "keine_Anzeige" 1 "Kreuzung" 2 "Rechtskurve" 3 "Linkskurve" 4 "Kreisverkehr" 5 "Autobahnabfahrt" 6 "Stauende" 7 "Engstelle" ;
VAL_ 679 ACC_Typ_Tachokranz 0 "Tachokranz_lang" 1 "Tachokranz_kurz" ;
VAL_ 679 ACC_RUV 0 "keine_Anzeige" 1 "RUV_aktiv_Rechtsverkehr" 2 "RUV_aktiv_Linksverkehr" ;
VAL_ 679 ACC_Tachokranz 0 "Tachokranz_nicht_beleuchtet" 1 "Tachokranz_beleuchtet" ;
VAL_ 679 ACC_Typ_Tachokranz_unten 0 "LEDs_an" 1 "LEDs_aus" ;
VAL_ 679 ACC_ENG_Texte 0 "keine_Anzeige" 1 "keine_Laenderverfuegbarkeit" 2 "nicht_verfuegbar" 3 "Geschwindigkeitsgrenze" ;
VAL_ 679 ACC_Status_GRA_Modus 0 "GRA_Modus_nicht_verfuegbar" 1 "GRA_Modus_verfuegbar_nicht_aktiv" 2 "GRA_Modus_verfuegbar_aktiv" ;
VAL_ 680 ACA_Querfuehrung_Texte 0 "keine_Anzeige" 1 "nicht_verfuegbar" 2 "keine_Sensorsicht" 3 "Fahreruebernahme" ;
VAL_ 680 ACA_Hinweistexte 0 "keine_Anzeige" 1 "QF_eingeschaltet" 2 "QF_ausgeschaltet" ;
VAL_ 680 ACC_FoD_Status 0 "Init" 1 "Funktion_inaktiv" 2 "Funktion_aktiv" ;
VAL_ 680 ACC_Texte_Abstandswarner 0 "keine_Anzeige" 1 "Systemstoerung" 2 "keine_Sensorsicht" 3 "zurzeit_eingeschraenkt" ;
VAL_ 680 ACC_Vorz_Abstandswarner 0 "keine_Anzeige" 1 "kleiner" 2 "groesser" 3 "kleiner_Warnung" ;
VAL_ 680 ACC_Texte_Sekundaeranz 0 "keine_Anzeige" 1 "Zielfahrzeug_erkannt" 2 "Rechtskurve_voraus" 3 "Linkskurve_voraus" 4 "Tempolimit_voraus" 5 "Sensorsicht" 6 "Anfahrbereit" 7 "Tempolimit_erkannt" 8 "Kreuzung_voraus" 9 "Kreisverkehr_voraus" 10 "Autobahnabfahrt_voraus" 11 "Stauende_voraus" 12 "Gefaelle_voraus" ;
VAL_ 680 ACC_Status_Anzeige 0 "ACC_GRA_Hauptschalter_aus" 1 "ACC_in_Init_nicht_bei_GRA" 2 "ACC_GRA_passiv" 3 "ACC_GRA_aktiv" 4 "ACC_GRA_im_Hintergrund_uebertreten" 5 "ACC_GRA_Abschaltreaktion" 6 "ACC_reversibel_aus_nicht_bei_GRA" 7 "ACC_GRA_irreversibel_aus" ;
VAL_ 680 ACC_Akustik_03 0 "keine_Akustik" 1 "niederpriore_Akustik" 2 "mittelpriore_Akustik" 3 "hochpriore_Akustik" 4 "hochpriore_Dauerakustik" 5 "hochpriore_Dauerakustik_02" ;
VAL_ 680 ACC_Geschw_Zielfahrzeug 1023 "Neutralwert" ;
VAL_ 680 ACC_Texte_02 0 "keine_Anzeige" 1 "ACC_zurzeit_nicht_verfuegbar" 2 "ACC_Stoerung" 3 "ACC_keine_Sensorsicht" 4 "ACC_Steigung_zu_gross" 5 "ACC_nur_in_Fahrstufe_verfuegbar" 6 "ACC_Parkbremse_betaetigt" 7 "ACC_ESP_Eingriff" 8 "ACC_HDC_betaetigt" 9 "ACC_Geschwindigkeitsgrenze" 10 "ACC_Schalthebelposition" 11 "ACC_Drehzahl" 12 "ACC_Kupplung_betaetigt" 13 "ACC_ESC_aus" 14 "ACC_Bitte_uebernehmen" 15 "ACC_Aktivierverhinderung" 16 "ACC_eingeschraenkte_Funktion" 17 "ACC_Manoevrierassistent_aktiv" 18 "ACC_Parkassistent_aktiv" 19 "ACC_Stehendes_Objekt_voraus" 20 "ACC_aus" 21 "ACC_startet" 22 "ACC_Tuer_offen" 23 "ACC_Fahrer_Gurtschloss_offen" 25 "ACC_Abschaltung" 26 "ACC_Charisma_Modus_inkompatibel" 27 "ACC_verfuegbar" 28 "ACC_und_GRA_nicht_verfuegbar" 29 "Fehler_ACC_und_GRA" 30 "GRA_deaktiviert" 31 "keine_Abstandsregelung" 32 "GRA_zurzeit_nicht_verfuegbar" 33 "Fehler_GRA" 34 "ACC_nicht_ueber_FOD_freigeschalt" ;
VAL_ 680 ACC_STA_Text 0 "ACC_Text" 1 "ACC_STA_Text" ;
VAL_ 680 ACC_Status_Stauende 0 "deaktiviert" 1 "aktiviert" ;
VAL_ 680 STA_Texte 0 "keine_Anzeige" 1 "STA_nicht_verfuegbar" 2 "STA_Fahreruebernahme" 3 "STA_Constant_brake_mode" 4 "STA_Gurtschloss_nicht_gesteckt" 5 "STA_Fahrzeugeschw_zu_hoch" 6 "STA_Freifahrt" 7 "STA_Systemgrenze" ;
VAL_ 680 AbstWarn_LRR_FAS_Fkt_Status 0 "Init" 1 "Funktion_Ist_Ein" 2 "Funktion_Ist_Aus" 3 "Fehler" ;
VAL_ 680 STA_Zusatzanz 0 "keine_Anzeige" 1 "STA_verfuegbar" 2 "STA_aktiv" 3 "STA_Warnung" ;
VAL_ 680 FAS_Licht_Anf 0 "keine_Anforderung" 1 "Anforderung" ;
VAL_ 680 ACC_Zeitluecke_Abstandswarner 61 "Freifahrt" 62 "nicht_definiert" 63 "keine_Anzeige" ;
VAL_ 680 ACC_Abstand_Abstandswarner 509 "Freifahrt" 510 "nicht_definiert" 511 "keine_Anzeige" ;
VAL_ 680 ACC_Einheit_Abstandswarner 0 "Meter" 1 "Yard" ;
VAL_ 1714 DGN_Verlernzaehler 255 "ungültiger Zählerstand oder kein gültiger Fahrzyklus" ;
VAL_ 1714 KBI_Kilometerstand 1048574 "Init" 1048575 "Fehler" ;
VAL_ 1714 UH_Monat 0 "Init" 14 "Relatives_Datum" 15 "Fehler" ;
VAL_ 1714 UH_Tag 0 "Init" ;
VAL_ 1714 Vehicle_Driving_Cycle 0 "kein_Driving_Cycle_erkannt" 1 "Driving_Cycle_erkannt" ;
VAL_ 1714 Kombi_02_alt 0 "aktuell" 1 "veraltet" ;
VAL_ 1714 Uhrzeit_01_alt 0 "aktuell" 1 "veraltet" ;
VAL_ 1520 DI_KL_58xd 254 "Init" 255 "Fehler" ;
VAL_ 1520 DI_KL_58xs 126 "Init" 127 "Fehler" ;
VAL_ 1520 DI_KL_58xt 126 "Init" 127 "Fehler" ;
VAL_ 1520 BCM1_Stellgroesse_Kl_58s 125 "Nicht_verbaut" 126 "Init" 127 "Fehler" ;
VAL_ 988 Motor_12_alt 0 "aktuell" 1 "veraltet" ;
VAL_ 988 ESP_07_alt 0 "aktuell" 1 "veraltet" ;
VAL_ 988 Getriebe_11_alt 0 "aktuell" 1 "veraltet" ;
VAL_ 988 Getriebe_13_alt 0 "aktuell" 1 "veraltet" ;
VAL_ 988 Getriebe_17_alt 0 "aktuell" 1 "veraltet" ;
VAL_ 988 TSK_06_alt 0 "aktuell" 1 "veraltet" ;
VAL_ 988 Getriebe_14_alt 0 "aktuell" 1 "veraltet" ;
VAL_ 988 ESP_50_alt 0 "aktuell" 1 "veraltet" ;
VAL_ 988 MO_QBit_Drehzahl_01 0 "gueltiger_Wert" 1 "Ersatz_Init_oder_Fehlerwert" ;
VAL_ 988 MKE_Texte 0 "keine_Anzeige" 1 "Warnstufe_1" 2 "Warnstufe_2" ;
VAL_ 988 MKE_Stufe 0 "deaktiviert" 1 "nicht_verfügbar" 2 "Stufe_1" 3 "Stufe_2" 4 "Stufe_3" 5 "Stufe_4" 6 "reserviert" 7 "reserviert" ;
VAL_ 988 TSK_Hauptschalter_GRA_ACC 0 "Init" 1 "Aus" 2 "Ein" 3 "Fehler" ;
VAL_ 988 GE_Fahrstufe 0 "Zwischenstellung" 1 "Init" 5 "Position_P" 6 "Position_R" 7 "Position_N" 8 "Position_D" 9 "Position_S" 10 "Effizienz" 13 "Tipp_in_S" 14 "Tipp_in_D" 15 "Fehler" ;
VAL_ 988 GE_Ursache_Fahrstufe_N 0 "Fahrstufe_N_mit_Fahrerwunsch" 1 "Fahrstufe_N_ohne_Fahrerwunsch" ;
VAL_ 988 GE_Notlauf 0 "kein Notlauf / Init" 1 "Getriebe im Notlauf" ;
VAL_ 988 ESP_Rollenmodus_Deaktivieren 0 "keine_Aenderung" 1 "Abbruch" ;
VAL_ 988 GE_Freilauf_Status 0 "Freilauf_inaktiv_aber_moeglich" 1 "Freilauf_aktiv" 2 "Freilauf_nicht_moegl_1Verhinderer" 3 "Freilauf_nicht_moegl_gr_1Verhinderer" 7 "Fehler" ;
VAL_ 988 GE_Sperr_Info_WFS 0 "nicht_gesperrt" 1 "gesperrt" ;
VAL_ 988 TSK_Limiter_ausgewaehlt 0 "kein_Limiter_ausgewaehlt" 1 "Limiter_ausgewaehlt" ;
VAL_ 988 EPB_Status_02 0 "offen" 1 "geschlossen_Parken" 2 "teilgespannt_Halten" 3 "im_Lauf_oeffnen" 4 "im_Lauf_schliessen" 5 "tbd" 6 "Init" 7 "unbekannt" ;
VAL_ 988 ACC_Status_ACC 0 "ACC_OFF_Hauptschalter_aus" 1 "ACC_INIT" 2 "ACC_STANDBY" 3 "ACC_AKTIV_regelt" 4 "ACC_OVERRIDE" 5 "ACC_Abschaltreaktion" 6 "reversibler_Fehler_im_ACC_System" 7 "irreversibler_Fehler_im_ACC_System" ;
VAL_ 988 ACC_18_alt 0 "aktuell" 1 "veraltet" ;
VAL_ 988 ESP_Status_Bremsentemp_02 0 "nicht_erhoeht" 1 "Schwelle_1" 2 "Schwelle_2" ;
VAL_ 299 GRA_Hauptschalter 0 "Hauptschalter_aus__Taster_nicht_betaetigt" 1 "Hauptschalter_ein__Taster_betaetigt" ;
VAL_ 299 GRA_Abbrechen 0 "nicht_betaetigt" 1 "betaetigt" ;
VAL_ 299 GRA_Typ_Hauptschalter 0 "gerasteter_Lenkstockschalter" 1 "getasteter_Lenkstockschalter" ;
VAL_ 299 GRA_Limiter 0 "nicht_betaetigt" 1 "betaetigt" ;
VAL_ 299 GRA_Tip_Setzen 0 "nicht_betaetigt" 1 "betaetigt" ;
VAL_ 299 GRA_Tip_Hoch 0 "nicht_betaetigt" 1 "betaetigt" ;
VAL_ 299 GRA_Tip_Runter 0 "nicht_betaetigt" 1 "betaetigt" ;
VAL_ 299 GRA_Tip_Wiederaufnahme 0 "nicht_betaetigt" 1 "betaetigt" ;
VAL_ 299 GRA_Verstellung_Zeitluecke 0 "Taste_nicht_betaetigt" 1 "Dist_minus_1" 2 "Dist_plus_1" 3 "Dist_Toggle" ;
VAL_ 299 GRA_Codierung 0 "kein_Hebel" 1 "GRA_Hebel" 2 "ACC_Hebel" 3 "Limiter_Only" ;
VAL_ 299 GRA_Fehler 0 "kein_Fehler" 1 "Fehler" ;
VAL_ 299 GRA_LIM_Taste_verfuegbar 0 "Limiter_Taste_nicht_vorhanden" 1 "Limiter_Taste_vorhanden" ;
VAL_ 299 GRA_Tip_Stufe_2 0 "Tip_Stufe_1__keine_Betaetigung" 1 "Tip_Stufe_2" ;
VAL_ 299 GRA_Typ_Bedienteil 0 "Init" 1 "4_Positions_Bedienteil" 2 "6_Positions_Bedienteil" 3 "8_Positions_Bedienteil" 4 "PAG_5_Positions_Bedienteil" 5 "VW_MFL_Gen2" 6 "VW_MFL_Gen3" 7 "reserviert" ;
VAL_ 299 GRA_TravelAssist 0 "nicht_betaetigt" 1 "betaetigt" ;
VAL_ 960 RSt_Fahrerhinweise 0 "Init" 1 "Fahreruebernahme_Hinweis_ZAT_Automat_ohne_Gong" 2 "Fahreruebernahme_Hinweis_ZAT_Automat_mit_Gong" 3 "Fahreruebernahme_Hinweis_ZAT_Handschalter_ohne_Gong" 4 "Fahreruebernahme_Hinweis_ZAT_Handschalter_mit_Gong" 5 "Fahreruebernahme_Hinweis_ZAS_Automat_ohne_Gong" 6 "Fahreruebernahme_Hinweis_ZAS_Automat_mit_Gong" 7 "Fahreruebernahme_Hinweis_ZAS_Handschalter_ohne_Gong" 8 "Fahreruebernahme_Hinweis_ZAS_Handschalter_mit_Gong" 9 "RemoteStart_aktiv_ohne_Gong" 10 "RemoteStart_aktiv_mit_Gong" 11 "void" 12 "void" 13 "void" 14 "void" 15 "void" ;
VAL_ 960 ZAS_Kl_S 0 "aus" 1 "S_Kontakt_ein" ;
VAL_ 960 ZAS_Kl_15 0 "aus" 1 "ein" ;
VAL_ 960 ZAS_Kl_X 0 "aus" 1 "ein" ;
VAL_ 960 ZAS_Kl_50_Startanforderung 0 "aus" 1 "KL50_ein_Startwunsch_Fahrer" ;
VAL_ 960 BCM_Remotestart_Betrieb 0 "kein_RS_Betrieb" 1 "RS_Betrieb" ;
VAL_ 960 ZAS_Kl_Infotainment 0 "inaktiv" 1 "aktiv" ;
VAL_ 960 BCM_Remotestart_KL15_Anf 0 "inaktiv" 1 "aktiv" ;
VAL_ 960 BCM_Remotestart_MO_Start 0 "nicht_angefordert" 1 "angefordert" ;
VAL_ 960 KST_Warn_P1_ZST_def 0 "nicht_defekt" 1 "defekt" ;
VAL_ 960 KST_Warn_P2_ZST_def 0 "nicht_defekt" 1 "defekt" ;
VAL_ 960 KST_Fahrerhinweis_1 0 "inaktiv" 1 "aktiv" ;
VAL_ 960 KST_Fahrerhinweis_2 0 "inaktiv" 1 "aktiv" ;
VAL_ 960 BCM_Ausparken_Betrieb 0 "kein_Betrieb" 1 "Ausparkvorgang_aktiv" ;
VAL_ 960 KST_Fahrerhinweis_4 0 "inaktiv" 1 "aktiv" ;
VAL_ 960 KST_Fahrerhinweis_5 0 "inaktiv" 1 "aktiv" ;
VAL_ 960 KST_Fahrerhinweis_6 0 "inaktiv" 1 "aktiv" ;
VAL_ 822 LR_HZG_Temp_Sensor 253 "KS_Plus__Unterbrechung" 254 "Init" 255 "Tempsensor_fehlerhaft__KS_GND" ;
VAL_ 822 LR_HZG_Taster_on_off 0 "nicht_betaetigt" 1 "betaetigt" ;
VAL_ 822 LR_HZG_Konfiguration 0 "Init" 1 "Konfiguration_7" 2 "Konfiguration_6" 3 "Konfiguration_5" 4 "Konfiguration_4" 5 "Konfiguration_3" 6 "Konfiguration_2" 7 "Konfiguration_1" ;
VAL_ 817 MFL_Lokalaktiv 0 "war_nicht_lokal_aktiv" 1 "war_lokal_aktiv" ;
VAL_ 817 MFL_M_Taste 0 "nicht_betaetigt" 1 "betaetigt" ;
VAL_ 817 MFL_Paddle_Verbau 0 "verbaut" 1 "nicht_verbaut" ;
VAL_ 817 MFL_Tastencode_1 0 "Key_Released__No_Key" 1 "Context_Menu" 2 "Menu_Up__Next_Screen" 3 "Menu_Down__Previous_Screen" 4 "Up" 5 "Down" 6 "Up__Down_ThumbWheel" 7 "OK__ThumbWheel_Button" 8 "Cancel__Escape" 9 "Main_Menu" 10 "Side_Menu_left" 11 "Side_Menu_right" 12 "FAS_Menu" 13 "Left__Right_ThumbWheel" 16 "Volume_Up" 17 "Volume_Down" 18 "Volume_Up__Down_ThumbWheel" 19 "Volume_ThumbWheel_Button" 20 "Audio_Source" 21 "Arrow_A_Up__Right" 22 "Arrow_A_Down__Left" 23 "Arrow_B_Up__Right" 24 "Arrow_B_Down__Left" 25 "PTT__PushToTalk" 26 "PTT_Cancel" 27 "Route_Info" 28 "Hook" 29 "Hang_Up" 30 "Off_Hook" 31 "Light_On__Off" 32 "Mute" 33 "Joker1" 34 "Joker2" 35 "View" 36 "Arrow_A_Up__Down_ThumbWheel" 37 "Lenkradheizung" 38 "Rekuperation" 39 "Tube_Toggle" 100 "MAP" 101 "MAP_Boost" 102 "Turn_signal_left" 103 "Turn_signal_right" 104 "Turn_signal_off" 105 "Flashlight" 106 "Highbeam" 107 "Washer_button" 108 "Wiper_button_left" 109 "Wiper_button_right" 110 "Wiper_button_cancel" 111 "Exhaust_Sound" 112 "Drive_Select_button" 113 "Sport_button" 114 "ESP_Drift_Selection_ThumbWheel" 115 "PTT_special_vehicle" 116 "TravelAssist" 240 "Startup_Reset" 241 "Initialization" ;
VAL_ 817 MFL_Tastencode_2 0 "Key_Released__No_Key" 1 "Context_Menu" 2 "Menu_Up__Next_Screen" 3 "Menu_Down__Previous_Screen" 4 "Up" 5 "Down" 6 "Up__Down_ThumbWheel" 7 "OK__ThumbWheel_Button" 8 "Cancel__Escape" 9 "Main_Menu" 10 "Side_Menu_left" 11 "Side_Menu_right" 12 "FAS_Menu" 13 "Left__Right_ThumbWheel" 16 "Volume_Up" 17 "Volume_Down" 18 "Volume_Up__Down_ThumbWheel" 19 "Volume_ThumbWheel_Button" 20 "Audio_Source" 21 "Arrow_A_Up__Right" 22 "Arrow_A_Down__Left" 23 "Arrow_B_Up__Right" 24 "Arrow_B_Down__Left" 25 "PTT__PushToTalk" 26 "PTT_Cancel" 27 "Route_Info" 28 "Hook" 29 "Hang_Up" 30 "Off_Hook" 31 "Light_On__Off" 32 "Mute" 33 "Joker1" 34 "Joker2" 35 "View" 36 "Arrow_A_Up_Right_Down_Left_ThumbWheel" 37 "Lenkradheizung" 38 "Rekuperation" 39 "Tube_Toggle" 100 "MAP" 101 "MAP_Boost" 102 "Turn_signal_left" 103 "Turn_signal_right" 104 "Turn_signal_off" 105 "Flashlight" 106 "Highbeam" 107 "Washer_button" 108 "Wiper_button_left" 109 "Wiper_button_right" 110 "Wiper_button_cancel" 111 "Exhaust_Sound" 112 "Drive_Select_button" 113 "Sport_button" 114 "ESP_Drift_Selection_ThumbWheel" 115 "PTT_special_vehicle" 116 "TravelAssist" 240 "Startup_Reset" 241 "Initialization" ;
VAL_ 817 MFL_Eventcode_1 0 "W_no_event____T_no_event" 1 "W_1_Tick_up__T_pressed_normal" 2 "W_2_Ticks_up__T_touched" 3 "W_3_Ticks_up__T_double_click_nor" 4 "W_4_Ticks_up__T_long_press_nor_1" 5 "W_5_Ticks_up__T_long_press_nor_2" 6 "W_6_Ticks_up__T_long_press_nor_3" 7 "W_7_Ticks_up" 9 "W_7_Ticks_dn__T_pressed_strong" 10 "W_6_Ticks_dn" 11 "W_5_Ticks_dn__T_double_click_str" 12 "W_4_Ticks_dn__T_long_press_str_1" 13 "W_3_Ticks_dn__T_long_press_str_2" 14 "W_2_Ticks_dn__T_long_press_str_3" 15 "W_1_Tick_dn" ;
VAL_ 817 MFL_Eventcode_2 0 "W_no_event____T_no_event" 1 "W_1_Tick_up__T_pressed_normal" 2 "W_2_Ticks_up__T_touched" 3 "W_3_Ticks_up__T_double_click_nor" 4 "W_4_Ticks_up__T_long_press_nor_1" 5 "W_5_Ticks_up__T_long_press_nor_2" 6 "W_6_Ticks_up__T_long_press_nor_3" 7 "W_7_Ticks_up" 9 "W_7_Ticks_dn__T_pressed_strong" 10 "W_6_Ticks_dn" 11 "W_5_Ticks_dn__T_double_click_str" 12 "W_4_Ticks_dn__T_long_press_str_1" 13 "W_3_Ticks_dn__T_long_press_str_2" 14 "W_2_Ticks_dn__T_long_press_str_3" 15 "W_1_Tick_dn" ;
VAL_ 817 MFL_Marke 0 "VW" 1 "Audi" 2 "Seat" 3 "Skoda" 4 "VW_Nutzf" 5 "Bugatti" 6 "Lamborghini" 7 "Bentley" 8 "Rolls Royce" 9 "Quattro" 10 "kein_Hersteller_1" 11 "kein_Hersteller_2" 12 "kein_Hersteller_3" 13 "kein_Hersteller_4" 14 "Ford" 15 "Porsche" ;
VAL_ 817 MFL_Tip_Down 0 "nicht_betaetigt" 1 "betaetigt" ;
VAL_ 817 MFL_Tip_Up 0 "nicht_betaetigt" 1 "betaetigt" ;
VAL_ 817 MFL_SatModul_links_Err 0 "kein_Fehler" 1 "Fehler" ;
VAL_ 817 MFL_SatModul_rechts_Err 0 "kein_Fehler" 1 "Fehler" ;
VAL_ 817 MFL_LR_HZG_Status 0 "inaktiv" 1 "aktiv" ;
VAL_ 817 MFL_LR_HZG_Err 0 "normal" 1 "Fehler" ;
VAL_ 817 MFL_Signalhorn 0 "nicht_betaetigt" 1 "betaetigt" ;
VAL_ 817 MFL_Signalhorn_Err 0 "normal" 1 "Fehler" ;
VAL_ 817 MFL_Tip_links_Err 0 "normal" 1 "Fehler" ;
VAL_ 817 MFL_Tip_rechts_Err 0 "normal" 1 "Fehler" ;
VAL_ 817 MFL_Taste_links_Err 0 "normal" 1 "Fehler" ;
VAL_ 817 MFL_Taste_rechts_Err 0 "normal" 1 "Fehler" ;
VAL_ 817 MFL_ECU_Err 0 "normal" 1 "Fehler" ;
VAL_ 817 MFL_Response_Err 0 "normal" 1 "Fehler" ;
VAL_ 560 MFL_Beruehrungserkennung 0 "nicht_beruehrt" 1 "links" 2 "rechts" 3 "beidseitig" ;
VAL_ 2463978751 MFL_Vibrationsimpuls_rechts 0 "Kein_Impuls" 1 "Impuls_1" 2 "Impuls_2" 3 "Impuls_3" 4 "Impuls_4" 5 "Impuls_5" 6 "Impuls_6" 7 "Impuls_7" 8 "Impuls_8" 9 "Impuls_9" 10 "Impuls_10" 11 "Impuls_11" 12 "Impuls_12" 13 "Impuls_13" 14 "Impuls_14" 15 "Impuls_15" ;
VAL_ 2463978751 MFL_Vibrationsimpuls_links 0 "Kein_Impuls" 1 "Impuls_1" 2 "Impuls_2" 3 "Impuls_3" 4 "Impuls_4" 5 "Impuls_5" 6 "Impuls_6" 7 "Impuls_7" 8 "Impuls_8" 9 "Impuls_9" 10 "Impuls_10" 11 "Impuls_11" 12 "Impuls_12" 13 "Impuls_13" 14 "Impuls_14" 15 "Impuls_15" ;
VAL_ 2463978751 MFL_Tasten_Volume_benoetigt 0 "nicht_benoetigt" 1 "benoetigt" ;
VAL_ 2463978751 MFL_Tasten_UpDownOK_benoetigt 0 "nicht_benoetigt" 1 "benoetigt" ;
VAL_ 2463978751 MFL_Taste_SDS_benoetigt 0 "nicht_benoetigt" 1 "benoetigt" ;
VAL_ 1471 MFL_Tastencode_1 0 "Key_Released__No_Key" 1 "Context_Menu" 2 "Menu_Up__Next_Screen" 3 "Menu_Down__Previous_Screen" 4 "Up" 5 "Down" 6 "Up__Down_ThumbWheel" 7 "OK__ThumbWheel_Button" 8 "Cancel__Escape" 9 "Main_Menu" 10 "Side_Menu_left" 11 "Side_Menu_right" 12 "FAS_Menu" 13 "Left__Right_ThumbWheel" 16 "Volume_Up" 17 "Volume_Down" 18 "Volume_Up__Down_ThumbWheel" 19 "Volume_ThumbWheel_Button" 20 "Audio_Source" 21 "Arrow_A_Up__Right" 22 "Arrow_A_Down__Left" 23 "Arrow_B_Up__Right" 24 "Arrow_B_Down__Left" 25 "PTT__PushToTalk" 26 "PTT_Cancel" 27 "Route_Info" 28 "Hook" 29 "Hang_Up" 30 "Off_Hook" 31 "Light_On__Off" 32 "Mute" 33 "Joker1" 34 "Joker2" 35 "View" 36 "Arrow_A_Up__Down_ThumbWheel" 37 "Lenkradheizung" 38 "Rekuperation" 39 "Tube_Toggle" 100 "MAP" 101 "MAP_Boost" 102 "Turn_signal_left" 103 "Turn_signal_right" 104 "Turn_signal_off" 105 "Flashlight" 106 "Highbeam" 107 "Washer_button" 108 "Wiper_button_left" 109 "Wiper_button_right" 110 "Wiper_button_cancel" 111 "Exhaust_Sound" 112 "Drive_Select_button" 113 "Sport_button" 114 "ESP_Drift_Selection_ThumbWheel" 115 "PTT_special_vehicle" 116 "TravelAssist" 240 "Startup_Reset" 241 "Initialization" ;
VAL_ 1471 MFL_Tastencode_2 0 "Key_Released__No_Key" 1 "Context_Menu" 2 "Menu_Up__Next_Screen" 3 "Menu_Down__Previous_Screen" 4 "Up" 5 "Down" 6 "Up__Down_ThumbWheel" 7 "OK__ThumbWheel_Button" 8 "Cancel__Escape" 9 "Main_Menu" 10 "Side_Menu_left" 11 "Side_Menu_right" 12 "FAS_Menu" 13 "Left__Right_ThumbWheel" 16 "Volume_Up" 17 "Volume_Down" 18 "Volume_Up__Down_ThumbWheel" 19 "Volume_ThumbWheel_Button" 20 "Audio_Source" 21 "Arrow_A_Up__Right" 22 "Arrow_A_Down__Left" 23 "Arrow_B_Up__Right" 24 "Arrow_B_Down__Left" 25 "PTT__PushToTalk" 26 "PTT_Cancel" 27 "Route_Info" 28 "Hook" 29 "Hang_Up" 30 "Off_Hook" 31 "Light_On__Off" 32 "Mute" 33 "Joker1" 34 "Joker2" 35 "View" 36 "Arrow_A_Up_Right_Down_Left_ThumbWheel" 37 "Lenkradheizung" 38 "Rekuperation" 39 "Tube_Toggle" 100 "MAP" 101 "MAP_Boost" 102 "Turn_signal_left" 103 "Turn_signal_right" 104 "Turn_signal_off" 105 "Flashlight" 106 "Highbeam" 107 "Washer_button" 108 "Wiper_button_left" 109 "Wiper_button_right" 110 "Wiper_button_cancel" 111 "Exhaust_Sound" 112 "Drive_Select_button" 113 "Sport_button" 114 "ESP_Drift_Selection_ThumbWheel" 115 "PTT_special_vehicle" 116 "TravelAssist" 240 "Startup_Reset" 241 "Initialization" ;
VAL_ 1471 MFL_Eventcode_1 0 "W_no_event____T_no_event" 1 "W_1_Tick_up__T_pressed_normal" 2 "W_2_Ticks_up__T_touched" 3 "W_3_Ticks_up__T_double_click_nor" 4 "W_4_Ticks_up__T_long_press_nor_1" 5 "W_5_Ticks_up__T_long_press_nor_2" 6 "W_6_Ticks_up__T_long_press_nor_3" 7 "W_7_Ticks_up" 9 "W_7_Ticks_dn__T_pressed_strong" 10 "W_6_Ticks_dn" 11 "W_5_Ticks_dn__T_double_click_str" 12 "W_4_Ticks_dn__T_long_press_str_1" 13 "W_3_Ticks_dn__T_long_press_str_2" 14 "W_2_Ticks_dn__T_long_press_str_3" 15 "W_1_Tick_dn" ;
VAL_ 1471 MFL_Eventcode_2 0 "W_no_event____T_no_event" 1 "W_1_Tick_up__T_pressed_normal" 2 "W_2_Ticks_up__T_touched" 3 "W_3_Ticks_up__T_double_click_nor" 4 "W_4_Ticks_up__T_long_press_nor_1" 5 "W_5_Ticks_up__T_long_press_nor_2" 6 "W_6_Ticks_up__T_long_press_nor_3" 7 "W_7_Ticks_up" 9 "W_7_Ticks_dn__T_pressed_strong" 10 "W_6_Ticks_dn" 11 "W_5_Ticks_dn__T_double_click_str" 12 "W_4_Ticks_dn__T_long_press_str_1" 13 "W_3_Ticks_dn__T_long_press_str_2" 14 "W_2_Ticks_dn__T_long_press_str_3" 15 "W_1_Tick_dn" ;
VAL_ 1471 MFL_Marke 0 "VW" 1 "Audi" 2 "Seat" 3 "Skoda" 4 "VW_Nutzf" 5 "Bugatti" 6 "Lamborghini" 7 "Bentley" 8 "Rolls Royce" 9 "Quattro" 10 "kein_Hersteller_1" 11 "kein_Hersteller_2" 12 "kein_Hersteller_3" 13 "kein_Hersteller_4" 14 "Ford" 15 "Porsche" ;
VAL_ 1601 MO_Faktor_Momente_02 0 "nicht_belegt" ;
VAL_ 1601 MO_Hybridfahrzeug 0 "kein_Hybridfahrzeug" 1 "Mild_Hybrid" 2 "Full_Hybrid" 3 "PlugIn_Hybrid" ;
VAL_ 1601 MO_Getriebe_Code 0 "Init" 2 "DL501" 3 "DL800" 4 "VL381" 5 "DL382_Front" 6 "DL382_Allrad" 7 "DL702" 8 "AL552_Allrad" 9 "AL552_Front" 10 "AL651" 11 "AL551__AL951__AL1000_8A" 12 "PDK_PAG" 13 "AL551_Hybrid" 15 "Handschalter_konventionell" 16 "AQ250_160" 17 "AQ450" 18 "DQ200" 19 "DQ250" 20 "DQ500" 21 "SQ100" 22 "SQ200" 23 "DQ400E" 24 "DQ381" 25 "AL550" 26 "AQ300" 31 "DL800E" 32 "Single_Gear__ohne_GSG_WH_am_MSG" 33 "EQ550_2P" ;
VAL_ 1601 MO_StartStopp_Codiert 0 "Start_Stopp_nicht_verbaut" 1 "Start_Stopp_verbaut" ;
VAL_ 1601 MO_Anzeige_StSt_gueltig 0 "MO_Text_Motorstart_gueltig" 1 "Signale_MO_Anzeige_StSt_gueltig" ;
VAL_ 1601 MO_Anzahl_Zyl 0 "kein_Zylinder" 1 "1_Zylinder" 2 "2_Zylinder" 3 "3_Zylinder" 4 "4_Zylinder" 5 "5_Zylinder" 6 "6_Zylinder" 7 "7_Zylinder" 8 "8_Zylinder" 9 "9_Zylinder" 10 "10_Zylinder" 11 "11_Zylinder" 12 "12_Zylinder" 13 "15_Zylinder" 14 "16_Zylinder" 15 "18_Zylinder" ;
VAL_ 1601 MO_Kraftstoffart 0 "Diesel" 1 "Benzin_inkl_E25_E85" 2 "CNG" 3 "LPG" 4 "Wasserstoff" 5 "E100_Ethanol" 15 "kein_Verbrennungskraftstoff" ;
VAL_ 1601 MO_Ansaugsystem 0 "Turbo" 1 "Sauger" ;
VAL_ 1601 MO_OBD_Typ 0 "NoOBD_RdW" 1 "EOBD" 2 "US_OBD" 3 "reserviert" ;
VAL_ 1601 MO_DPF_verbaut 0 "kein_DPF_verbaut" 1 "DPF_verbaut" ;
VAL_ 1601 TSK_Codierung 0 "kein_Fahrgeschwindigkeitsregler" 1 "GRA" 2 "GRA_Plus" 3 "Basis_ACC" 4 "ACC_Follow_to_Stop" 5 "ACC_Stop_and_Go" 7 "Codierung_in_Plausibilisierungsphase" ;
VAL_ 2600468496 NM_Gateway_CBV_AWB 0 "Passiver_WakeUp" 1 "Aktiver_WakeUp" ;
VAL_ 2600468496 NM_Gateway_CBV_CRI 0 "Standard_Layout" 1 "TNB_Layout" ;
VAL_ 2600468496 NM_Gateway_NM_State 1 "NM_RM_aus_BSM" 2 "NM_RM_aus_PBSM" 4 "NM_NO_aus_RM" 8 "NM_NO_aus_RS" 16 "NM_RM_aus_RS" 32 "NM_RM_aus_NO" ;
VAL_ 2600468496 NM_Gateway_Car_Wakeup 0 "Inaktiv" 1 "Car_Wakeup" ;
VAL_ 2600468496 NM_Gateway_UDS_CC 0 "Init" 1 "CC_aktiv" ;
VAL_ 2600468496 NM_Gateway_NM_aktiv_KL15 0 "Inaktiv" 1 "KL15_EIN" ;
VAL_ 2600468496 NM_Gateway_NM_aktiv_Diagnose 0 "Init" 1 "Diagnose_aktiv" ;
VAL_ 2600468496 NM_Gateway_NM_aktiv_Tmin 0 "Inaktiv" 1 "Mindestaktivzeit" ;
VAL_ 2600468496 NM_Gateway_CAB_V10 0 "Init" 1 "CAB_01_Antrieb" 2 "CAB_02_Hybrid_Laden" 4 "CAB_03_Fahrwerk" 8 "CAB_04_Fahrerassistenz" 16 "CAB_05_Komfort" 32 "CAB_06_Anzeige" 64 "CAB_07_Connect" 128 "CAB_08_MIB" 256 "CAB_09_Standheizung" 1024 "CAB_11_VLAN_Fahrerassistenz" 4096 "CAB_13_VLAN_Connect" 8192 "CAB_14_VLAN_Infotainment" 16384 "CAB_15_Laden" 32768 "CAB_16_Licht" ;
VAL_ 2600469457 NM_MFL_CBV_AWB 0 "Passiver_WakeUp" 1 "Aktiver_WakeUp" ;
VAL_ 2600469457 NM_MFL_CBV_CRI 0 "Standard_Layout" 1 "TNB_Layout" ;
VAL_ 2600469457 NM_MFL_NM_State 0 "Init" 1 "NM_RM_aus_BSM" 2 "NM_RM_aus_PBSM" 4 "NM_NO_aus_RM" 8 "NM_NO_aus_RS" 16 "NM_RM_aus_RS" 32 "NM_RM_aus_NO" ;
VAL_ 2600469457 NM_MFL_Car_Wakeup 0 "Inaktiv" 1 "Car_Wakeup" ;
VAL_ 2600469457 NM_MFL_UDS_CC 0 "Init" 1 "CC_aktiv" ;
VAL_ 2600469457 NM_MFL_NM_aktiv_KL15 0 "Inaktiv" 1 "KL15_EIN" ;
VAL_ 2600469457 NM_MFL_NM_aktiv_Diagnose 0 "Init" 1 "Diagnose_aktiv" ;
VAL_ 2600469457 NM_MFL_NM_aktiv_Tmin 0 "Inaktiv" 1 "Mindestaktivzeit" ;
VAL_ 2600469457 NM_MFL_CAB_V10 0 "Init" 1 "CAB_01_Antrieb" 2 "CAB_02_Hybrid_Laden" 4 "CAB_03_Fahrwerk" 8 "CAB_04_Fahrerassistenz" 16 "CAB_05_Komfort" 32 "CAB_06_Anzeige" 64 "CAB_07_Connect" 128 "CAB_08_MIB" 256 "CAB_09_Standheizung" 1024 "CAB_11_VLAN_Fahrerassistenz" 4096 "CAB_13_VLAN_Connect" 8192 "CAB_14_VLAN_Infotainment" 16384 "CAB_15_Laden" 32768 "CAB_16_Licht" ;
VAL_ 2589283656 ORU_EM_Anfrage_freigegebeneNetze 0 "only_12V" 1 "networks_48V_and_12V" 2 "networks_HV_and_12V" 3 "networks_HV_and_48V_and_12V" ;
VAL_ 2589283656 ORU_Warnung 0 "keine_Anzeige" 1 "Update_unvollstaendig_Prio1" 2 "reserviert" 3 "reserviert" ;
VAL_ 2589283656 ORU_Status 0 "IDLE" 1 "PENDING" 2 "PREPARATION" 3 "PREPARATION_HV" 4 "RUNNING" 5 "RUNNING_HV" 6 "PENDING_NOTREADY" ;
VAL_ 1413 SI_Sammel_SG_Fehler 61 "Reserviert" 62 "Overflow" 63 "ungueltig" ;
VAL_ 1413 SI_P_Mode_gueltig 0 "dezentraler_Produktionsmode" 1 "zentraler_Produktionsmode" ;
VAL_ 1413 SI_Diagnose_Aktiv 0 "inaktiv" 1 "aktiv" ;
VAL_ 1413 SI_QRS_Mode 0 "QRS_Messmodus_nicht_aktiv" 1 "QRS_Messmodus_aktiv" ;
VAL_ 1413 SI_T_Mode 0 "Transportmodus_nicht_aktiv" 1 "Transportmodus_aktiv" ;
VAL_ 1413 SI_NWDF 0 "Ueberwachung_nicht_freigegeben" 1 "Ueberwachung_freigegeben" ;
VAL_ 1413 SI_NWDF_gueltig 0 "NWDF_wird_nicht_unterstuetzt" 1 "NWDF_wird_unterstuetzt" ;
VAL_ 1413 SI_Sammelfehler 0 "kein_Sammelfehler" 1 "Sammelfehler" ;
VAL_ 1413 GW_KD_Fehler 0 "kein_KD_Fehler" 1 "KD_Fehler" ;
VAL_ 1413 SI_T_Schutz 0 "Transportschutz_nicht_aktiv" 1 "Transportschutz_aktiv" ;
VAL_ 1413 SI_P_Mode 0 "inaktiv" 1 "aktiv" ;
VAL_ 1413 SI_BUS_01 0 "keine_Busruhe" 1 "Busruhe" ;
VAL_ 1413 SI_BUS_02 0 "keine_Busruhe" 1 "Busruhe" ;
VAL_ 1413 SI_BUS_03 0 "keine_Busruhe" 1 "Busruhe" ;
VAL_ 1413 SI_BUS_04 0 "keine_Busruhe" 1 "Busruhe" ;
VAL_ 1413 SI_BUS_05 0 "keine_Busruhe" 1 "Busruhe" ;
VAL_ 1413 SI_BUS_06 0 "keine_Busruhe" 1 "Busruhe" ;
VAL_ 1413 SI_BUS_07 0 "keine_Busruhe" 1 "Busruhe" ;
VAL_ 1413 SI_BUS_08 0 "keine_Busruhe" 1 "Busruhe" ;
VAL_ 1413 SI_BUS_09 0 "keine_Busruhe" 1 "Busruhe" ;
VAL_ 1413 SI_BUS_10 0 "keine_Busruhe" 1 "Busruhe" ;
VAL_ 1413 SI_BUS_11 0 "keine_Busruhe" 1 "Busruhe" ;
VAL_ 1413 SI_BUS_12 0 "keine_Busruhe" 1 "Busruhe" ;
VAL_ 1413 SI_BUS_13 0 "keine_Busruhe" 1 "Busruhe" ;
VAL_ 1413 SI_BUS_14 0 "keine_Busruhe" 1 "Busruhe" ;
VAL_ 1413 SI_BUS_15 0 "keine_Busruhe" 1 "Busruhe" ;
VAL_ 1413 SI_Bus_Identifikation 16 "CAN_Diagnose" 17 "CAN_Antrieb" 18 "CAN_Komfort" 19 "CAN_Infotainment" 20 "CAN_Fahrwerk" 21 "CAN_Extended" 22 "CAN_Hybrid" 23 "CAN_Lade" 24 "CAN_Kombi" 25 "CAN_Komfort_2" 26 "CAN_AFS" 33 "CAN_FahrerAssistenzSysteme" 34 "CAN_Migration" 35 "CAN_Connect" 36 "CAN_AnzeigeBedienung" 37 "CAN_ElectricalVehicle" 40 "CAN_Telematik" 41 "CAN_MFL" 48 "FlexRay_A" 49 "FlexRay_B" 97 "VLAN_FAS" 98 "VLAN_Infotainment" 99 "VLAN_Connect" 100 "VLAN_Komfort" 101 "VLAN_Antrieb" 102 "VLAN_Diagnose" 103 "VLAN_Internet" 104 "VLAN_Gateway" 105 "VLAN_Remote_FC" 106 "VLAN_Connect_2" ;
VAL_ 1413 SI_CAB_V10 0 "Init" 1 "CAB_01_Antrieb" 2 "CAB_02_Hybrid_Laden" 4 "CAB_03_Fahrwerk" 8 "CAB_04_Fahrerassistenz" 16 "CAB_05_Komfort" 32 "CAB_06_Anzeige" 64 "CAB_07_Connect" 128 "CAB_08_MIB" 256 "CAB_09_Standheizung" 1024 "CAB_11_VLAN_Fahrerassistenz" 4096 "CAB_13_VLAN_Connect" 8192 "CAB_14_VLAN_Infotainment" 16384 "CAB_15_Laden" 32768 "CAB_16_Licht" ;
VAL_ 619 TA_ACC_Sollstatus 0 "Init" 1 "ACC_aktivieren" 2 "ACC_deaktivieren" ;
VAL_ 619 TA_Status 0 "Keine_Anzeige" 1 "Passiv" 2 "Aktiv" 3 "Warnung" ;
VAL_ 619 TA_Spurwechsel 0 "Kein_Spurwechsel" 1 "Spurwechsel_links" 2 "Spurwechsel_rechts" 3 "Spurwechsel_links_on_hold" 4 "Spurwechsel_rechts_on_hold" 5 "Spurwechsel_abgebrochen" 6 "Spurw_abgebr_Lenkung_uebernehmen" ;
VAL_ 619 TA_Texte 0 "Keine_Anzeige" 1 "Nicht_verfuegbar" 2 "Keine_Sensorsicht" 3 "Fahreruebernahme" 4 "Aktivierung" 5 "Spurwechsel_nicht_verfuegbar" ;
VAL_ 619 TA_FoD_Status 0 "Init" 1 "Funktion_inaktiv" 2 "Funktion_aktiv" ;
VAL_ 619 TA_Spurwechsel_Ready 0 "nicht_moeglich" 1 "links_moeglich" 2 "rechts_moeglich" 3 "links_rechts_moeglich" ;
VAL_ 2463978710 OPS_ComfortReadyStatus 0 "Init" 1 "aktiv" 2 "inaktiv" 3 "Fehler" ;
VAL_ 2463978710 OPS_OccupantPresenceStatus 0 "Init" 1 "OccupantAbsent" 2 "reserviert" 3 "OccupantEntryExit" 4 "reserviert" 5 "OccupantPresent" 6 "OccupantPresentVerified" 7 "Fehler" ;
VAL_ 2463978710 OPS_DriverPresenceStatus 0 "Init" 1 "reserviert" 2 "DriverAbsent" 3 "reserviert" 4 "DriverEntry" 5 "reserviert" 6 "DriverPresent" 7 "reserviert" 8 "DriverPresentVerified" 9 "reserviert" 10 "reserviert" 11 "DriverExitIntent" 12 "reserviert" 13 "DriverExit" 14 "reserviert" 15 "Fehler" ;
VAL_ 2463978710 OPS_QBit_DriverPresence 0 "gueltiger_Wert" 1 "Ersatz_Init_oder_Fehlerwert" ;
